VERSION ""

NS_ :

BS_:

BU_: FUSION ZONE_FR ZONE_DR DKC

BO_ 278 FD_VCU1: 32 FUSION
 SG_ CS_VCU1_CAN4 : 7|8@0+ (1,0) [0|255] "" ZONE_FR,ZONE_DR
 SG_ RC_VCU1_CAN4 : 11|4@0+ (1,0) [0|15] "" ZONE_FR,ZONE_DR
 SG_ Dr_SeatSta : 23|2@0+ (1,0) [0|2] "" ZONE_FR,ZONE_DR,DKC
 SG_ MSA_Crl_Sta : 21|3@0+ (1,0) [0|7] "" ZONE_FR,ZONE_DR
 SG_ CC_Crl_Sta : 18|3@0+ (1,0) [0|7] "" ZONE_FR,ZONE_DR
 SG_ ShiftGearPosn : 31|3@0+ (1,0) [0|7] "" ZONE_FR,ZONE_DR
 SG_ PwrSta : 28|3@0+ (1,0) [0|5] "" ZONE_FR,ZONE_DR,DKC
 SG_ ReBrakeLPReq : 25|1@0+ (1,0) [0|1] "" ZONE_FR,ZONE_DR
 SG_ DKCTimeSN : 39|32@0+ (1,0) [0|4.294967295E9] "" ZONE_FR,ZONE_DR,DKC
 SG_ TimeSNDKCFbk : 71|32@0+ (1,0) [0|4.294967295E9] "" ZONE_FR,ZONE_DR,DKC
 SG_ EquivAccPedalSWSta : 102|1@0+ (1,0) [0|1] "" ZONE_FR,ZONE_DR
 SG_ HornCtrl : 101|1@0+ (1,0) [0|1] "" ZONE_FR,ZONE_DR
 SG_ BCM_DoorLock_Sta : 100|1@0+ (1,0) [0|1] "" ZONE_FR,ZONE_DR,DKC
 SG_ DimmerEN : 99|1@0+ (1,0) [0|1] "" ZONE_FR,ZONE_DR
 SG_ RoomLampH : 98|1@0+ (1,0) [0|1] "" ZONE_FR,ZONE_DR
 SG_ RoomLampL : 97|1@0+ (1,0) [0|1] "" ZONE_FR,ZONE_DR
 SG_ TailgateRemote : 96|2@0+ (1,0) [0|3] "" ZONE_FR,ZONE_DR
 SG_ BCM_Buzzer_Req : 110|1@0+ (1,0) [0|1] "" ZONE_FR,ZONE_DR
 SG_ LockSetting : 109|1@0+ (1,0) [0|1] "" ZONE_FR,ZONE_DR
 SG_ Dimmer : 108|7@0+ (1,0) [0|100] "%" ZONE_FR,ZONE_DR
 SG_ L_APM_WdwEnable : 117|1@0+ (1,0) [0|1] "" ZONE_FR,ZONE_DR
 SG_ CrashDetd : 116|1@0+ (1,0) [0|1] "" ZONE_FR,ZONE_DR
 SG_ AntiTheftSeatFold : 115|1@0+ (1,0) [0|1] "" ZONE_FR,ZONE_DR
 SG_ AntitheftSta : 114|2@0+ (1,0) [0|3] "" ZONE_FR,ZONE_DR,DKC
 SG_ RTurnLP : 112|1@0+ (1,0) [0|1] "" ZONE_FR,ZONE_DR
 SG_ LTurnLP : 127|1@0+ (1,0) [0|1] "" ZONE_FR,ZONE_DR
 SG_ HazardSW : 126|1@0+ (1,0) [0|1] "" ZONE_FR,ZONE_DR
 SG_ Rr_FogLamp : 125|1@0+ (1,0) [0|1] "" ZONE_FR,ZONE_DR
 SG_ Fr_FogLamp : 124|1@0+ (1,0) [0|1] "" ZONE_FR,ZONE_DR
 SG_ RBSD : 123|1@0+ (1,0) [0|1] "" ZONE_FR,ZONE_DR
 SG_ LBSD : 122|1@0+ (1,0) [0|1] "" ZONE_FR,ZONE_DR
 SG_ BrakeLamp : 121|1@0+ (1,0) [0|1] "" ZONE_FR,ZONE_DR
 SG_ ReverseLamp : 120|1@0+ (1,0) [0|1] "" ZONE_FR,ZONE_DR
 SG_ RDRL : 135|1@0+ (1,0) [0|1] "" ZONE_FR,ZONE_DR
 SG_ LDRL : 134|1@0+ (1,0) [0|1] "" ZONE_FR,ZONE_DR
 SG_ PosLamp : 133|1@0+ (1,0) [0|1] "" ZONE_FR,ZONE_DR
 SG_ H_Beam : 132|1@0+ (1,0) [0|1] "" ZONE_FR,ZONE_DR
 SG_ L_Beam : 131|1@0+ (1,0) [0|1] "" ZONE_FR,ZONE_DR
 SG_ WasherCtrl : 130|2@0+ (1,0) [0|3] "" ZONE_FR,ZONE_DR
 SG_ WiperFixMode : 128|1@0+ (1,0) [0|1] "" ZONE_FR,ZONE_DR
 SG_ Rr_Wiper : 143|1@0+ (1,0) [0|1] "" ZONE_FR,ZONE_DR
 SG_ Fr_Wiper_L : 142|1@0+ (1,0) [0|1] "" ZONE_FR,ZONE_DR
 SG_ Fr_Wiper_H : 141|1@0+ (1,0) [0|1] "" ZONE_FR,ZONE_DR
 SG_ MirrorCtrl : 140|2@0+ (1,0) [0|3] "" ZONE_FR,ZONE_DR
 SG_ TailgateHDSW : 138|1@0+ (1,0) [0|1] "" ZONE_FR,ZONE_DR,DKC
 SG_ TrunkRel : 137|1@0+ (1,0) [0|1] "" ZONE_FR,ZONE_DR
 SG_ Rr_Defog : 136|1@0+ (1,0) [0|1] "" ZONE_FR,ZONE_DR
 SG_ MirrorDefog : 151|1@0+ (1,0) [0|1] "" ZONE_FR,ZONE_DR
 SG_ CTDUnlockSW : 150|1@0+ (1,0) [0|1] "" ZONE_FR,ZONE_DR
 SG_ CTDLockSW : 149|1@0+ (1,0) [0|1] "" ZONE_FR,ZONE_DR
 SG_ Rr_ChargingDoorCtrl : 148|2@0+ (1,0) [0|3] "" ZONE_FR,ZONE_DR
 SG_ Fr_ChargingDoorCtrl : 146|2@0+ (1,0) [0|3] "" ZONE_FR,ZONE_DR
 SG_ CTDCtrl : 144|2@0+ (1,0) [0|3] "" ZONE_FR,ZONE_DR
 SG_ Tailgate_SW : 158|1@0+ (1,0) [0|1] "" ZONE_FR,ZONE_DR,DKC
 SG_ HoodSW : 157|1@0+ (1,0) [0|1] "" ZONE_FR,ZONE_DR,DKC
 SG_ DoorLockIND : 156|1@0+ (1,0) [0|1] "" ZONE_FR,ZONE_DR
 SG_ AllDoorSW : 155|1@0+ (1,0) [0|1] "" ZONE_FR,ZONE_DR,DKC
 SG_ RRDoorSW : 154|1@0+ (1,0) [0|1] "" ZONE_FR,ZONE_DR,DKC
 SG_ RLDoorSW : 153|1@0+ (1,0) [0|1] "" ZONE_FR,ZONE_DR,DKC
 SG_ PsDoorSW : 152|1@0+ (1,0) [0|1] "" ZONE_FR,ZONE_DR,DKC
 SG_ DrDoorSW : 167|1@0+ (1,0) [0|1] "" ZONE_FR,ZONE_DR,DKC
 SG_ FD_TBOX_VehData_Sta : 166|4@0+ (1,0) [0|7] "" ZONE_FR,ZONE_DR
 SG_ FD_TBOX_VehData_Err : 162|4@0+ (1,0) [0|7] "" ZONE_FR,ZONE_DR
 SG_ FD_DKC_VehData_Sta : 174|4@0+ (1,0) [0|7] "" ZONE_FR,ZONE_DR,DKC
 SG_ FD_DKC_VehData_Err : 170|4@0+ (1,0) [0|7] "" ZONE_FR,ZONE_DR,DKC
 SG_ FD_TBOX_DTCData_Sta : 182|4@0+ (1,0) [0|7] "" ZONE_FR,ZONE_DR
 SG_ FD_TBOX_DTCData_Err : 178|4@0+ (1,0) [0|7] "" ZONE_FR,ZONE_DR
 SG_ AmbLightBreath3 : 190|1@0+ (1,0) [0|1] "" ZONE_FR,ZONE_DR
 SG_ AmbLightBreath2 : 189|1@0+ (1,0) [0|1] "" ZONE_FR,ZONE_DR
 SG_ LampPwr : 188|1@0+ (1,0) [0|1] "" ZONE_FR,ZONE_DR
 SG_ AmbLightBreath1 : 187|1@0+ (1,0) [0|1] "" ZONE_FR,ZONE_DR
 SG_ DKCAuthSta : 185|2@0+ (1,0) [0|3] "" ZONE_FR,ZONE_DR,DKC
 SG_ AmbLightColor3 : 197|6@0+ (1,0) [0|63] "" ZONE_FR,ZONE_DR
 SG_ AmbLightColor2 : 205|6@0+ (1,0) [0|63] "" ZONE_FR,ZONE_DR
 SG_ AmbLightColor1 : 213|6@0+ (1,0) [0|63] "" ZONE_FR,ZONE_DR
 SG_ AmbLightBrightness3 : 222|7@0+ (1,0) [0|127] "" ZONE_FR,ZONE_DR
 SG_ AmbLightBrightness2 : 230|7@0+ (1,0) [0|127] "" ZONE_FR,ZONE_DR
 SG_ AmbLightBrightness1 : 238|7@0+ (1,0) [0|127] "" ZONE_FR,ZONE_DR
 SG_ VehSpeed : 243|12@0+ (0.125,0) [0|255.875] "km/h" ZONE_FR,ZONE_DR,DKC
 SG_ HWResetSta : 207|2@0+ (1,0) [0|3] "" ZONE_FR,ZONE_DR
 SG_ CtrlFrPwrStbA1P : 215|1@0+ (1,0) [0|1] "" ZONE_FR
 SG_ CtrlFrIRC1 : 223|1@0+ (1,0) [0|1] "" ZONE_FR
 SG_ CtrlFrBMSCCUCIR : 239|1@0+ (1,0) [0|1] "" ZONE_FR
 SG_ CtrlFrEDUINVERTER : 231|1@0+ (1,0) [0|1] "" ZONE_FR
 SG_ CtrlDrPwrStbA2 : 214|1@0+ (1,0) [0|1] "" ZONE_DR

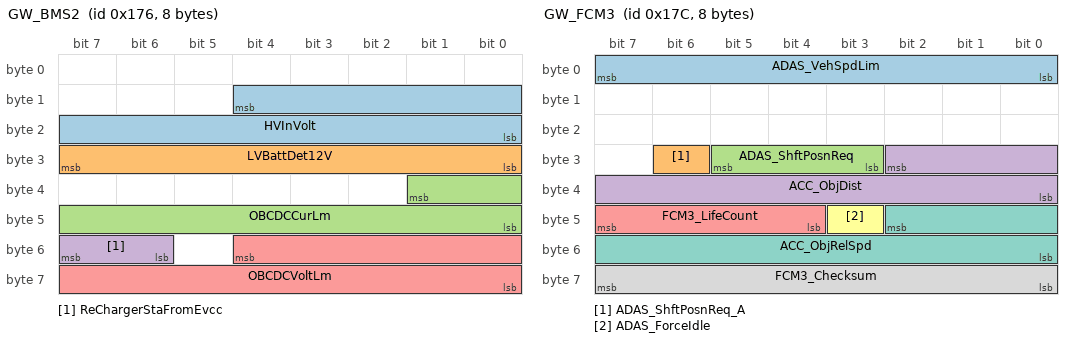
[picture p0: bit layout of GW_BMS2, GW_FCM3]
BO_ 374 GW_BMS2: 8 FUSION
 SG_ HVInVolt : 12|13@0+ (0.1,0) [0|819] "V" ZONE_DR
 SG_ LVBattDet12V : 31|8@0+ (0.1,0) [0|25.4] "V" ZONE_DR
 SG_ OBCDCCurLm : 33|10@0+ (0.1,-25.5) [-25.5|76.7] "A" ZONE_DR
 SG_ ReChargerStaFromEvcc : 55|2@0+ (1,0) [0|3] "" ZONE_DR
 SG_ OBCDCVoltLm : 52|13@0+ (0.1,0) [0|819] "V" ZONE_DR

BO_ 378 GW_BMS6: 12 FUSION
 SG_ BMSChckSum : 7|8@0+ (1,0) [0|255] "" Vector__XXX
 SG_ BMSRolCnct : 15|4@0+ (1,0) [0|15] "" Vector__XXX
 SG_ V2LSta : 25|2@0+ (1,0) [0|3] "" Vector__XXX
 SG_ HVBChrgErr : 39|8@0+ (1,0) [0|255] "" Vector__XXX
 SG_ DisChrgPlugErr : 47|2@0+ (1,0) [0|3] "" Vector__XXX
 SG_ ChrgInLockReq : 45|2@0+ (1,0) [0|2] "" ZONE_FR
 SG_ HVBCellUnbalanErr : 42|1@0+ (1,0) [0|1] "" Vector__XXX
 SG_ HVBCellUndrVoltErr : 41|1@0+ (1,0) [0|1] "" Vector__XXX
 SG_ HVBCellOvrVoltErr : 40|1@0+ (1,0) [0|1] "" Vector__XXX
 SG_ HVBCellUdrVoltWarn : 55|2@0+ (1,0) [0|2] "" Vector__XXX
 SG_ HVBCellOvrVoltWarn : 53|2@0+ (1,0) [0|2] "" Vector__XXX
 SG_ CellUnconsistErr : 50|1@0+ (1,0) [0|1] "" Vector__XXX
 SG_ SystemUncomErr : 49|1@0+ (1,0) [0|1] "" Vector__XXX
 SG_ IsoDetSta : 48|1@0+ (1,0) [0|1] "" Vector__XXX
 SG_ HVBPreheatPrecoolSta : 63|2@0+ (1,0) [0|2] "" Vector__XXX
 SG_ ExtChrgSta : 61|2@0+ (1,0) [0|3] "" Vector__XXX
 SG_ ChrgPlugSta : 59|2@0+ (1,0) [0|3] "" Vector__XXX
 SG_ HVBattReady4Pre : 57|2@0+ (1,0) [0|2] "" Vector__XXX
 SG_ HVILSta : 71|1@0+ (1,0) [0|1] "" Vector__XXX
 SG_ HVBTempDiffErr : 70|1@0+ (1,0) [0|1] "" Vector__XXX
 SG_ HVBPrechrgSta : 69|2@0+ (1,0) [0|3] "" Vector__XXX
 SG_ HVBContactorSta : 66|1@0+ (1,0) [0|1] "" Vector__XXX
 SG_ BMS_READY : 65|1@0+ (1,0) [0|1] "" Vector__XXX
 SG_ DCChrgSysShockErr : 64|1@0+ (1,0) [0|1] "" Vector__XXX
 SG_ HVBHVILErr : 79|1@0+ (1,0) [0|1] "" Vector__XXX
 SG_ HVBSOCJumpError : 78|1@0+ (1,0) [0|1] "" Vector__XXX
 SG_ HVBUndrSOCErr : 77|1@0+ (1,0) [0|1] "" Vector__XXX
 SG_ HVBOvrSOCErr : 76|1@0+ (1,0) [0|1] "" Vector__XXX
 SG_ HVBUndrTempErr : 75|1@0+ (1,0) [0|1] "" Vector__XXX
 SG_ HVBOvrTempErr : 74|1@0+ (1,0) [0|1] "" Vector__XXX
 SG_ HVBOvrDchrgCurErr : 73|1@0+ (1,0) [0|1] "" Vector__XXX
 SG_ HVBOvrChrgCurrErr : 72|1@0+ (1,0) [0|1] "" Vector__XXX
 SG_ HVBShrtDischrgCurrErr : 87|1@0+ (1,0) [0|1] "" Vector__XXX
 SG_ HVBShrtChrgCurrErr : 86|1@0+ (1,0) [0|1] "" Vector__XXX
 SG_ HVBUndrVoltErr : 85|1@0+ (1,0) [0|1] "" Vector__XXX
 SG_ HVBOvrVoltErr : 84|1@0+ (1,0) [0|1] "" Vector__XXX
 SG_ HVBUndrTempWarn : 83|2@0+ (1,0) [0|2] "" Vector__XXX
 SG_ HVBOvrTempWarn : 81|2@0+ (1,0) [0|2] "" Vector__XXX
 SG_ BMS_Warn_8 : 95|1@0+ (1,0) [0|1] "" Vector__XXX
 SG_ BMS_Warn_7 : 94|1@0+ (1,0) [0|1] "" Vector__XXX
 SG_ BMS_Warn_6 : 93|1@0+ (1,0) [0|1] "" Vector__XXX
 SG_ BMS_Warn_5 : 92|1@0+ (1,0) [0|1] "" Vector__XXX
 SG_ BMS_Warn_4 : 91|1@0+ (1,0) [0|1] "" Vector__XXX
 SG_ BMS_Warn_3 : 90|1@0+ (1,0) [0|1] "" Vector__XXX
 SG_ BMS_Warn_2 : 89|1@0+ (1,0) [0|1] "" Vector__XXX
 SG_ BMS_Warn_1 : 88|1@0+ (1,0) [0|1] "" Vector__XXX

BO_ 380 GW_FCM3: 8 FUSION
 SG_ ADAS_VehSpdLim : 7|8@0+ (1,0) [0|254] "" ZONE_DR
 SG_ ADAS_ShftPosnReq_A : 30|1@0+ (1,0) [0|1] "" Vector__XXX
 SG_ ADAS_ShftPosnReq : 29|3@0+ (1,0) [0|7] "" Vector__XXX
 SG_ ACC_ObjDist : 26|11@0+ (0.1,0) [0|204.6] "m" Vector__XXX
 SG_ FCM3_LifeCount : 47|4@0+ (1,0) [0|15] "" Vector__XXX
 SG_ ADAS_ForceIdle : 43|1@0+ (1,0) [0|1] "" Vector__XXX
 SG_ ACC_ObjRelSpd : 42|11@0+ (0.1,-100) [-100|104.6] "m/s" Vector__XXX
 SG_ FCM3_Checksum : 63|8@0+ (1,0) [0|255] "" Vector__XXX

BO_ 386 FD_THCM1: 20 FUSION
 SG_ CCU_HEATMaxLampSts : 7|1@0+ (1,0) [0|1] "" Vector__XXX
 SG_ CCU_ACLampSts : 6|1@0+ (1,0) [0|1] "" Vector__XXX
 SG_ CCU_Dispaly_Request : 5|1@0+ (1,0) [0|1] "" Vector__XXX
 SG_ CCU_EcoSts : 4|1@0+ (1,0) [0|1] "" Vector__XXX
 SG_ CCU_AutoMidLampSts : 3|1@0+ (1,0) [0|1] "" Vector__XXX
 SG_ CCU_AutoLampSts : 2|1@0+ (1,0) [0|1] "" Vector__XXX
 SG_ CCU_ACMaxLampSts : 1|1@0+ (1,0) [0|1] "" Vector__XXX
 SG_ Fr_Coolanttemp : 0|9@0+ (1,-40) [-40|214] "Deg^C" Vector__XXX
 SG_ CCU_RrOnOffLampSts : 23|1@0+ (1,0) [0|1] "" Vector__XXX
 SG_ sigWindDirZon1St : 22|3@0+ (1,0) [0|7] "" ZONE_DR
 SG_ CCU_FrtOnOffLampSts : 19|1@0+ (1,0) [0|1] "" Vector__XXX
 SG_ sigWindDirZon3St : 18|3@0+ (1,0) [0|7] "" Vector__XXX
 SG_ sigAirIntenZon1St : 31|4@0+ (1,0) [0|15] "" Vector__XXX
 SG_ sigAirIntenZon3St : 27|4@0+ (1,0) [0|15] "" Vector__XXX
 SG_ CCU_SyncLampSts : 39|1@0+ (1,0) [0|1] "" Vector__XXX
 SG_ sigDfrstSt : 38|1@0+ (1,0) [0|1] "" Vector__XXX
 SG_ sigSetTempZon3St : 37|6@0+ (0.5,17) [17|32] "Deg^C" Vector__XXX
 SG_ sigRecircSt : 47|1@0+ (1,0) [0|1] "" ZONE_DR
 SG_ sigHvacSt : 46|1@0+ (1,0) [0|1] "" Vector__XXX
 SG_ sigSetTempZon2St : 45|6@0+ (0.5,17) [17|32] "Deg^C" Vector__XXX
 SG_ HPThermalRecoveryReq : 55|2@0+ (1,0) [0|1] "" Vector__XXX
 SG_ sigSetTempZon1St : 53|6@0+ (0.5,17) [17|32] "Deg^C" Vector__XXX
 SG_ EDriveMode : 63|2@0+ (1,0) [0|2] "" Vector__XXX
 SG_ Fr_Coolantflow : 61|6@0+ (0.25,0) [0|15.75] "L/min" Vector__XXX
 SG_ sigClmtCmprPwrAct : 71|8@0+ (50,0) [0|12650] "W" Vector__XXX
 SG_ sigCbnPTCPwrAct : 79|8@0+ (50,0) [0|12650] "W" Vector__XXX
 SG_ sigCbnAirT : 87|8@0+ (0.5,-40) [-40|85] "Deg^C" Vector__XXX
 SG_ sigAmbAirT : 95|8@0+ (0.5,-40) [-40|85] "Deg^C" ZONE_FR
 SG_ sigCbnSolarRight : 103|8@0+ (5,0) [0|1265] "W" Vector__XXX
 SG_ FD_RecyAuto_Cmd : 111|3@0+ (1,0) [0|6] "" ZONE_DR
 SG_ BatteryMode : 118|3@0+ (1,0) [0|5] "" Vector__XXX
 SG_ CabinMode : 115|4@0+ (1,0) [0|9] "" ZONE_DR
 SG_ sigCbnSolarLeft : 127|8@0+ (5,0) [0|1265] "W" Vector__XXX
 SG_ sigClntTHvBattOut : 135|8@0+ (0.5,-40) [-40|85] "Deg^C" Vector__XXX
 SG_ FD_AGS_Cmd : 143|8@0+ (1,0) [0|255] "" ZONE_FR
 SG_ Rr_Coolantflow : 150|6@0+ (0.25,0) [0|15.75] "L/min" Vector__XXX
 SG_ Rr_Coolanttemp : 144|9@0+ (1,-40) [-40|214] "Deg^C" Vector__XXX

BO_ 390 FD_THCM2: 20 FUSION
 SG_ FD_Blower_Cmd : 7|8@0+ (0.8,0) [0|200] "%" ZONE_DR
 SG_ FD_SOV3_Cmd : 15|1@0+ (1,0) [0|1] "" ZONE_FR
 SG_ FD_SOV2_Cmd : 14|1@0+ (1,0) [0|1] "" ZONE_FR
 SG_ FD_SOV1_Cmd : 13|1@0+ (1,0) [0|1] "" ZONE_FR
 SG_ FD_SOTXV_Cmd : 12|1@0+ (1,0) [0|1] "" ZONE_FR
 SG_ ACSubMode : 11|3@0+ (1,0) [0|7] "" ZONE_FR,ZONE_DR
 SG_ FD_FWV_Cmd : 8|1@0+ (1,0) [0|1] "" ZONE_FR
 SG_ CCU_HiVoltageReq : 23|1@0+ (1,0) [0|1] "" Vector__XXX
 SG_ FD_Comp_Cmd : 22|15@0+ (0.5,0) [0|8300] "RPM" ZONE_FR
 SG_ CCU_CbnPreSts : 39|2@0+ (1,0) [0|3] "" Vector__XXX
 SG_ DeiceModReq : 37|2@0+ (1,0) [0|3] "" Vector__XXX
 SG_ CCU_CbnPreACWkSts : 35|2@0+ (1,0) [0|3] "" Vector__XXX
 SG_ FD_EXV1_Cmd : 33|10@0+ (1,0) [0|576] "step" ZONE_FR
 SG_ CCU_CbnPreEstimdTi : 55|6@0+ (1,0) [0|63] "" Vector__XXX
 SG_ FD_EXV2_Cmd : 49|10@0+ (1,0) [0|576] "step" ZONE_FR
 SG_ FD_TWV_Cmd : 71|8@0+ (0.392,0) [0|99.96] "%" ZONE_FR
 SG_ FD_FrRiAPTCHeatPwr_Cmd : 79|8@0+ (25,0) [0|6375] "W" ZONE_DR
 SG_ FD_FrLeAPTCHeatPwr_Cmd : 87|8@0+ (25,0) [0|6375] "W" ZONE_DR
 SG_ FD_RrAPTCHeatPwr_Cmd : 95|8@0+ (25,0) [0|6375] "W" ZONE_DR
 SG_ FD_FrWPTCHeatPwr_Cmd : 103|16@0+ (1,0) [0|65535] "W" ZONE_FR
 SG_ FD_EWP3_Cmd : 119|8@0+ (1,0) [0|255] "" ZONE_FR
 SG_ FD_EWP2_Cmd : 127|8@0+ (1,0) [0|255] "" ZONE_FR
 SG_ FD_EWP1_Cmd : 135|8@0+ (1,0) [0|255] "" ZONE_FR
 SG_ APTC_ActFrRiPwr : 143|8@0+ (25,0) [0|6375] "W" Vector__XXX
 SG_ BatLoopActWtFlw : 151|8@0+ (0.1,-5) [-5|20] "L/min" Vector__XXX
 SG_ CoolgFanActDuty : 159|8@0+ (0.5,0) [0|100] "%" ZONE_FR

BO_ 497 Zone_Dr_VCU: 20 ZONE_DR
 SG_ DrPMMSysErrLmp : 15|1@0+ (1,0) [0|1] "" FUSION
 SG_ DrPMMLVOutPErrLmp : 14|1@0+ (1,0) [0|1] "" FUSION
 SG_ DrPMMLimpHomeActReq : 13|1@0+ (1,0) [0|1] "" FUSION
 SG_ DrIVIFault : 11|2@0+ (1,0) [0|2] "" FUSION
 SG_ DrEOBDFault : 9|2@0+ (1,0) [0|2] "" FUSION
 SG_ DrInfoFault : 23|2@0+ (1,0) [0|2] "" FUSION
 SG_ DrPwrWindowECUFault : 21|2@0+ (1,0) [0|2] "" FUSION
 SG_ DrTHCMFault : 19|2@0+ (1,0) [0|2] "" FUSION
 SG_ DrColumnSWFault : 17|2@0+ (1,0) [0|2] "" FUSION
 SG_ DrAuBoxPwrN2Curr : 39|8@0+ (0.125,0) [0|31.875] "A" FUSION
 SG_ DrAuBoxPwrN1Curr : 47|8@0+ (0.125,0) [0|31.875] "A" FUSION
 SG_ DrPwrStdbyACurr : 55|8@0+ (0.125,0) [0|31.875] "A" FUSION
 SG_ DrPwrONA2Curr : 63|8@0+ (0.125,0) [0|31.875] "A" FUSION
 SG_ DrPwrONA1Curr : 71|8@0+ (0.125,0) [0|31.875] "A" FUSION
 SG_ DrCtrlBDVolt : 75|12@0+ (0.01,0) [0|36] "V" FUSION
 SG_ DrCtrlTemp : 95|16@0+ (0.01,-40) [-40|125] "Deg^C" FUSION
 SG_ DrPowerTemp1 : 111|16@0+ (0.01,-40) [-40|125] "Deg^C" FUSION
 SG_ DrPowerTemp2 : 127|16@0+ (0.01,-40) [-40|125] "Deg^C" FUSION
 SG_ DrPwrSta : 78|3@0+ (1,0) [0|5] "" FUSION
 SG_ DrPwrInformationSta : 79|1@0+ (1,0) [0|1] "" FUSION
 SG_ DrAPWStaErr : 7|1@0+ (1,0) [0|1] "" FUSION
 SG_ DrAPWLINErr : 6|1@0+ (1,0) [0|1] "" FUSION
 SG_ DrONA1ErrSta : 5|1@0+ (1,0) [0|1] "" FUSION
 SG_ DrStdAErrSta : 4|1@0+ (1,0) [0|1] "" FUSION
 SG_ DrPwrWinErrSta : 3|1@0+ (1,0) [0|1] "" FUSION
 SG_ DrInfoErrSta : 12|1@0+ (1,0) [0|1] "" FUSION
 SG_ ZoneDrMalfunLevel : 2|3@0+ (1,0) [0|5] "" FUSION
 SG_ ZDR_SYS_APMRetryCnt_Sta : 31|8@0+ (1,0) [0|255] "" FUSION
 SG_ ZDR_SYS_CSWRetryCnt_Sta : 143|8@0+ (1,0) [0|255] "" FUSION
 SG_ ZDR_SYS_BSWSleepReq_Sta : 150|1@0+ (1,0) [0|1] "" FUSION
 SG_ ZDR_VCU_HWReset_Sta : 148|5@0+ (1,0) [0|31] "" FUSION
 SG_ ZDR_VCU_PwrSupply_Sta : 149|1@0+ (1,0) [0|1] "" FUSION

BO_ 498 Zone_Fr_VCU: 24 ZONE_FR
 SG_ FrPwrStdbyA2PlusCurr : 7|8@0+ (0.125,0) [0|31.875] "A" FUSION
 SG_ FrBMS_CCU_CIRCurr : 15|8@0+ (0.125,0) [0|31.875] "A" FUSION
 SG_ FrEDU_INVERTERCurr : 23|8@0+ (0.125,0) [0|31.875] "A" FUSION
 SG_ FrPwrStdbyA1PlusFault : 31|3@0+ (1,0) [0|7] "" FUSION
 SG_ FrPwrStdbyA2PlusFault : 28|3@0+ (1,0) [0|7] "" FUSION
 SG_ FrPwrONA1Fault : 25|2@0+ (1,0) [0|2] "" FUSION
 SG_ FrBMS_CCU_CIRFault : 39|3@0+ (1,0) [0|7] "" FUSION
 SG_ FrEDU_INVERTERFault : 36|3@0+ (1,0) [0|7] "" FUSION
 SG_ FrPwrStdbyA1Fault : 33|2@0+ (1,0) [0|2] "" FUSION
 SG_ FrPMMSysErrLmp : 47|1@0+ (1,0) [0|1] "" FUSION
 SG_ FrPMMLVOutPErrLmp : 46|1@0+ (1,0) [0|1] "" FUSION
 SG_ FrPMMLimpHomeActReq : 45|1@0+ (1,0) [0|1] "" FUSION
 SG_ FrIRC_1Curr : 41|10@0+ (1,0) [0|1023] "mA" FUSION
 SG_ FrPwrStdbyA2Curr : 63|8@0+ (0.125,0) [0|31.875] "A" FUSION
 SG_ FrPwrONA3Curr : 71|8@0+ (0.125,0) [0|31.875] "A" FUSION
 SG_ FrPwrONA2Curr : 79|8@0+ (0.125,0) [0|31.875] "A" FUSION
 SG_ FrIRC_2Curr : 81|10@0+ (1,0) [0|1023] "mA" FUSION
 SG_ FrPwrStdbyA1PlusCurr : 103|8@0+ (0.125,0) [0|31.875] "A" FUSION
 SG_ FrCtrlBDVolt : 107|12@0+ (0.01,0) [0|36] "V" FUSION
 SG_ FrCtrlTemp : 127|16@0+ (0.01,-40) [-40|125] "Deg^C" FUSION
 SG_ FrPowerTemp2 : 143|16@0+ (0.01,-40) [-40|125] "Deg^C" FUSION
 SG_ FrPowerTemp1 : 159|16@0+ (0.01,-40) [-40|125] "Deg^C" FUSION
 SG_ ZFR_SYS_BMSCCURetryCnt_Sta : 175|8@0+ (1,0) [0|255] "" FUSION
 SG_ ZFR_SYS_MCURetryCnt_Sta : 183|8@0+ (1,0) [0|255] "" FUSION
 SG_ ZoneFrMalfunLevel : 44|3@0+ (1,0) [0|5] "" FUSION
 SG_ ZFR_SYS_BSWSleepReq_Sta : 87|1@0+ (1,0) [0|1] "" FUSION
 SG_ FrStdA1PCErr : 86|1@0+ (1,0) [0|1] "" FUSION
 SG_ FrStdA2PCErr : 85|1@0+ (1,0) [0|1] "" FUSION
 SG_ FrStdA2PErr : 84|1@0+ (1,0) [0|1] "" FUSION
 SG_ FrBMSCCUCErr : 83|1@0+ (1,0) [0|1] "" FUSION
 SG_ FrEDUErr : 82|1@0+ (1,0) [0|1] "" FUSION
 SG_ FrPwrSta : 110|3@0+ (1,0) [0|5] "" FUSION
 SG_ ZFR_VCU_HWReset_Sta : 188|5@0+ (1,0) [0|31] "" FUSION
 SG_ ZFR_VCU_PwrSupply_Sta : 111|1@0+ (1,0) [0|1] "" FUSION

BO_ 547 GW_ZoneDR6: 24 ZONE_DR
 SG_ FrntPTCSts : 7|1@0+ (1,0) [0|1] "" FUSION
 SG_ FrntPTCFltSt : 6|2@0+ (1,0) [0|3] "" FUSION
 SG_ FrntPTCLVUnderUFlt : 4|1@0+ (1,0) [0|1] "" FUSION
 SG_ FrntPTCLVOverUFlt : 3|1@0+ (1,0) [0|1] "" FUSION
 SG_ FrntPTCHVUnderUFlt : 2|1@0+ (1,0) [0|1] "" FUSION
 SG_ FrntPTCHVOverUFlt : 1|1@0+ (1,0) [0|1] "" FUSION
 SG_ FrntPTCLeOverAFlt : 0|1@0+ (1,0) [0|1] "" FUSION
 SG_ FrntPTCRiOverAFlt : 15|1@0+ (1,0) [0|1] "" FUSION
 SG_ FrntPTCLeCoreTSnsrFlt : 14|1@0+ (1,0) [0|1] "" FUSION
 SG_ FrntPTCRiCoreTSnsrFlt : 13|1@0+ (1,0) [0|1] "" FUSION
 SG_ FrntPTCLeCoreOverTFlt : 12|1@0+ (1,0) [0|1] "" FUSION
 SG_ FrntPTCRiCoreOverTFlt : 11|1@0+ (1,0) [0|1] "" FUSION
 SG_ FrntPTCLeIGBTShoCircFlt : 10|1@0+ (1,0) [0|1] "" FUSION
 SG_ FrntPTCRiIGBTShoCircFlt : 9|1@0+ (1,0) [0|1] "" FUSION
 SG_ FrntPTCLeOpentCircFlt : 8|1@0+ (1,0) [0|1] "" FUSION
 SG_ FrntPTCRiOpentCircFlt : 23|1@0+ (1,0) [0|1] "" FUSION
 SG_ FrntPTCPCBTSnsrFlt : 22|1@0+ (1,0) [0|1] "" FUSION
 SG_ FrntPTCPCBOverTFlt : 21|1@0+ (1,0) [0|1] "" FUSION
 SG_ FrntPTCComFlt : 20|1@0+ (1,0) [0|1] "" FUSION
 SG_ FrntPTCLeIGBTTSnsrFlt : 19|1@0+ (1,0) [0|1] "" FUSION
 SG_ FrntPTCRiIGBTTSnsrFlt : 18|1@0+ (1,0) [0|1] "" FUSION
 SG_ FrntPTCLeIGBTOverTFlt : 17|1@0+ (1,0) [0|1] "" FUSION
 SG_ FrntPTCRiIGBTOverTFlt : 16|1@0+ (1,0) [0|1] "" FUSION
 SG_ FrntPTCSWVers : 31|8@0+ (1,0) [0|255] "" FUSION
 SG_ FrntPTCHWVers : 39|8@0+ (1,0) [0|255] "" FUSION
 SG_ FrntPTCSupplierCod : 47|4@0+ (1,0) [0|15] "" FUSION
 SG_ FrntPTCRearLeOverAFlt : 43|1@0+ (1,0) [0|1] "" FUSION
 SG_ FrntPTCRearLeOpentCircFlt : 42|1@0+ (1,0) [0|1] "" FUSION
 SG_ FrntPTCRearRiCoreOverTFlt : 41|1@0+ (1,0) [0|1] "" FUSION
 SG_ FrntPTCRearLeCoreOverTFlt : 40|1@0+ (1,0) [0|1] "" FUSION
 SG_ FrntPTCRearRiCoreTSnsrFlt : 55|1@0+ (1,0) [0|1] "" FUSION
 SG_ FrntPTCRearLeCoreTSnsrFlt : 54|1@0+ (1,0) [0|1] "" FUSION
 SG_ FrntPTCRearRiOverAFlt : 53|1@0+ (1,0) [0|1] "" FUSION
 SG_ FrntPTCRearRiOpentCircFlt : 52|1@0+ (1,0) [0|1] "" FUSION
 SG_ FrntPTCRearRiIGBTShoCFlt : 51|1@0+ (1,0) [0|1] "" FUSION
 SG_ FrntPTCRearLeIGBTShoCFlt : 50|1@0+ (1,0) [0|1] "" FUSION
 SG_ FrntPTCRearLeBusLineC : 63|8@0+ (0.1,0) [0|25.5] "A" FUSION
 SG_ FrntPTCLeCoreT : 71|8@0+ (1,-40) [-40|215] "Deg^C" FUSION
 SG_ FrntPTCRiCoreT : 79|8@0+ (1,-40) [-40|215] "Deg^C" FUSION
 SG_ FrntPTCLeActHeatPwr : 87|8@0+ (25,0) [0|6375] "W" FUSION
 SG_ FrntPTCRiActHeatPwr : 95|8@0+ (25,0) [0|6375] "W" FUSION
 SG_ FrntPTCLeIGBTT : 103|8@0+ (1,-40) [-40|215] "Deg^C" FUSION
 SG_ FrntPTCRiIGBTT : 111|8@0+ (1,-40) [-40|215] "Deg^C" FUSION
 SG_ FrntPTCPCBT : 119|8@0+ (1,-40) [-40|215] "Deg^C" FUSION
 SG_ FrntPTCRearRiBusLineC : 127|8@0+ (0.1,0) [0|25.5] "A" FUSION
 SG_ FrntPTCRearLeActHeatPwr : 135|8@0+ (25,0) [0|6375] "W" FUSION
 SG_ FrntPTCRearLeCoreT : 143|8@0+ (1,-40) [-40|215] "Deg^C" FUSION
 SG_ FrntPTCRearRiActHeatPwr : 151|8@0+ (25,0) [0|6375] "W" FUSION
 SG_ FrntPTCRearRiCoreT : 159|8@0+ (1,-40) [-40|215] "Deg^C" FUSION
 SG_ FrntPTCLeBusLineC : 167|8@0+ (0.1,0) [0|25.5] "A" FUSION
 SG_ FrntPTCRiBusLineC : 175|8@0+ (0.1,0) [0|25.5] "A" FUSION
 SG_ FrntPTCBusLineHiV : 177|10@0+ (1,0) [0|1023] "V" FUSION

BO_ 549 Zone_Dr_THCM: 16 ZONE_DR
 SG_ T_Foot_R : 15|8@0+ (0.5,-40) [-40|85] "Deg^C" FUSION
 SG_ T_Foot_Rr : 23|8@0+ (0.5,-40) [-40|85] "Deg^C" FUSION
 SG_ T_Face_Rr : 31|8@0+ (0.5,-40) [-40|85] "Deg^C" FUSION
 SG_ T_Foot_L : 39|8@0+ (0.5,-40) [-40|85] "Deg^C" FUSION
 SG_ T_Face_R : 47|8@0+ (0.5,-40) [-40|85] "Deg^C" FUSION
 SG_ T_Face_L : 55|8@0+ (0.5,-40) [-40|85] "Deg^C" FUSION
 SG_ Tevap : 63|8@0+ (0.5,-40) [-40|85] "Deg^C" FUSION
 SG_ Blower_FB : 67|4@0+ (12.5,0) [0|100] "%" FUSION
 SG_ Tincar : 79|8@0+ (0.5,-40) [-40|85] "Deg^C" FUSION
 SG_ SolarR : 87|8@0+ (5,0) [0|1265] "W" FUSION
 SG_ SolarL : 95|8@0+ (5,0) [0|1265] "W" FUSION
 SG_ APTC_Err : 111|2@0+ (1,0) [0|2] "" FUSION
 SG_ Blower_Err : 109|2@0+ (1,0) [0|2] "" FUSION
 SG_ T_Foot_Rr_Err : 107|2@0+ (1,0) [0|2] "" FUSION
 SG_ T_Face_Rr_Err : 105|2@0+ (1,0) [0|2] "" FUSION
 SG_ T_Foot_R_Err : 119|2@0+ (1,0) [0|2] "" FUSION
 SG_ T_Face_R_Err : 117|2@0+ (1,0) [0|2] "" FUSION
 SG_ T_Foot_L_Err : 115|2@0+ (1,0) [0|2] "" FUSION
 SG_ T_Face_L_Err : 113|2@0+ (1,0) [0|2] "" FUSION
 SG_ Tincar_Err : 127|2@0+ (1,0) [0|2] "" FUSION
 SG_ Tevap_Err : 125|2@0+ (1,0) [0|2] "" FUSION
 SG_ SolarR_Err : 123|2@0+ (1,0) [0|2] "" FUSION
 SG_ SolarL_Err : 121|2@0+ (1,0) [0|2] "" FUSION
 SG_ ZDR_THCM_IntakeFail_Sta : 7|2@0+ (1,0) [0|2] "" FUSION
 SG_ ZDR_THCM_ModeFail_Sta : 5|2@0+ (1,0) [0|2] "" FUSION
 SG_ ZDR_THCM_LINACT1_Sta : 3|2@0+ (1,0) [0|2] "" FUSION
 SG_ ZDR_THCM_LINACT2_Sta : 1|2@0+ (1,0) [0|2] "" FUSION
 SG_ ZDR_THCM_LINACT3_Sta : 71|2@0+ (1,0) [0|2] "" FUSION
 SG_ ZDR_THCM_LINACT4_Sta : 69|2@0+ (1,0) [0|2] "" FUSION
 SG_ ZDR_THCM_LINACT5_Sta : 103|2@0+ (1,0) [0|2] "" FUSION

BO_ 550 GW_ZoneDR1: 16 ZONE_DR
 SG_ RLS_LIN_Resp_Err : 7|1@0+ (1,0) [0|1] "" FUSION
 SG_ RLS_LightSnrErr : 6|1@0+ (1,0) [0|1] "" FUSION
 SG_ RLS_RainSnrErr : 5|1@0+ (1,0) [0|1] "" FUSION
 SG_ WiperZeroPosSW : 4|1@0+ (1,0) [0|1] "" FUSION
 SG_ AutoLightSW : 3|1@0+ (1,0) [0|1] "" FUSION
 SG_ CSW_resp_error : 2|1@0+ (1,0) [0|1] "" FUSION
 SG_ WiperSWPos : 15|8@0+ (1,0) [0|255] "" FUSION
 SG_ RLS_Lamp_Sta : 23|1@0+ (1,0) [0|1] "" FUSION
 SG_ RLS_RainSnrWiperCmd : 22|3@0+ (1,0) [0|7] "" FUSION
 SG_ CSW_FWipSw_Sta : 18|3@0+ (1,0) [0|7] "" FUSION
 SG_ HornSW : 30|1@0+ (1,0) [0|1] "" FUSION
 SG_ CSW_TurnSw_Sta : 29|2@0+ (1,0) [0|3] "" FUSION
 SG_ CSW_RWasSW_Sta : 27|2@0+ (1,0) [0|3] "" FUSION
 SG_ CSW_FWasSw_Sta : 25|2@0+ (1,0) [0|3] "" FUSION
 SG_ RRTurnLampC : 39|8@0+ (10,0) [0|2550] "mA" FUSION
 SG_ RLTurnLampC : 47|8@0+ (10,0) [0|2550] "mA" FUSION
 SG_ RLS_Exist : 55|1@0+ (1,0) [0|1] "" FUSION
 SG_ CSW_PassSW_Sta : 54|1@0+ (1,0) [0|1] "" FUSION
 SG_ BrakeLampFail : 53|1@0+ (1,0) [0|1] "" FUSION
 SG_ CSW_DimSw : 52|1@0+ (1,0) [0|1] "" FUSION
 SG_ CSW_RWipIntSw_Sta : 51|2@0+ (1,0) [0|3] "" FUSION
 SG_ Wip_Speed : 49|2@0+ (1,0) [0|3] "" FUSION
 SG_ RWiperProtection : 63|1@0+ (1,0) [0|1] "" FUSION
 SG_ RWiperAS : 62|1@0+ (1,0) [0|1] "" FUSION
 SG_ MIRROR_FOLD_SW : 61|1@0+ (1,0) [0|1] "" FUSION
 SG_ AllLockSta : 60|1@0+ (1,0) [0|1] "" FUSION
 SG_ RRLockSta : 59|1@0+ (1,0) [0|1] "" FUSION
 SG_ RLLockSta : 58|1@0+ (1,0) [0|1] "" FUSION
 SG_ PsLockSta : 57|1@0+ (1,0) [0|1] "" FUSION
 SG_ DrLockSta : 56|1@0+ (1,0) [0|1] "" FUSION
 SG_ CSW_HW_version : 71|16@0+ (0.01,0) [0|99.99] "" FUSION
 SG_ CSW_SW_version : 87|16@0+ (0.01,0) [0|99.99] "" FUSION

BO_ 552 GW_ZoneFR1: 20 ZONE_FR
 SG_ AGS_Actual_Position : 7|8@0+ (1,0) [0|240] "" FUSION
 SG_ AGS_Low_Voltage_Error : 15|1@0+ (1,0) [0|1] "" FUSION
 SG_ AGS_Temperature_Error : 14|1@0+ (1,0) [0|1] "" FUSION
 SG_ AGS_Sensor_Error : 13|1@0+ (1,0) [0|1] "" FUSION
 SG_ AGS_Electrical_Error : 12|1@0+ (1,0) [0|1] "" FUSION
 SG_ AGS_Calibration_Indicated : 11|1@0+ (1,0) [0|1] "" FUSION
 SG_ AGS_Calibration_Active : 10|1@0+ (1,0) [0|1] "" FUSION
 SG_ AGS_Actuator_Fault : 9|1@0+ (1,0) [0|1] "" FUSION
 SG_ AGS_Actuator_Blocked : 8|1@0+ (1,0) [0|1] "" FUSION
 SG_ AGS_LINResponse_Error : 23|1@0+ (1,0) [0|1] "" FUSION
 SG_ AGS_Calibration_Enabled : 22|1@0+ (1,0) [0|1] "" FUSION
 SG_ AGS_Position_Request : 31|8@0+ (1,0) [0|255] "" FUSION
 SG_ FRTurnLampC : 47|8@0+ (10,0) [0|2550] "mA" FUSION
 SG_ FLTurnLampC : 55|8@0+ (10,0) [0|2550] "mA" FUSION
 SG_ ChargeInletLockSta : 58|1@0+ (1,0) [0|1] "" FUSION
 SG_ FWiperProtection : 57|1@0+ (1,0) [0|1] "" FUSION
 SG_ FWiperAS : 56|1@0+ (1,0) [0|1] "" FUSION
 SG_ EXV2_Cmd_Set_Rq : 87|16@0+ (1,0) [0|576] "" FUSION
 SG_ EXV_Cmd_Set_Rq : 103|16@0+ (1,0) [0|576] "" FUSION
 SG_ EWP2_RPM_Target_EWP_Rq : 119|8@0+ (1,0) [0|254] "" FUSION
 SG_ BDC_1_ReqMovePos : 127|8@0+ (0.392,0) [0|99.96] "" FUSION
 SG_ EWP3_RPM_Target_EWP_Rq : 135|8@0+ (1,0) [0|254] "" FUSION
 SG_ EWP1_RPM_Target_EWP_Rq : 143|8@0+ (1,0) [0|254] "" FUSION
 SG_ EXV_Cmd_Init_Rq : 149|3@0+ (1,0) [0|1] "" FUSION
 SG_ EXV2_Cmd_Init_Rq : 146|3@0+ (1,0) [0|1] "" FUSION
 SG_ EXV2_Cmd_Move_Enbl : 159|1@0+ (1,0) [0|1] "" FUSION
 SG_ EXV_Cmd_Move_Enbl : 158|1@0+ (1,0) [0|1] "" FUSION
 SG_ EWP2_Default_Operation_EWP_Rq : 157|1@0+ (1,0) [0|1] "" FUSION
 SG_ BDC_1_MoveEnable : 156|1@0+ (1,0) [0|1] "" FUSION
 SG_ EWP3_Default_Operation_EWP_Rq : 155|1@0+ (1,0) [0|1] "" FUSION
 SG_ EWP1_Default_Operation_EWP_Rq : 154|1@0+ (1,0) [0|1] "" FUSION
 SG_ CCV4_ReqMovePos : 153|1@0+ (1,0) [0|1] "" FUSION
 SG_ CCV4_MoveEnable : 152|1@0+ (1,0) [0|1] "" FUSION

BO_ 554 Zone_Fr_THCM: 24 ZONE_FR
 SG_ PT_High_Tact : 7|8@0+ (1,-40) [-40|140] "Deg^C" FUSION
 SG_ EACProtectEnable : 15|2@0+ (1,0) [0|2] "" FUSION
 SG_ PT_High_P : 19|12@0+ (1,0) [0|4000] "KPa" FUSION
 SG_ PT_High_T : 39|8@0+ (0.5,-40) [-40|85] "Deg^C" FUSION
 SG_ PT_Low_P2 : 43|12@0+ (1,0) [0|4000] "KPa" FUSION
 SG_ PT_Low_T2 : 63|8@0+ (0.5,-40) [-40|85] "Deg^C" FUSION
 SG_ PT_Low_P1 : 67|12@0+ (1,0) [0|4000] "KPa" FUSION
 SG_ PT_Low_T1 : 87|8@0+ (0.5,-40) [-40|85] "Deg^C" FUSION
 SG_ Tamb : 95|8@0+ (0.5,-40) [-40|85] "Deg^C" FUSION
 SG_ Bat_Out_Temp : 103|8@0+ (0.5,-40) [-40|85] "Deg^C" FUSION
 SG_ Bat_In_Temp : 111|8@0+ (0.5,-40) [-40|85] "Deg^C" FUSION
 SG_ Motor_Out_Temp : 119|8@0+ (0.5,-40) [-40|85] "Deg^C" FUSION
 SG_ Motor_In_Temp : 127|8@0+ (0.5,-40) [-40|85] "Deg^C" FUSION
 SG_ FWV_Err : 139|2@0+ (1,0) [0|2] "" FUSION
 SG_ TWV_Err : 137|2@0+ (1,0) [0|2] "" FUSION
 SG_ EWP3_Err : 151|2@0+ (1,0) [0|2] "" FUSION
 SG_ EWP2_Err : 149|2@0+ (1,0) [0|2] "" FUSION
 SG_ EWP1_Err : 147|2@0+ (1,0) [0|2] "" FUSION
 SG_ WPTC_Err : 145|2@0+ (1,0) [0|2] "" FUSION
 SG_ AGS_Err : 159|2@0+ (1,0) [0|2] "" FUSION
 SG_ Fan_Err : 157|2@0+ (1,0) [0|2] "" FUSION
 SG_ EXV2_Err : 155|2@0+ (1,0) [0|2] "" FUSION
 SG_ EXV1_Err : 153|2@0+ (1,0) [0|2] "" FUSION
 SG_ SOTXV_Err : 167|2@0+ (1,0) [0|2] "" FUSION
 SG_ COMP_Err : 165|2@0+ (1,0) [0|2] "" FUSION
 SG_ SOV3_Err : 163|2@0+ (1,0) [0|2] "" FUSION
 SG_ SOV2_Err : 161|2@0+ (1,0) [0|2] "" FUSION
 SG_ SOV1_Err : 175|2@0+ (1,0) [0|2] "" FUSION
 SG_ PT_High_Tact_Err : 173|2@0+ (1,0) [0|2] "" FUSION
 SG_ PT_High_P_Err : 171|2@0+ (1,0) [0|2] "" FUSION
 SG_ PT_Low_T2_Err : 169|2@0+ (1,0) [0|2] "" FUSION
 SG_ PT_Low_P2_Err : 183|2@0+ (1,0) [0|2] "" FUSION
 SG_ PT_Low_T1_Err : 181|2@0+ (1,0) [0|2] "" FUSION
 SG_ PT_Low_P1_Err : 179|2@0+ (1,0) [0|2] "" FUSION
 SG_ Motor_Out_Temp_Err : 177|2@0+ (1,0) [0|2] "" FUSION
 SG_ Bat_Out_Temp_Err : 191|2@0+ (1,0) [0|2] "" FUSION
 SG_ Motor_In_Temp_Err : 189|2@0+ (1,0) [0|2] "" FUSION
 SG_ Bat_In_Temp_Err : 187|2@0+ (1,0) [0|2] "" FUSION
 SG_ Tamb_Err : 185|2@0+ (1,0) [0|2] "" FUSION

BO_ 570 GW_FCM4: 8 FUSION
 SG_ HazardWarningReq : 7|1@0+ (1,0) [0|1] "" Vector__XXX
 SG_ ADAS_AEB_Sta : 6|3@0+ (1,0) [0|7] "" Vector__XXX
 SG_ RightTurnLightReq : 3|1@0+ (1,0) [0|1] "" Vector__XXX
 SG_ ADAS_FCW_Sta : 2|3@0+ (1,0) [0|7] "" Vector__XXX
 SG_ LeftTurnLightReq : 15|1@0+ (1,0) [0|1] "" Vector__XXX
 SG_ ADAS_LDW_Sta : 14|3@0+ (1,0) [0|7] "" Vector__XXX
 SG_ ADAS_FltWrnReq : 11|1@0+ (1,0) [0|1] "" Vector__XXX
 SG_ ADAS_ACC_Sta : 10|3@0+ (1,0) [0|7] "" ZONE_DR
 SG_ ACC_ObjDstLvl : 23|3@0+ (1,0) [0|7] "" Vector__XXX
 SG_ ForceLowBeam : 20|2@0+ (1,0) [0|1] "" Vector__XXX
 SG_ TimeGapLevel : 18|3@0+ (1,0) [0|7] "" Vector__XXX
 SG_ ACCSetSpeed : 31|8@0+ (1,0) [0|254] "" Vector__XXX
 SG_ ACCSetSpeed_Disp : 39|3@0+ (1,0) [0|7] "" Vector__XXX
 SG_ ACC_TakeoverReq : 36|1@0+ (1,0) [0|1] "" Vector__XXX
 SG_ ADAS_WarningMsg : 35|4@0+ (1,0) [0|15] "" Vector__XXX
 SG_ ADAS_CAM_SpdLim : 47|5@0+ (1,0) [0|31] "" Vector__XXX
 SG_ Target_Type : 40|4@0+ (1,0) [0|15] "" Vector__XXX
 SG_ ADAS_SLIF_SpdLim : 52|5@0+ (1,0) [0|31] "" Vector__XXX
 SG_ FCM4_Checksum : 63|8@0+ (1,0) [0|255] "" Vector__XXX

BO_ 572 GW_FCM5: 8 FUSION
 SG_ LKA_HOD_Display_Warning : 7|1@0+ (1,0) [0|1] "" Vector__XXX
 SG_ ADAS_LKA_Sta : 6|3@0+ (1,0) [0|7] "" Vector__XXX
 SG_ LKA_HOD_Sound_Warning : 3|1@0+ (1,0) [0|1] "" Vector__XXX
 SG_ ADAS_LFC_Sta : 2|3@0+ (1,0) [0|7] "" Vector__XXX
 SG_ ADAS_LaneModeL : 10|3@0+ (1,0) [0|7] "" Vector__XXX
 SG_ ADAS_LaneModeR : 22|3@0+ (1,0) [0|7] "" Vector__XXX
 SG_ ADAS_SLIF_Sta : 30|3@0+ (1,0) [0|5] "" Vector__XXX
 SG_ ADAS_ISA_Sta : 36|2@0+ (1,0) [0|3] "" ZONE_DR
 SG_ ADAS_LDW_Mute : 34|1@0+ (1,0) [0|1] "" Vector__XXX
 SG_ ADAS_FCW_Mute : 32|1@0+ (1,0) [0|1] "" Vector__XXX
 SG_ ADAS_LFC_Hands_Off_Warning : 47|2@0+ (1,0) [0|3] "" Vector__XXX
 SG_ LVDA_Disabled : 45|1@0+ (1,0) [0|1] "" Vector__XXX
 SG_ LVDA_Mute_Sta : 44|2@0+ (1,0) [0|3] "" Vector__XXX
 SG_ LVDA_Failinfo : 42|1@0+ (1,0) [0|1] "" Vector__XXX
 SG_ LVDA_Warning : 41|1@0+ (1,0) [0|1] "" Vector__XXX
 SG_ LVDA_ACCStatusInformation : 40|1@0+ (1,0) [0|1] "" Vector__XXX
 SG_ ADAS_LFC_Warn_Sound : 55|8@0+ (1,0) [0|255] "" Vector__XXX
 SG_ FCM5_Checksum : 63|8@0+ (1,0) [0|255] "" Vector__XXX

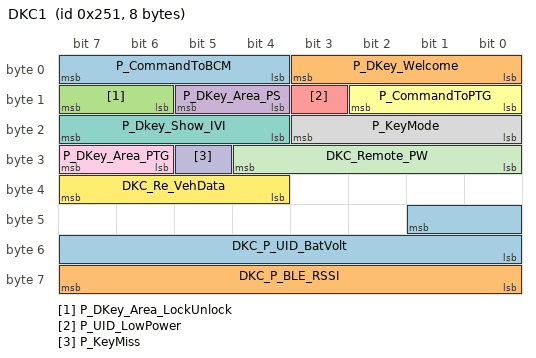
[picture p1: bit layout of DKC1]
BO_ 593 DKC1: 8 DKC
 SG_ P_CommandToBCM : 7|4@0+ (1,0) [0|15] "" FUSION
 SG_ P_DKey_Welcome : 3|4@0+ (1,0) [0|15] "" FUSION
 SG_ P_DKey_Area_LockUnlock : 15|2@0+ (1,0) [0|3] "" FUSION
 SG_ P_DKey_Area_PS : 13|2@0+ (1,0) [0|3] "" FUSION
 SG_ P_UID_LowPower : 11|1@0+ (1,0) [0|1] "" FUSION
 SG_ P_CommandToPTG : 10|3@0+ (1,0) [0|5] "" FUSION
 SG_ P_Dkey_Show_IVI : 23|4@0+ (1,0) [0|15] "" FUSION
 SG_ P_KeyMode : 19|4@0+ (1,0) [0|15] "" FUSION
 SG_ P_DKey_Area_PTG : 31|2@0+ (1,0) [0|3] "" FUSION
 SG_ P_KeyMiss : 29|1@0+ (1,0) [0|1] "" FUSION
 SG_ DKC_Remote_PW : 28|5@0+ (1,0) [0|16] "" FUSION
 SG_ DKC_Re_VehData : 39|4@0+ (1,0) [0|15] "" FUSION
 SG_ DKC_P_UID_BatVolt : 41|10@0+ (10,0) [0|3500] "mV" FUSION
 SG_ DKC_P_BLE_RSSI : 63|8@0+ (1,0) [0|255] "" FUSION

BO_ 594 DKC2: 24 DKC
 SG_ EncryptionDATA_64_127 : 71|64@0+ (1,0) [0|1.8446744073709551E19] "" FUSION
 SG_ EncryptionDATA_0_63 : 135|64@0+ (1,0) [0|1.8446744073709551E19] "" FUSION
 SG_ Random_Number_X : 7|64@0+ (1,0) [0|1.8446744073709551E19] "" FUSION

BO_ 595 FD_DKC1: 32 FUSION
 SG_ IVI_Located_STA : 7|2@0+ (1,0) [0|3] "" ZONE_FR,ZONE_DR
 SG_ IVI_PTG_USSta_SW : 3|1@0+ (1,0) [0|1] "" ZONE_DR
 SG_ IVI_PTG_Open_Height : 2|3@0+ (1,0) [0|7] "" ZONE_DR
 SG_ Approach_Unlock_SW : 15|1@0+ (1,0) [0|1] "" DKC
 SG_ Walkaway_Lock_SW : 23|1@0+ (1,0) [0|1] "" DKC
 SG_ BrkSw_Sta : 31|1@0+ (1,0) [0|1] "" ZONE_DR,DKC
 SG_ DSEAT_anti_set : 39|1@0+ (1,0) [0|1] "" ZONE_DR
 SG_ DSEAT_entryfun_set : 47|1@0+ (1,0) [0|1] "" ZONE_DR
 SG_ IVI_PTG_Mode_SW : 46|2@0+ (1,0) [0|3] "" ZONE_DR
 SG_ PSEAT_vent_req : 44|3@0+ (1,0) [0|7] "" ZONE_DR
 SG_ IVI_PTG_Sta_SW : 41|2@0+ (1,0) [0|3] "" ZONE_DR
 SG_ IVI_ISA_OffsetSpd : 55|4@0+ (1,0) [0|14] "" ZONE_DR
 SG_ SenstivityPosition : 51|4@0+ (1,0) [0|15] "" ZONE_DR
 SG_ IVI_Time_Check : 63|8@0+ (1,0) [0|255] "" ZONE_FR,ZONE_DR,DKC
 SG_ IVI_Time_Year : 70|7@0+ (1,2000) [2000|2127] "YEAR" ZONE_FR,ZONE_DR
 SG_ Hood_Latch_SW : 79|2@0+ (1,0) [0|3] "" ZONE_DR
 SG_ IVI_Time_Minute : 77|6@0+ (1,0) [0|63] "MINUTE" ZONE_FR,ZONE_DR,DKC
 SG_ TurnSwTimeSet : 87|2@0+ (1,0) [0|3] "" ZONE_DR
 SG_ IVI_Time_Second : 85|6@0+ (1,0) [0|63] "SECOND" ZONE_FR,ZONE_DR,DKC
 SG_ DSEAT_vent_req : 95|3@0+ (1,0) [0|7] "" ZONE_DR
 SG_ IVI_Time_Day : 92|5@0+ (1,0) [0|31] "DAY" ZONE_FR,ZONE_DR,DKC
 SG_ HeadLampSW : 102|2@0+ (1,0) [0|3] "" ZONE_FR,ZONE_DR
 SG_ IVI_Time_Hour : 100|5@0+ (1,0) [0|31] "HOUR" ZONE_FR,ZONE_DR,DKC
 SG_ IVI_Time_Month : 107|4@0+ (1,0) [0|12] "MONTH" ZONE_FR,ZONE_DR,DKC
 SG_ PTG_Inner_SW2 : 5|2@0+ (1,0) [0|3] "" DKC
 SG_ L_Drv_CtrlCmd : 38|7@0+ (1,0) [0|127] "%" ZONE_FR,ZONE_DR
 SG_ L_Pas_CtrlCmd : 30|7@0+ (1,0) [0|127] "%" ZONE_FR,ZONE_DR
 SG_ L_RLD_CtrlCmd : 22|7@0+ (1,0) [0|127] "%" ZONE_FR,ZONE_DR
 SG_ L_RRD_CtrlCmd : 14|7@0+ (1,0) [0|127] "%" ZONE_FR,ZONE_DR
 SG_ OFF_AC_MODE : 111|3@0+ (1,0) [0|7] "" ZONE_FR
 SG_ BrkSw_V : 71|1@0+ (1,0) [0|1] "" ZONE_DR
 SG_ MCPressure : 115|12@0+ (0.1,-9.7) [-9.7|195] "bar" ZONE_DR
 SG_ MCPressure_V : 103|1@0+ (1,0) [0|1] "" ZONE_DR
 SG_ BrkPedalPos : 135|8@0+ (0.4,0) [0|100] "%" ZONE_DR
 SG_ BrkPedalPos_Sta : 108|1@0+ (1,0) [0|1] "" ZONE_DR
 SG_ FDC_BCM_LockAlarm_Cmd : 119|2@0+ (1,0) [0|2] "" ZONE_DR
 SG_ FDC_THCM_ACTInitial_Cmd : 117|1@0+ (1,0) [0|1] "" ZONE_DR
 SG_ FDC_BCM_ATCtrl_Cmd : 143|2@0+ (1,0) [0|2] "" ZONE_DR
 SG_ FDC_BCM_OutMode_Cmd : 139|4@0+ (1,0) [0|15] "" Vector__XXX

CM_ SG_ 278 CS_VCU1_CAN4 "VCU1 frame checksum 
x^8+x^4+x^3+x^2+1 
It shall use 0xFF as the start value and XOR value.";
CM_ SG_ 278 RC_VCU1_CAN4 "VCU1 4-bit rolling counter";
CM_ SG_ 278 Dr_SeatSta "Driver seat switch state";
CM_ SG_ 278 MSA_Crl_Sta "MSA Status";
CM_ SG_ 278 CC_Crl_Sta "Cruise Control Status";
CM_ SG_ 278 ShiftGearPosn "EV Selector Position Status/ Selector Position Status Signal Failure";
CM_ SG_ 278 PwrSta "Vehicle Power Status";
CM_ SG_ 278 ReBrakeLPReq "Regen brake lamp request";
CM_ SG_ 278 DKCTimeSN "DKC time serial number";
CM_ SG_ 278 TimeSNDKCFbk "Time serial number DKC feedback";
CM_ SG_ 278 EquivAccPedalSWSta "ADAS equivalent acceleration pedal switch status";
CM_ SG_ 278 HornCtrl "Horn Control";
CM_ SG_ 278 BCM_DoorLock_Sta "BCM Unlock Single Door Setting";
CM_ SG_ 278 DimmerEN "Dimmer Enable";
CM_ SG_ 278 RoomLampH "Room Lamp High";
CM_ SG_ 278 RoomLampL "Room Lamp Low";
CM_ SG_ 278 TailgateRemote "Remote Control PTG";
CM_ SG_ 278 BCM_Buzzer_Req "BCM Buzzer Request";
CM_ SG_ 278 LockSetting "BCM Unlock Single Door Setting";
CM_ SG_ 278 Dimmer "Dimmer";
CM_ SG_ 278 L_APM_WdwEnable "Enable windows movement";
CM_ SG_ 278 CrashDetd "Crash Detected";
CM_ SG_ 278 AntiTheftSeatFold "Anti-theft Seat Fold";
CM_ SG_ 278 AntitheftSta "Anti-theft Status";
CM_ SG_ 278 RTurnLP "Right Turn Lamp";
CM_ SG_ 278 LTurnLP "Left Turn Lamp";
CM_ SG_ 278 HazardSW "Hazard SW";
CM_ SG_ 278 Rr_FogLamp "Rear Fog Lamp";
CM_ SG_ 278 Fr_FogLamp "Front Fog Lamp";
CM_ SG_ 278 RBSD "Right BSD";
CM_ SG_ 278 LBSD "Left BSD";
CM_ SG_ 278 BrakeLamp "BrakeLamp";
CM_ SG_ 278 ReverseLamp "ReverseLamp";
CM_ SG_ 278 RDRL "Right DRL";
CM_ SG_ 278 LDRL "Left DRL";
CM_ SG_ 278 PosLamp "PositionLamp";
CM_ SG_ 278 H_Beam "High Beam";
CM_ SG_ 278 L_Beam "Low Beam";
CM_ SG_ 278 WasherCtrl "WasherControl";
CM_ SG_ 278 WiperFixMode "Wiper Fix Mode";
CM_ SG_ 278 Rr_Wiper "Rear Wiper";
CM_ SG_ 278 Fr_Wiper_L "Front Wiper LOW";
CM_ SG_ 278 Fr_Wiper_H "Front Wiper High";
CM_ SG_ 278 MirrorCtrl "Mirror Control";
CM_ SG_ 278 TailgateHDSW "Tailgate Handle SW";
CM_ SG_ 278 TrunkRel "Trunk Release";
CM_ SG_ 278 Rr_Defog "Rear Defog";
CM_ SG_ 278 MirrorDefog "Mirror Defog";
CM_ SG_ 278 CTDUnlockSW "Central Door Unlock SW";
CM_ SG_ 278 CTDLockSW "Central Door Lock SW";
CM_ SG_ 278 Rr_ChargingDoorCtrl "Rear Charging Door Control";
CM_ SG_ 278 Fr_ChargingDoorCtrl "Front Charging Door Control";
CM_ SG_ 278 CTDCtrl "Door Lock Control";
CM_ SG_ 278 Tailgate_SW "Tailgate Switch";
CM_ SG_ 278 HoodSW "Hood Switch";
CM_ SG_ 278 DoorLockIND "Door Lock Indicator";
CM_ SG_ 278 AllDoorSW "All Door Switch";
CM_ SG_ 278 RRDoorSW "Rear Right Door Switch";
CM_ SG_ 278 RLDoorSW "Rear Left Door Switch";
CM_ SG_ 278 PsDoorSW "Passenger Side Door Switch";
CM_ SG_ 278 DrDoorSW "Driver Side Door Switch";
CM_ SG_ 278 FD_TBOX_VehData_Sta "Response the Status of  VehData to TBOX";
CM_ SG_ 278 FD_TBOX_VehData_Err "Response the Error of  VehData to TBOX";
CM_ SG_ 278 FD_DKC_VehData_Sta "Response the Status of  VehData to DKC";
CM_ SG_ 278 FD_DKC_VehData_Err "Response the Error of  VehData to DKC";
CM_ SG_ 278 FD_TBOX_DTCData_Sta "Response the Status of  DTCData to TBOX";
CM_ SG_ 278 FD_TBOX_DTCData_Err "Response the Error of  DTCData to TBOX";
CM_ SG_ 278 AmbLightBreath3 "Atmosphere Lamp 3 Breathing Mode";
CM_ SG_ 278 AmbLightBreath2 "Atmosphere Lamp 2 Breathing Mode";
CM_ SG_ 278 LampPwr "Lamp Power";
CM_ SG_ 278 AmbLightBreath1 "Atmosphere Lamp 1 Breathing Mode";
CM_ SG_ 278 DKCAuthSta "DKC authentication status";
CM_ SG_ 278 AmbLightColor3 "RGB 64 Color";
CM_ SG_ 278 AmbLightColor2 "RGB 64 Color";
CM_ SG_ 278 AmbLightColor1 "RGB 64 Color";
CM_ SG_ 278 AmbLightBrightness3 "Atmosphere Lamp 3 Bright adjustment";
CM_ SG_ 278 AmbLightBrightness2 "Atmosphere Lamp 2 Bright adjustment";
CM_ SG_ 278 AmbLightBrightness1 "Atmosphere Lamp 1 Bright adjustment";
CM_ SG_ 278 VehSpeed "Vehicle Speed";
CM_ SG_ 278 HWResetSta "Hardware reset state";
CM_ SG_ 278 CtrlFrPwrStbA1P "Control zone Fr power standby A1 plus pin signal";
CM_ SG_ 278 CtrlFrIRC1 "Control zone Fr IRC1 plus pin signal";
CM_ SG_ 278 CtrlFrBMSCCUCIR "Control zone Fr BMSCCUCIR  pin signal";
CM_ SG_ 278 CtrlFrEDUINVERTER "Control zone Fr EDUINVERTER  pin signal";
CM_ SG_ 278 CtrlDrPwrStbA2 "Control zone Dr power standby A2  pin signal";
CM_ SG_ 374 HVInVolt "HV Input voltage";
CM_ SG_ 374 LVBattDet12V "12V Battery Detect";
CM_ SG_ 374 OBCDCCurLm "OBC DC Current Limit";
CM_ SG_ 374 ReChargerStaFromEvcc "ResarvationChargerStatusFromEVCC";
CM_ SG_ 374 OBCDCVoltLm "OBC DC Voltage Limit";
CM_ SG_ 378 BMSChckSum "BMS CheckSum";
CM_ SG_ 378 BMSRolCnct "BMS RollingCount";
CM_ SG_ 378 V2LSta "V2L Adapter Status";
CM_ SG_ 378 HVBChrgErr "HVB Charge Error";
CM_ SG_ 378 DisChrgPlugErr "(Dis)Charger plug Error
0x0 : Normal
0x1 : plug-in incomplete
0x2 : (un)lock request invalid";
CM_ SG_ 378 ChrgInLockReq "ChargeInlet Lock Request";
CM_ SG_ 378 HVBCellUnbalanErr "Cell unbalance";
CM_ SG_ 378 HVBCellUndrVoltErr "Cell under Volt";
CM_ SG_ 378 HVBCellOvrVoltErr "Cell over Volt";
CM_ SG_ 378 HVBCellUdrVoltWarn "Cell under Volt warn";
CM_ SG_ 378 HVBCellOvrVoltWarn "Cell over Volt warn";
CM_ SG_ 378 CellUnconsistErr "Cell Unconsistency Error";
CM_ SG_ 378 SystemUncomErr "System Uncompitable Error";
CM_ SG_ 378 IsoDetSta "Isolation Detection status. Send every 100ms and event trigger, especially power down";
CM_ SG_ 378 HVBPreheatPrecoolSta "BMS informs VCU HV battery is over heat or cold";
CM_ SG_ 378 ExtChrgSta "External charging status";
CM_ SG_ 378 ChrgPlugSta "Charger plug status";
CM_ SG_ 378 HVBattReady4Pre "BMS informs VCU HV battery is ready to be Precharged";
CM_ SG_ 378 HVILSta "HVIL status";
CM_ SG_ 378 HVBTempDiffErr "Temperature Different Error";
CM_ SG_ 378 HVBPrechrgSta "BMS informs VCU HV battery precharge status";
CM_ SG_ 378 HVBContactorSta "HV battery contactor closed status";
CM_ SG_ 378 BMS_READY "BMS ready";
CM_ SG_ 378 DCChrgSysShockErr "DC Charge System Shock Error";
CM_ SG_ 378 HVBHVILErr "HVIL hardware failed";
CM_ SG_ 378 HVBSOCJumpError "SOC Jump Error";
CM_ SG_ 378 HVBUndrSOCErr "Under SOC";
CM_ SG_ 378 HVBOvrSOCErr "Over SOC";
CM_ SG_ 378 HVBUndrTempErr "Under temperature";
CM_ SG_ 378 HVBOvrTempErr "Over temperature";
CM_ SG_ 378 HVBOvrDchrgCurErr "Over discharge current";
CM_ SG_ 378 HVBOvrChrgCurrErr "Over charge current";
CM_ SG_ 378 HVBShrtDischrgCurrErr "Short discharge current";
CM_ SG_ 378 HVBShrtChrgCurrErr "Short charge current";
CM_ SG_ 378 HVBUndrVoltErr "Pack under Volt";
CM_ SG_ 378 HVBOvrVoltErr "Pack over Volt";
CM_ SG_ 378 HVBUndrTempWarn "Under temperature warn";
CM_ SG_ 378 HVBOvrTempWarn "Over temperature warn";
CM_ SG_ 378 BMS_Warn_8 "BMS Warning8";
CM_ SG_ 378 BMS_Warn_7 "BMS Warning7";
CM_ SG_ 378 BMS_Warn_6 "BMS Warning6";
CM_ SG_ 378 BMS_Warn_5 "BMS Warning5";
CM_ SG_ 378 BMS_Warn_4 "BMS Warning4";
CM_ SG_ 378 BMS_Warn_3 "BMS Warning3";
CM_ SG_ 378 BMS_Warn_2 "BMS Warning2";
CM_ SG_ 378 BMS_Warn_1 "BMS Warning1";
CM_ SG_ 380 ADAS_VehSpdLim "Vehicle Speed Limit(if Distance_unit = 0x0, then UNIT = km/h, else  UNIT = mph)";
CM_ SG_ 380 ADAS_ShftPosnReq_A "Shifter Position Request Applicable";
CM_ SG_ 380 ADAS_ShftPosnReq "Shifter Position Request";
CM_ SG_ 380 ACC_ObjDist "Object distance";
CM_ SG_ 380 FCM3_LifeCount "Rolling Counter of FCM3";
CM_ SG_ 380 ADAS_ForceIdle "Forced Idle";
CM_ SG_ 380 ACC_ObjRelSpd "Object relative speed";
CM_ SG_ 380 FCM3_Checksum "The [CAN CheckSum] shall be calculated as a CRC8 with the following polynomial: x^8+x^4+x^3+x^2+1 (=0x1D), according with SAE-J1850-CRC8 Start value 0xFF";
CM_ SG_ 386 CCU_HEATMaxLampSts "Climate HEATING Max lamp state";
CM_ SG_ 386 CCU_ACLampSts "Climate AC lamp state";
CM_ SG_ 386 CCU_Dispaly_Request "Air Conditioner display reuqest trigger";
CM_ SG_ 386 CCU_EcoSts "Economic mode status";
CM_ SG_ 386 CCU_AutoMidLampSts "Climate air conditionning middle left automatic mode lamp state";
CM_ SG_ 386 CCU_AutoLampSts "Climate air conditionning Front  automatic mode lamp state";
CM_ SG_ 386 CCU_ACMaxLampSts "Climate AC Max lamp state";
CM_ SG_ 386 Fr_Coolanttemp "LLC coolant temp";
CM_ SG_ 386 CCU_RrOnOffLampSts "Rear Climate On Off lamp state";
CM_ SG_ 386 sigWindDirZon1St "Feedback: WInd DirectionZone 1. 
Feed, Body, WIndscreen and/or Auto";
CM_ SG_ 386 CCU_FrtOnOffLampSts "Front Climate On Off lamp state";
CM_ SG_ 386 sigWindDirZon3St "Feedback: WInd DirectionZone 3. 
Feed, Body and/or Auto";
CM_ SG_ 386 sigAirIntenZon1St "Feedback FAN Level/Air Intensirty : 0-Max or Auto for zone 1";
CM_ SG_ 386 sigAirIntenZon3St "Feedback FAN Level/Air Intensirty : 0-Max or Auto for zone 3";
CM_ SG_ 386 CCU_SyncLampSts "Climate SYNC lamp state";
CM_ SG_ 386 sigDfrstSt "Defrost Status in the HVAC (ON / AUTO)";
CM_ SG_ 386 sigSetTempZon3St "Feedback: Temperature set in the HVAC for Zone 3";
CM_ SG_ 386 sigRecircSt "Recirculation Status in the HVAC (Fre/Rec/Auto)";
CM_ SG_ 386 sigHvacSt "Status of the HVAC (ON / OFF)";
CM_ SG_ 386 sigSetTempZon2St "Feedback: Temperature set in the HVAC for Zone 2";
CM_ SG_ 386 HPThermalRecoveryReq "Heat Pump thermal reuse request";
CM_ SG_ 386 sigSetTempZon1St "Feedback: Temperature set in the HVAC for Zone 1";
CM_ SG_ 386 EDriveMode "E-Drive Mode";
CM_ SG_ 386 Fr_Coolantflow "LLC coolant flow rate";
CM_ SG_ 386 sigClmtCmprPwrAct "Current power consumption AC compressor";
CM_ SG_ 386 sigCbnPTCPwrAct "Current power consumption FRONT AirPTC";
CM_ SG_ 386 sigCbnAirT "Cabin air temperature";
CM_ SG_ 386 sigAmbAirT "Environment temperature (outside ambient vehicle temperature)";
CM_ SG_ 386 sigCbnSolarRight "Measured cabin sun exposure";
CM_ SG_ 386 FD_RecyAuto_Cmd "Auto recycle command";
CM_ SG_ 386 BatteryMode "Battery Mode";
CM_ SG_ 386 CabinMode "Cabin Mode";
CM_ SG_ 386 sigCbnSolarLeft "Measured cabin sun exposure";
CM_ SG_ 386 sigClntTHvBattOut "battery coolant outlet temperature";
CM_ SG_ 386 FD_AGS_Cmd "Fusion Domain AGS Position Request";
CM_ SG_ 386 Rr_Coolantflow "LLC coolant flow rate";
CM_ SG_ 386 Rr_Coolanttemp "LLC coolant temp";
CM_ SG_ 390 FD_Blower_Cmd "Fusion Domain Blower Command";
CM_ SG_ 390 FD_SOV3_Cmd "Fusion Domain SOV3 Command";
CM_ SG_ 390 FD_SOV2_Cmd "Fusion Domain SOV2 Command";
CM_ SG_ 390 FD_SOV1_Cmd "Fusion Domain SOV1 Command";
CM_ SG_ 390 FD_SOTXV_Cmd "Fusion Domain SOTXV Command";
CM_ SG_ 390 ACSubMode "AC system sub mode";
CM_ SG_ 390 FD_FWV_Cmd "Fusion Domain Four Way Valve Position Request";
CM_ SG_ 390 CCU_HiVoltageReq "High voltage request";
CM_ SG_ 390 FD_Comp_Cmd "Fusion Domain Compressor Request";
CM_ SG_ 390 CCU_CbnPreSts "Cabin Preconditioning Status
It shall stay as Off if A/C is turned on not by preconditioning request";
CM_ SG_ 390 DeiceModReq "Deice mode request";
CM_ SG_ 390 CCU_CbnPreACWkSts "Cabin Preconditioning A/C work status";
CM_ SG_ 390 FD_EXV1_Cmd "Fusion Domain Chiller EXV Command";
CM_ SG_ 390 CCU_CbnPreEstimdTi "Maximum Estimated Time to achieve the target temperature in minutes(Value 61,62 for reserved, value 63 for Invalid)
0x3d~0x3E:Reserved";
CM_ SG_ 390 FD_EXV2_Cmd "Fusion Domain HPChiller EXV Command";
CM_ SG_ 390 FD_TWV_Cmd "Fusion Domain Three Way Valve Position Request";
CM_ SG_ 390 FD_FrRiAPTCHeatPwr_Cmd "Fusion Domain Front Right Air PTC Heat Power Request";
CM_ SG_ 390 FD_FrLeAPTCHeatPwr_Cmd "Fusion Domain Front Left Air PTC Heat Power Request";
CM_ SG_ 390 FD_RrAPTCHeatPwr_Cmd "Fusion Domain Rear Air PTC Heat Power Request";
CM_ SG_ 390 FD_FrWPTCHeatPwr_Cmd "Fusion Domain Front Water PTC Heat Power Request";
CM_ SG_ 390 FD_EWP3_Cmd "Fusion Domain Battery Water Pump Command";
CM_ SG_ 390 FD_EWP2_Cmd "Fusion Domain FrTM Water Pump Command";
CM_ SG_ 390 FD_EWP1_Cmd "Fusion Domain RrTM Water Pump Command";
CM_ SG_ 390 APTC_ActFrRiPwr "Air PTC actual power front right";
CM_ SG_ 390 BatLoopActWtFlw "Battery loop actual water flow";
CM_ SG_ 390 CoolgFanActDuty "Cooling fan actual duty cycle (PWM)";
CM_ SG_ 497 DrPMMSysErrLmp "PMM system error lamp request";
CM_ SG_ 497 DrPMMLVOutPErrLmp "PMM LV output error lamp request";
CM_ SG_ 497 DrPMMLimpHomeActReq "PMM Limp Home act request";
CM_ SG_ 497 DrIVIFault "Zone Dr 'IVI' pin fault state";
CM_ SG_ 497 DrEOBDFault "Zone Dr 'EOBD' pin fault state";
CM_ SG_ 497 DrInfoFault "Zone Dr 'Information' pin pin fault state";
CM_ SG_ 497 DrPwrWindowECUFault "Zone Dr 'Power_Window_ECU' pin fault state";
CM_ SG_ 497 DrTHCMFault "Zone Dr 'THCM' pin fault state";
CM_ SG_ 497 DrColumnSWFault "Zone Dr 'ColumnSW' pin fault state";
CM_ SG_ 497 DrAuBoxPwrN2Curr "Zone Dr 'AUDIO BOX POWER NODE2' pin electric current";
CM_ SG_ 497 DrAuBoxPwrN1Curr "Zone Dr 'AUDIO BOX POWER NODE1' pin electric current";
CM_ SG_ 497 DrPwrStdbyACurr "Zone Dr 'Power_Standby_A' pin electric current";
CM_ SG_ 497 DrPwrONA2Curr "Zone Dr 'Power_ON_A2' pin electric current";
CM_ SG_ 497 DrPwrONA1Curr "Zone Dr 'Power_ON_A1' pin electric current";
CM_ SG_ 497 DrCtrlBDVolt "Detect voltage on ZONE Ctrl board";
CM_ SG_ 497 DrCtrlTemp "Detect temperature on ZONE Ctrl board";
CM_ SG_ 497 DrPowerTemp1 "Detect temperature on ZONE power board";
CM_ SG_ 497 DrPowerTemp2 "Detect temperature on ZONE power board";
CM_ SG_ 497 DrPwrSta "DR PwrSta transmit";
CM_ SG_ 497 DrPwrInformationSta "Information pin B+ power request status";
CM_ SG_ 497 DrAPWStaErr "APW relay error state";
CM_ SG_ 497 DrAPWLINErr "APW LIN lost communication";
CM_ SG_ 497 DrONA1ErrSta "Zone Dr power ON A1 power pin error state";
CM_ SG_ 497 DrStdAErrSta "Zone Dr power standby A power pin error  state";
CM_ SG_ 497 DrPwrWinErrSta "Zone Dr power window power pin error  state";
CM_ SG_ 497 DrInfoErrSta "Zone Dr information power pin error  state";
CM_ SG_ 497 ZoneDrMalfunLevel "Zone Dr VCU error level";
CM_ SG_ 497 ZDR_SYS_APMRetryCnt_Sta "Zone DR APM power output pin retry count";
CM_ SG_ 497 ZDR_SYS_CSWRetryCnt_Sta "Zone DR ColumnSW power output pin retry count";
CM_ SG_ 497 ZDR_SYS_BSWSleepReq_Sta "Zone DR sleep request from BSW";
CM_ SG_ 497 ZDR_VCU_HWReset_Sta "Zone Dr VCU hardware reset state";
CM_ SG_ 497 ZDR_VCU_PwrSupply_Sta "Zone Dr VCU power supply state";
CM_ SG_ 498 FrPwrStdbyA2PlusCurr "Zone Fr 'Power_Standby_A2+' pin electric current";
CM_ SG_ 498 FrBMS_CCU_CIRCurr "Zone Fr 'BMS_CCU_CIR' pin electric current";
CM_ SG_ 498 FrEDU_INVERTERCurr "Zone Fr 'INVERTER' pin electric current";
CM_ SG_ 498 FrPwrStdbyA1PlusFault "Zone Fr 'Power_Standby_A1+' pin fault state";
CM_ SG_ 498 FrPwrStdbyA2PlusFault "Zone Fr 'Power_Standby_A2+' pin fault state";
CM_ SG_ 498 FrPwrONA1Fault "Zone Fr 'Power_ON_A1' pin fault state";
CM_ SG_ 498 FrBMS_CCU_CIRFault "Zone Fr 'BMS_CCU_CIR' pin fault state";
CM_ SG_ 498 FrEDU_INVERTERFault "Zone Fr 'INVERTER' pin fault state";
CM_ SG_ 498 FrPwrStdbyA1Fault "Zone Fr 'Power_Standby_A1' pin fault state";
CM_ SG_ 498 FrPMMSysErrLmp "PMM system error lamp request";
CM_ SG_ 498 FrPMMLVOutPErrLmp "PMM LV output error lamp request";
CM_ SG_ 498 FrPMMLimpHomeActReq "PMM Limp Home act request";
CM_ SG_ 498 FrIRC_1Curr "Zone Fr 'IRC_1' pin electric current";
CM_ SG_ 498 FrPwrStdbyA2Curr "Zone Fr 'Power_Standby_A2' pin electric current";
CM_ SG_ 498 FrPwrONA3Curr "Zone Fr 'Power_ON_A3' pin electric current";
CM_ SG_ 498 FrPwrONA2Curr "Zone Fr 'Power_ON_A2' pin electric current";
CM_ SG_ 498 FrIRC_2Curr "Zone Fr 'IRC_2' pin electric current";
CM_ SG_ 498 FrPwrStdbyA1PlusCurr "Zone Fr 'Power_Standby_A1+' pin electric current";
CM_ SG_ 498 FrCtrlBDVolt "Detect voltage on ZONE Ctrl board";
CM_ SG_ 498 FrCtrlTemp "Detect temperature on ZONE Ctrl board";
CM_ SG_ 498 FrPowerTemp2 "Detect temperature on ZONE power board";
CM_ SG_ 498 FrPowerTemp1 "Detect temperature on ZONE power board";
CM_ SG_ 498 ZFR_SYS_BMSCCURetryCnt_Sta "Zone FR BMS_CCU power output pin retry count";
CM_ SG_ 498 ZFR_SYS_MCURetryCnt_Sta "Zone FR MCU power output pin retry count";
CM_ SG_ 498 ZoneFrMalfunLevel "Zone Fr VCU error level";
CM_ SG_ 498 ZFR_SYS_BSWSleepReq_Sta "Zone FR sleep request from BSW";
CM_ SG_ 498 FrStdA1PCErr "Zone Fr power standby A1 plus power pin current error state";
CM_ SG_ 498 FrStdA2PCErr "Zone Fr power standby A2 plus power pin current error state";
CM_ SG_ 498 FrStdA2PErr "Zone Fr power standby A2 plus power pin error state";
CM_ SG_ 498 FrBMSCCUCErr "Zone Fr BMS CCU power pin current error state";
CM_ SG_ 498 FrEDUErr "Zone Fr EDU power pin current error state";
CM_ SG_ 498 FrPwrSta "FR PwrSta transmit";
CM_ SG_ 498 ZFR_VCU_HWReset_Sta "Zone Fr VCU hardware reset state";
CM_ SG_ 498 ZFR_VCU_PwrSupply_Sta "Zone Fr VCU power supply state";
CM_ SG_ 547 FrntPTCSts "Front PTC Status signals";
CM_ SG_ 547 FrntPTCFltSt "Front PTC Fault Status";
CM_ SG_ 547 FrntPTCLVUnderUFlt "Front PTC Low Voltage Under Voltage Fault";
CM_ SG_ 547 FrntPTCLVOverUFlt "Front PTC Low Voltage Over Voltage Fault";
CM_ SG_ 547 FrntPTCHVUnderUFlt "Front PTC High Voltage Under Voltage Fault";
CM_ SG_ 547 FrntPTCHVOverUFlt "Frot PTC High Voltage Over Voltage Fault";
CM_ SG_ 547 FrntPTCLeOverAFlt "Front PTC Left Over Current Fault";
CM_ SG_ 547 FrntPTCRiOverAFlt "Front PTC Right Over Current Fault";
CM_ SG_ 547 FrntPTCLeCoreTSnsrFlt "Front PTC Left Core Temperature Sensor Fault";
CM_ SG_ 547 FrntPTCRiCoreTSnsrFlt "Frotn PTC Right Core Temperature Sensor Fault";
CM_ SG_ 547 FrntPTCLeCoreOverTFlt "Front PTC Left Core Over Remperature Fault";
CM_ SG_ 547 FrntPTCRiCoreOverTFlt "Front PTC Right Core Over Remperature Fault";
CM_ SG_ 547 FrntPTCLeIGBTShoCircFlt "Front PTC Left IGBT Short Circuit Fault";
CM_ SG_ 547 FrntPTCRiIGBTShoCircFlt "Front PTC Right IGBT Short Circuit Fault";
CM_ SG_ 547 FrntPTCLeOpentCircFlt "Front PTC Left Opent Circuit Fault";
CM_ SG_ 547 FrntPTCRiOpentCircFlt "Front PTC Right Opent Circuit Fault";
CM_ SG_ 547 FrntPTCPCBTSnsrFlt "Front PTC PCB Temperature Sensor Fault";
CM_ SG_ 547 FrntPTCPCBOverTFlt "Front PTC PCB Over Temperature Fault";
CM_ SG_ 547 FrntPTCComFlt "Front PTC Communication Fault";
CM_ SG_ 547 FrntPTCLeIGBTTSnsrFlt "Front PTC Left IGBT Temperature Sensor Fault";
CM_ SG_ 547 FrntPTCRiIGBTTSnsrFlt "Front PTC Right IGBT Temperature Sensor Fault";
CM_ SG_ 547 FrntPTCLeIGBTOverTFlt "Front PTC Left IGBT Over Temperature Fault";
CM_ SG_ 547 FrntPTCRiIGBTOverTFlt "Front PTC Right IGBT Over Temperature Fault";
CM_ SG_ 547 FrntPTCSWVers "Front PTC Software Version";
CM_ SG_ 547 FrntPTCHWVers "Front PTC Hardware Version";
CM_ SG_ 547 FrntPTCSupplierCod "Front PTC Supplier Code";
CM_ SG_ 547 FrntPTCRearLeOverAFlt "Frnt PTC Rear Left Over Current Fault";
CM_ SG_ 547 FrntPTCRearLeOpentCircFlt "Frnt PTC Rear Left Opent Circuit Fault";
CM_ SG_ 547 FrntPTCRearRiCoreOverTFlt "Frnt PTC Rear Right Core Over Remperature Fault";
CM_ SG_ 547 FrntPTCRearLeCoreOverTFlt "Frnt PTC Rear Left Core Over Remperature Fault";
CM_ SG_ 547 FrntPTCRearRiCoreTSnsrFlt "Frotn PTC Rear Right Core Temperature Sensor Fault";
CM_ SG_ 547 FrntPTCRearLeCoreTSnsrFlt "Frnt PTC Rear Left Core Temperature Sensor Fault";
CM_ SG_ 547 FrntPTCRearRiOverAFlt "Frnt PTC Rear Right Over Current Fault";
CM_ SG_ 547 FrntPTCRearRiOpentCircFlt "Frnt PTC Rear Right Opent Circuit Fault";
CM_ SG_ 547 FrntPTCRearRiIGBTShoCFlt "Frnt PTC Rear Right IGBT Short Circuit Fault";
CM_ SG_ 547 FrntPTCRearLeIGBTShoCFlt "Frnt PTC Rear Left IGBT Short Circuit Fault";
CM_ SG_ 547 FrntPTCRearLeBusLineC "Frnt PTC Rear Left  current
0xFF:Invalid";
CM_ SG_ 547 FrntPTCLeCoreT "Front PTC Left Core Temperature";
CM_ SG_ 547 FrntPTCRiCoreT "Front PTC Right Core Temperature";
CM_ SG_ 547 FrntPTCLeActHeatPwr "Front PTC Left Actual Heat Power";
CM_ SG_ 547 FrntPTCRiActHeatPwr "Front PTC Right Actual Heat Power";
CM_ SG_ 547 FrntPTCLeIGBTT "Front PTC Left IGBT Temperature";
CM_ SG_ 547 FrntPTCRiIGBTT "Front PTC Right IGBT Temperature";
CM_ SG_ 547 FrntPTCPCBT "Front PTC PCB Temperature";
CM_ SG_ 547 FrntPTCRearRiBusLineC "Frnt PTC Rear Right  current
0xFF:Invalid";
CM_ SG_ 547 FrntPTCRearLeActHeatPwr "Frnt PTC Rear Left Actual Heat Power
0x00-0xC8:actual value;
0xC9-0xFE:Reserved
0xFF:Invalid";
CM_ SG_ 547 FrntPTCRearLeCoreT "0x00~0xFE:Value
0xFF:Invalid";
CM_ SG_ 547 FrntPTCRearRiCoreT "Frnt PTC Rear Right Core Temperature
0x00~0xFE:Value
0xFF:Invalid";
CM_ SG_ 549 T_Foot_R "Right Foot Temperature";
CM_ SG_ 549 T_Foot_Rr "Rear Foot Temperature";
CM_ SG_ 549 T_Face_Rr "Rear Face Temperature";
CM_ SG_ 549 T_Foot_L "Left Foot Temperature";
CM_ SG_ 549 T_Face_R "Right Face Temperature";
CM_ SG_ 549 T_Face_L "Left Face Temperature";
CM_ SG_ 549 Tevap "Evaporator Temperature";
CM_ SG_ 549 Blower_FB "Blower Feedback";
CM_ SG_ 549 Tincar "Incar Temperature";
CM_ SG_ 549 SolarR "cabin sun exposure Right";
CM_ SG_ 549 SolarL "cabin sun exposure Left";
CM_ SG_ 549 APTC_Err "Air PTC error";
CM_ SG_ 549 Blower_Err "Blower error";
CM_ SG_ 549 T_Foot_Rr_Err "Foot wind direction rear duct temperature sensor error";
CM_ SG_ 549 T_Face_Rr_Err "Face wind direction rear duct temperature sensor error";
CM_ SG_ 549 T_Foot_R_Err "Foot wind direction in right side duct temperature sensor error";
CM_ SG_ 549 T_Face_R_Err "Face wind direction in right side duct temperature sensor error";
CM_ SG_ 549 T_Foot_L_Err "Foot wind direction in left side duct temperature sensor error";
CM_ SG_ 549 T_Face_L_Err "Face wind direction in left side duct temperature sensor error";
CM_ SG_ 549 Tincar_Err "In-cabin temperature sensor error";
CM_ SG_ 549 Tevap_Err "Evaporator temperature sensor error";
CM_ SG_ 549 SolarR_Err "Solar sensor right error";
CM_ SG_ 549 SolarL_Err "Solar sensor left error";
CM_ SG_ 549 ZDR_THCM_IntakeFail_Sta "Intake Motor Fail Signal";
CM_ SG_ 549 ZDR_THCM_ModeFail_Sta "Mode Motor Fail Signal";
CM_ SG_ 549 ZDR_THCM_LINACT1_Sta "LIN ACT1 Fail Signal";
CM_ SG_ 549 ZDR_THCM_LINACT2_Sta "LIN ACT2 Fail Signal";
CM_ SG_ 549 ZDR_THCM_LINACT3_Sta "LIN ACT3 Fail Signal";
CM_ SG_ 549 ZDR_THCM_LINACT4_Sta "LIN ACT4 Fail Signal";
CM_ SG_ 549 ZDR_THCM_LINACT5_Sta "LIN ACT5 Fail Signal";
CM_ SG_ 550 RLS_LightSnrErr "LightSensorError";
CM_ SG_ 550 RLS_RainSnrErr "RainSensorError";
CM_ SG_ 550 WiperZeroPosSW "WiperZeroPositionSwitch";
CM_ SG_ 550 AutoLightSW "LightActivation";
CM_ SG_ 550 WiperSWPos "WiperSwitchPosition";
CM_ SG_ 550 RLS_Lamp_Sta "Lampstatus";
CM_ SG_ 550 RLS_RainSnrWiperCmd "RainSensorWiperCommand";
CM_ SG_ 550 HornSW "Horn Switch status";
CM_ SG_ 550 CSW_TurnSw_Sta "CSW_TurnSw_Sta_CANbus";
CM_ SG_ 550 CSW_RWasSW_Sta "CSW_RWasherSW_Sta";
CM_ SG_ 550 CSW_FWasSw_Sta "CSW_FWasherSW_Sta";
CM_ SG_ 550 RRTurnLampC "Rear Right TurnLamp Current";
CM_ SG_ 550 RLTurnLampC "Rear Left TurnLamp Current";
CM_ SG_ 550 RLS_Exist "RLS_Exist";
CM_ SG_ 550 CSW_PassSW_Sta "CSW_PassSW_Sta";
CM_ SG_ 550 BrakeLampFail "BrakeLamp Failed";
CM_ SG_ 550 CSW_DimSw "CSW_DimSw";
CM_ SG_ 550 CSW_RWipIntSw_Sta "CSW_RWipSW_Sta";
CM_ SG_ 550 Wip_Speed "Wip_Speed";
CM_ SG_ 550 RWiperProtection "Rear Wiper Protection";
CM_ SG_ 550 RWiperAS "Rear Wiper AS";
CM_ SG_ 550 MIRROR_FOLD_SW "MIRROR_FOLD_SW";
CM_ SG_ 550 AllLockSta "All Door Lock";
CM_ SG_ 550 RRLockSta "Rear Right Door Lock Status";
CM_ SG_ 550 RLLockSta "Rear Left Door Lock Status";
CM_ SG_ 550 PsLockSta "Passenger Side Door Lock Status";
CM_ SG_ 550 DrLockSta "Driver Side Door Lock Staus";
CM_ SG_ 552 AGS_Actual_Position "Position feedback from the actuator";
CM_ SG_ 552 AGS_Low_Voltage_Error "Feedback for over/under voltage error";
CM_ SG_ 552 AGS_Temperature_Error "Feedback for overtemprature error";
CM_ SG_ 552 AGS_Sensor_Error "Feedback of Shutter position sensor fault";
CM_ SG_ 552 AGS_Electrical_Error "Feedback of electrical error";
CM_ SG_ 552 AGS_Calibration_Indicated "Feedback of Shutter calibration indicated";
CM_ SG_ 552 AGS_Calibration_Active "Feedback of  Shutter calibration active";
CM_ SG_ 552 AGS_Actuator_Fault "Feedback of Shutter actuator fault";
CM_ SG_ 552 AGS_Actuator_Blocked "Feedback of Shutter blocked";
CM_ SG_ 552 AGS_LINResponse_Error "Feedback of Response error bit";
CM_ SG_ 552 AGS_Calibration_Enabled "Command for start calibration sequence (rising edge)";
CM_ SG_ 552 AGS_Position_Request "AGS Position Request from Zone FR to AGS";
CM_ SG_ 552 FRTurnLampC "Front Right TurnLamp Current";
CM_ SG_ 552 FLTurnLampC "Front Left TurnLamp Current";
CM_ SG_ 552 ChargeInletLockSta "Charge Inlet lock signal status";
CM_ SG_ 552 FWiperProtection "Front Wiper Protection";
CM_ SG_ 552 FWiperAS "Front Wiper Auto Stop";
CM_ SG_ 554 PT_High_Tact "actual temperature of PT SENSOR_HIGH";
CM_ SG_ 554 EACProtectEnable "E-compressor protect enable";
CM_ SG_ 554 PT_High_P "Comp dis Pressure";
CM_ SG_ 554 PT_High_T "Comp dis Temperature";
CM_ SG_ 554 PT_Low_P2 "Heating Mode Pressure";
CM_ SG_ 554 PT_Low_T2 "Heating Mode Temperature";
CM_ SG_ 554 PT_Low_P1 "Cooling Mode Pressure";
CM_ SG_ 554 PT_Low_T1 "Cooling Mode Temperature";
CM_ SG_ 554 Tamb "AMB Temperature";
CM_ SG_ 554 Bat_Out_Temp "Battery Out Water Temperature";
CM_ SG_ 554 Bat_In_Temp "Battery In Water Temperature";
CM_ SG_ 554 Motor_Out_Temp "Motor Out Water Temperature";
CM_ SG_ 554 Motor_In_Temp "Motor In Water Temperature";
CM_ SG_ 554 FWV_Err "Four way valve error";
CM_ SG_ 554 TWV_Err "Three way valve error";
CM_ SG_ 554 EWP3_Err "NO3 electrical water pump error";
CM_ SG_ 554 EWP2_Err "NO2 electrical water pump error";
CM_ SG_ 554 EWP1_Err "NO1 electrical water pump error";
CM_ SG_ 554 WPTC_Err "Water PTC error";
CM_ SG_ 554 AGS_Err "Active grill shutter error";
CM_ SG_ 554 Fan_Err "Cooling fan error";
CM_ SG_ 554 EXV2_Err "NO2 electronic expansion valve error";
CM_ SG_ 554 EXV1_Err "NO1 electronic expansion valve error";
CM_ SG_ 554 SOTXV_Err "Thermal expansion valve with solenoid valve function is error";
CM_ SG_ 554 COMP_Err "Compressor error";
CM_ SG_ 554 SOV3_Err "NO3 solenoid valve error";
CM_ SG_ 554 SOV2_Err "NO2 solenoid valve error";
CM_ SG_ 554 SOV1_Err "NO1 solenoid valve error";
CM_ SG_ 554 PT_High_Tact_Err "The temperature of temperature and high pressure sensor is error";
CM_ SG_ 554 PT_High_P_Err "The pressure of temperature and high pressure sensor is error";
CM_ SG_ 554 PT_Low_T2_Err "The temperature of NO2 temperature and low pressure sensor is error";
CM_ SG_ 554 PT_Low_P2_Err "The pressure of NO2 temperature and low pressure sensor is error";
CM_ SG_ 554 PT_Low_T1_Err "The temperature of NO1 temperature and low pressure sensor is error";
CM_ SG_ 554 PT_Low_P1_Err "The pressure of NO1 temperature and low pressure sensor is error";
CM_ SG_ 554 Motor_Out_Temp_Err "Driver motor outlet water temperature sensor error";
CM_ SG_ 554 Bat_Out_Temp_Err "High voltage battery outlet water temperature sensor error";
CM_ SG_ 554 Motor_In_Temp_Err "Driver motor inlet water temperature sensor error";
CM_ SG_ 554 Bat_In_Temp_Err "High voltage battery inlet water temperature sensor error";
CM_ SG_ 554 Tamb_Err "Ambient temperature sensor error";
CM_ SG_ 570 HazardWarningReq "Hazard Warning Request";
CM_ SG_ 570 ADAS_AEB_Sta "AEB Status";
CM_ SG_ 570 RightTurnLightReq "Right Turning Light Request";
CM_ SG_ 570 ADAS_FCW_Sta "FCW Status";
CM_ SG_ 570 LeftTurnLightReq "Left Turning Light Request";
CM_ SG_ 570 ADAS_LDW_Sta "LDW Status";
CM_ SG_ 570 ADAS_FltWrnReq "ADAS Fault Warning Request";
CM_ SG_ 570 ADAS_ACC_Sta "ACC Status";
CM_ SG_ 570 ACC_ObjDstLvl "Object distance level (lvl.1 ~ lvl.4)";
CM_ SG_ 570 ForceLowBeam "Force Low Beam";
CM_ SG_ 570 TimeGapLevel "Time Gap Level";
CM_ SG_ 570 ACCSetSpeed "ACC Set Speed(if Distance_unit = 0x0, then UNIT = km/h, else  UNIT = mph)";
CM_ SG_ 570 ACCSetSpeed_Disp "ACC Set Speed Display";
CM_ SG_ 570 ACC_TakeoverReq "ACC takeover request";
CM_ SG_ 570 ADAS_WarningMsg "ADAS Warning Message";
CM_ SG_ 570 ADAS_CAM_SpdLim "ADAS Camera Speed Limitation";
CM_ SG_ 570 Target_Type "Target Type";
CM_ SG_ 570 ADAS_SLIF_SpdLim "ADAS SLIF Speed Limitation";
CM_ SG_ 570 FCM4_Checksum "The [CAN CheckSum] shall be calculated as a CRC8 with the following polynomial: x^8+x^4+x^3+x^2+1 (=0x1D), according with SAE-J1850-CRC8 Start value 0xFF";
CM_ SG_ 572 LKA_HOD_Display_Warning "LKA hands-off detection display warning signal";
CM_ SG_ 572 ADAS_LKA_Sta "LKA Status";
CM_ SG_ 572 LKA_HOD_Sound_Warning "LKA hands-off detection sound warning signal";
CM_ SG_ 572 ADAS_LFC_Sta "LFC Status";
CM_ SG_ 572 ADAS_LaneModeL "Left Lane Mode";
CM_ SG_ 572 ADAS_LaneModeR "Right Lane Mode";
CM_ SG_ 572 ADAS_SLIF_Sta "SLIF Status";
CM_ SG_ 572 ADAS_ISA_Sta "ISA Status";
CM_ SG_ 572 ADAS_LDW_Mute "LDW Mute Status";
CM_ SG_ 572 ADAS_FCW_Mute "FCW Mute Status";
CM_ SG_ 572 ADAS_LFC_Hands_Off_Warning "LFC Hands-Off Warning";
CM_ SG_ 572 LVDA_Disabled "LVDA_Disabled";
CM_ SG_ 572 LVDA_Mute_Sta "LVDA USM Setting";
CM_ SG_ 572 LVDA_Failinfo "LVDA Failinfo";
CM_ SG_ 572 LVDA_Warning "LVDA Warning";
CM_ SG_ 572 LVDA_ACCStatusInformation "ACC status information for LVDA";
CM_ SG_ 572 ADAS_LFC_Warn_Sound "LFC Warning Sound";
CM_ SG_ 572 FCM5_Checksum "The [CAN CheckSum] shall be calculated as a CRC8 with the following polynomial: x^8+x^4+x^3+x^2+1 (=0x1D), according with SAE-J1850-CRC8 Start value 0xFF";
CM_ SG_ 593 P_CommandToBCM "DKC command to BCM";
CM_ SG_ 593 P_DKey_Welcome "Digital key Welcome Area";
CM_ SG_ 593 P_DKey_Area_LockUnlock "Digital key  Lock and Unlock Area";
CM_ SG_ 593 P_DKey_Area_PS "Digital key PS Area";
CM_ SG_ 593 P_UID_LowPower "DKC UID low battery display";
CM_ SG_ 593 P_CommandToPTG "DKC command to PTG";
CM_ SG_ 593 P_Dkey_Show_IVI "Digital key IVI Show";
CM_ SG_ 593 P_KeyMode "DKC Key control Mode";
CM_ SG_ 593 P_DKey_Area_PTG "Digital key PTG Area";
CM_ SG_ 593 P_KeyMiss "DKC Key Miss";
CM_ SG_ 593 DKC_Remote_PW "DKC_Remote_PW";
CM_ SG_ 593 DKC_Re_VehData "Request for Remote VehData by DKC";
CM_ SG_ 593 DKC_P_UID_BatVolt "DKC UID battery voltage";
CM_ SG_ 593 DKC_P_BLE_RSSI "DKC BLE RSSI value";
CM_ SG_ 594 EncryptionDATA_64_127 "DKC Encryption DATA 64_127";
CM_ SG_ 594 EncryptionDATA_0_63 "DKC Encryption DATA 0-63";
CM_ SG_ 594 Random_Number_X "DKC Random Number X";
CM_ SG_ 595 IVI_Located_STA "IVI_GPS Satellite Located status";
CM_ SG_ 595 IVI_PTG_USSta_SW "Power Tail Gate Ultrasonic On/Off Switch";
CM_ SG_ 595 IVI_PTG_Open_Height "IVI 'PTG Open Height' Menu Status";
CM_ SG_ 595 Approach_Unlock_SW "Unlock when approaching Switch";
CM_ SG_ 595 Walkaway_Lock_SW "Lock when walking away";
CM_ SG_ 595 BrkSw_Sta "Brake switch signal status";
CM_ SG_ 595 DSEAT_anti_set "Driver Seat Antitheft on/off request";
CM_ SG_ 595 DSEAT_entryfun_set "Driver Seat Entry on/off request";
CM_ SG_ 595 IVI_PTG_Mode_SW "Power Tail Gate Manual and Automatic mode Switch";
CM_ SG_ 595 PSEAT_vent_req "Passenger Seat Ventilate request
0= No Request,
1= Vent1,
2= Vent2,
3= Vent3,
4= Off";
CM_ SG_ 595 IVI_PTG_Sta_SW "Power Tail Gate Open and Close Switch";
CM_ SG_ 595 IVI_ISA_OffsetSpd "IVI ISA Offset speed";
CM_ SG_ 595 SenstivityPosition "wiper Senstivity Position";
CM_ SG_ 595 IVI_Time_Check "IVI_GPS Satellite Time_Check Sum";
CM_ SG_ 595 IVI_Time_Year "IVI_GPS Satellite Time_Year";
CM_ SG_ 595 Hood_Latch_SW "Hood Latch Switch";
CM_ SG_ 595 IVI_Time_Minute "IVI_GPS Satellite Time_Minute";
CM_ SG_ 595 TurnSwTimeSet "turning switch flash time set";
CM_ SG_ 595 IVI_Time_Second "IVI_GPS Satellite Time_Second";
CM_ SG_ 595 DSEAT_vent_req "Driver Seat ventilate request";
CM_ SG_ 595 IVI_Time_Day "IVI_GPS Satellite Time_Day";
CM_ SG_ 595 HeadLampSW "Head Lamp Switch";
CM_ SG_ 595 IVI_Time_Hour "IVI_GPS Satellite Time_Hour";
CM_ SG_ 595 IVI_Time_Month "IVI_GPS Satellite Time_Month";
CM_ SG_ 595 PTG_Inner_SW2 "FUSION Power Tail Gate Inner SW#2 State";
CM_ SG_ 595 L_Drv_CtrlCmd "Driver Window Control  Command
FDC BCM Tx";
CM_ SG_ 595 L_Pas_CtrlCmd "Passenger Window Control  Command
FDC BCM Tx";
CM_ SG_ 595 L_RLD_CtrlCmd "Rear Left Window Control  Command
FDC BCM Tx";
CM_ SG_ 595 L_RRD_CtrlCmd "Rear Right Window Control  Command
FDC BCM Tx";
CM_ SG_ 595 OFF_AC_MODE "OFF AC MODE";
CM_ SG_ 595 BrkSw_V "Brake switch signal Vaild";
CM_ SG_ 595 MCPressure "Master Cylinder Pressure";
CM_ SG_ 595 MCPressure_V "Master Cylinder Pressure Validity";
CM_ SG_ 595 BrkPedalPos "Brake Pedal Position";
CM_ SG_ 595 BrkPedalPos_Sta "Brake Pedal Position Status";
CM_ SG_ 595 FDC_BCM_LockAlarm_Cmd "Lock alarm command";
CM_ SG_ 595 FDC_THCM_ACTInitial_Cmd "Actuator Initial Command";
CM_ SG_ 595 FDC_BCM_ATCtrl_Cmd "Antitheft Lamp Control";
CM_ SG_ 595 FDC_BCM_OutMode_Cmd "Output mode for turn lamps";

BA_DEF_ "NmType" STRING ;
BA_DEF_ "VersionYear" INT 2010 2999;
BA_DEF_ "ProtocolType" STRING ;
BA_DEF_ "NmMessageCount" INT 0 255;
BA_DEF_ "NmBaseAddress" HEX 1280 1407;
BA_DEF_ "DBName" STRING ;
BA_DEF_ "BusType" STRING ;
BA_DEF_ "Baudrate" INT 0 1000000;
BA_DEF_ "Datarate" INT 0 2000000;
BA_DEF_ BU_ "NodeLayerModules" STRING ;
BA_DEF_ BU_ "NmCAN" INT 1 2;
BA_DEF_ BU_ "ILUsed" ENUM "No","Yes";
BA_DEF_ BU_ "CANFD_CANFD_Gateway" ENUM "Yes","No";
BA_DEF_ BU_ "CAN_CANFD_Gateway" ENUM "Yes","No";
BA_DEF_ BU_ "CANFD_LIN_Gateway" ENUM "Yes","No";
BA_DEF_ BO_ "GenMsgSendType" ENUM "Cycle","NoMsgSendType","IfActive","Event","CA","CE";
BA_DEF_ BO_ "GenMsgNrOfRepetition" INT 0 0;
BA_DEF_ BO_ "GenMsgILSupport" ENUM "No","Yes";
BA_DEF_ BO_ "GenMsgDelayTime" INT 0 0;
BA_DEF_ BO_ "GenMsgCycleTimeFast" INT 0 0;
BA_DEF_ BO_ "GenMsgCycleTime" INT 0 0;
BA_DEF_ BO_ "DiagResponse" ENUM "No","Yes";
BA_DEF_ BO_ "DiagRequest" ENUM "No","Yes";
BA_DEF_ BO_ "NmMessage" ENUM "No","Yes";
BA_DEF_ BO_ "VFrameFormat" ENUM "StandardCAN","ExtendedCAN","reserved","reserved","reserved","reserved","reserved","reserved","reserved","reserved","reserved","reserved","reserved","reserved","StandardCAN_FD","ExtendedCAN_FD";
BA_DEF_ BO_ "GenMsgRequestable" INT 0 1;
BA_DEF_ BO_ "DataID_Hex" HEX 0 65535;
BA_DEF_ BO_ "DoIPLogicalAddress" STRING ;
BA_DEF_ BO_ "DataID" STRING ;
BA_DEF_ BO_ "CANFD_BRS" ENUM "0","1";
BA_DEF_ SG_ "GenSigInvalidValue" HEX 0 0;
BA_DEF_ SG_ "GenSigStartValue" HEX 0 0;
BA_DEF_ SG_ "GenSigInactiveValue" HEX 0 0;
BA_DEF_ SG_ "GenSigRoutingTimeoutValue" HEX 0 0;
BA_DEF_ SG_ "GenSigSendType" ENUM "Cycle","OnWrite","OnWriteWithRepetition","OnChange","OnChangeWithRepetition","IfActive","IfActiveWithRepetition","NoSigSendType","vector_leerstring";
BA_DEF_ SG_ "SigType" ENUM "Default","Range","RangeSigned","ASCII","Discrete","Control","ReferencePGN","DTC","StringDelimiter","StringLength","StringLengthControl","MessageCounter","MessageChecksum";
BA_DEF_ SG_ "GenSigILSupport" ENUM "No","Yes";
BA_DEF_DEF_ "NmType" "AUTOSAR";
BA_DEF_DEF_ "VersionYear" 2023;
BA_DEF_DEF_ "ProtocolType" "CAN";
BA_DEF_DEF_ "NmMessageCount" 128;
BA_DEF_DEF_ "NmBaseAddress" 1280;
BA_DEF_DEF_ "DBName" "";
BA_DEF_DEF_ "BusType" "";
BA_DEF_DEF_ "Baudrate" 500000;
BA_DEF_DEF_ "Datarate" 2000000;
BA_DEF_DEF_ "NodeLayerModules" "CANoeILNLVector.dll";
BA_DEF_DEF_ "NmCAN" 2;
BA_DEF_DEF_ "ILUsed" "Yes";
BA_DEF_DEF_ "CANFD_CANFD_Gateway" "No";
BA_DEF_DEF_ "CAN_CANFD_Gateway" "No";
BA_DEF_DEF_ "CANFD_LIN_Gateway" "No";
BA_DEF_DEF_ "GenMsgSendType" "Cycle";
BA_DEF_DEF_ "GenMsgNrOfRepetition" 0;
BA_DEF_DEF_ "GenMsgILSupport" "Yes";
BA_DEF_DEF_ "GenMsgDelayTime" 0;
BA_DEF_DEF_ "GenMsgCycleTimeFast" 0;
BA_DEF_DEF_ "GenMsgCycleTime" 100;
BA_DEF_DEF_ "DiagResponse" "No";
BA_DEF_DEF_ "DiagRequest" "No";
BA_DEF_DEF_ "NmMessage" "No";
BA_DEF_DEF_ "VFrameFormat" "StandardCAN";
BA_DEF_DEF_ "GenMsgRequestable" 1;
BA_DEF_DEF_ "DataID_Hex" 0;
BA_DEF_DEF_ "DoIPLogicalAddress" "";
BA_DEF_DEF_ "DataID" "";
BA_DEF_DEF_ "CANFD_BRS" "1";
BA_DEF_DEF_ "GenSigInvalidValue" 0;
BA_DEF_DEF_ "GenSigStartValue" 0;
BA_DEF_DEF_ "GenSigInactiveValue" 0;
BA_DEF_DEF_ "GenSigRoutingTimeoutValue" 0;
BA_DEF_DEF_ "GenSigSendType" "Cycle";
BA_DEF_DEF_ "SigType" "Default";
BA_DEF_DEF_ "GenSigILSupport" "Yes";
BA_ "BusType" "CAN FD";
BA_ "ProtocolType" "CAN FD";
BA_ "DBName" "CAN4";
BA_ "CANFD_CANFD_Gateway" BU_ FUSION 0;
BA_ "CAN_CANFD_Gateway" BU_ ZONE_FR 0;
BA_ "CANFD_LIN_Gateway" BU_ ZONE_FR 0;
BA_ "CAN_CANFD_Gateway" BU_ ZONE_DR 0;
BA_ "CANFD_LIN_Gateway" BU_ ZONE_DR 0;
BA_ "GenMsgNrOfRepetition" BO_ 278 1;
BA_ "DataID_Hex" BO_ 278 19720;
BA_ "DataID" BO_ 278 "0x4D08";
BA_ "GenMsgCycleTimeFast" BO_ 278 10;
BA_ "GenMsgSendType" BO_ 278 3;
BA_ "VFrameFormat" BO_ 278 14;
BA_ "GenMsgNrOfRepetition" BO_ 374 1;
BA_ "GenMsgCycleTimeFast" BO_ 374 10;
BA_ "GenMsgSendType" BO_ 374 5;
BA_ "VFrameFormat" BO_ 374 14;
BA_ "GenMsgNrOfRepetition" BO_ 378 1;
BA_ "GenMsgCycleTimeFast" BO_ 378 10;
BA_ "GenMsgSendType" BO_ 378 5;
BA_ "VFrameFormat" BO_ 378 14;
BA_ "GenMsgCycleTime" BO_ 380 10;
BA_ "VFrameFormat" BO_ 380 14;
BA_ "VFrameFormat" BO_ 386 14;
BA_ "GenMsgNrOfRepetition" BO_ 390 1;
BA_ "GenMsgCycleTimeFast" BO_ 390 10;
BA_ "GenMsgSendType" BO_ 390 5;
BA_ "VFrameFormat" BO_ 390 14;
BA_ "GenMsgNrOfRepetition" BO_ 497 1;
BA_ "GenMsgCycleTime" BO_ 497 20;
BA_ "GenMsgCycleTimeFast" BO_ 497 5;
BA_ "GenMsgSendType" BO_ 497 5;
BA_ "VFrameFormat" BO_ 497 14;
BA_ "GenMsgNrOfRepetition" BO_ 498 1;
BA_ "GenMsgCycleTime" BO_ 498 20;
BA_ "GenMsgCycleTimeFast" BO_ 498 5;
BA_ "GenMsgSendType" BO_ 498 5;
BA_ "VFrameFormat" BO_ 498 14;
BA_ "GenMsgNrOfRepetition" BO_ 547 1;
BA_ "GenMsgCycleTimeFast" BO_ 547 50;
BA_ "VFrameFormat" BO_ 547 14;
BA_ "GenMsgNrOfRepetition" BO_ 549 1;
BA_ "GenMsgCycleTimeFast" BO_ 549 10;
BA_ "GenMsgSendType" BO_ 549 5;
BA_ "VFrameFormat" BO_ 549 14;
BA_ "GenMsgNrOfRepetition" BO_ 550 1;
BA_ "GenMsgCycleTime" BO_ 550 200;
BA_ "GenMsgCycleTimeFast" BO_ 550 50;
BA_ "GenMsgSendType" BO_ 550 5;
BA_ "VFrameFormat" BO_ 550 14;
BA_ "GenMsgNrOfRepetition" BO_ 552 1;
BA_ "GenMsgCycleTime" BO_ 552 200;
BA_ "GenMsgCycleTimeFast" BO_ 552 50;
BA_ "GenMsgSendType" BO_ 552 5;
BA_ "VFrameFormat" BO_ 552 14;
BA_ "GenMsgNrOfRepetition" BO_ 554 1;
BA_ "GenMsgCycleTimeFast" BO_ 554 10;
BA_ "GenMsgSendType" BO_ 554 5;
BA_ "VFrameFormat" BO_ 554 14;
BA_ "GenMsgNrOfRepetition" BO_ 570 1;
BA_ "GenMsgCycleTimeFast" BO_ 570 10;
BA_ "VFrameFormat" BO_ 570 14;
BA_ "GenMsgNrOfRepetition" BO_ 572 1;
BA_ "GenMsgCycleTimeFast" BO_ 572 10;
BA_ "VFrameFormat" BO_ 572 14;
BA_ "GenMsgNrOfRepetition" BO_ 593 1;
BA_ "GenMsgCycleTimeFast" BO_ 593 10;
BA_ "GenMsgSendType" BO_ 593 5;
BA_ "VFrameFormat" BO_ 593 14;
BA_ "GenMsgNrOfRepetition" BO_ 594 1;
BA_ "GenMsgCycleTimeFast" BO_ 594 10;
BA_ "GenMsgSendType" BO_ 594 5;
BA_ "VFrameFormat" BO_ 594 14;
BA_ "GenMsgNrOfRepetition" BO_ 595 1;
BA_ "GenMsgCycleTimeFast" BO_ 595 10;
BA_ "GenMsgSendType" BO_ 595 5;
BA_ "VFrameFormat" BO_ 595 14;
BA_ "GenSigInvalidValue" SG_ 278 MSA_Crl_Sta 6;
BA_ "GenSigSendType" SG_ 278 MSA_Crl_Sta 1;
BA_ "GenSigSendType" SG_ 278 VehSpeed 1;
BA_ "GenSigSendType" SG_ 278 DKCAuthSta 1;
BA_ "GenSigSendType" SG_ 278 EquivAccPedalSWSta 1;
BA_ "GenSigSendType" SG_ 278 TimeSNDKCFbk 1;
BA_ "GenSigSendType" SG_ 278 DKCTimeSN 1;
BA_ "GenSigSendType" SG_ 278 Dr_SeatSta 1;
BA_ "GenSigSendType" SG_ 278 RC_VCU1_CAN4 1;
BA_ "GenSigSendType" SG_ 278 CS_VCU1_CAN4 1;
BA_ "GenSigInvalidValue" SG_ 278 CC_Crl_Sta 6;
BA_ "GenSigSendType" SG_ 278 CC_Crl_Sta 1;
BA_ "GenSigSendType" SG_ 278 ShiftGearPosn 1;
BA_ "GenSigSendType" SG_ 278 PwrSta 1;
BA_ "GenSigSendType" SG_ 278 ReBrakeLPReq 1;
BA_ "GenSigSendType" SG_ 278 HornCtrl 1;
BA_ "GenSigSendType" SG_ 278 BCM_DoorLock_Sta 1;
BA_ "GenSigSendType" SG_ 278 DimmerEN 1;
BA_ "GenSigSendType" SG_ 278 RoomLampH 1;
BA_ "GenSigSendType" SG_ 278 RoomLampL 1;
BA_ "GenSigSendType" SG_ 278 TailgateRemote 1;
BA_ "GenSigSendType" SG_ 278 BCM_Buzzer_Req 1;
BA_ "GenSigSendType" SG_ 278 LockSetting 1;
BA_ "GenSigInvalidValue" SG_ 278 Dimmer 127;
BA_ "GenSigSendType" SG_ 278 Dimmer 1;
BA_ "GenSigSendType" SG_ 278 L_APM_WdwEnable 1;
BA_ "GenSigSendType" SG_ 278 CrashDetd 1;
BA_ "GenSigSendType" SG_ 278 AntiTheftSeatFold 1;
BA_ "GenSigSendType" SG_ 278 AntitheftSta 1;
BA_ "GenSigSendType" SG_ 278 RTurnLP 1;
BA_ "GenSigSendType" SG_ 278 LTurnLP 1;
BA_ "GenSigSendType" SG_ 278 HazardSW 1;
BA_ "GenSigSendType" SG_ 278 Rr_FogLamp 1;
BA_ "GenSigSendType" SG_ 278 Fr_FogLamp 1;
BA_ "GenSigSendType" SG_ 278 RBSD 1;
BA_ "GenSigSendType" SG_ 278 LBSD 1;
BA_ "GenSigSendType" SG_ 278 BrakeLamp 1;
BA_ "GenSigSendType" SG_ 278 ReverseLamp 1;
BA_ "GenSigSendType" SG_ 278 RDRL 1;
BA_ "GenSigSendType" SG_ 278 LDRL 1;
BA_ "GenSigSendType" SG_ 278 PosLamp 1;
BA_ "GenSigSendType" SG_ 278 H_Beam 1;
BA_ "GenSigSendType" SG_ 278 L_Beam 1;
BA_ "GenSigSendType" SG_ 278 WasherCtrl 1;
BA_ "GenSigSendType" SG_ 278 WiperFixMode 1;
BA_ "GenSigSendType" SG_ 278 Rr_Wiper 1;
BA_ "GenSigSendType" SG_ 278 Fr_Wiper_L 1;
BA_ "GenSigSendType" SG_ 278 Fr_Wiper_H 1;
BA_ "GenSigSendType" SG_ 278 MirrorCtrl 1;
BA_ "GenSigSendType" SG_ 278 TailgateHDSW 1;
BA_ "GenSigSendType" SG_ 278 TrunkRel 1;
BA_ "GenSigSendType" SG_ 278 Rr_Defog 1;
BA_ "GenSigSendType" SG_ 278 MirrorDefog 1;
BA_ "GenSigSendType" SG_ 278 CTDUnlockSW 1;
BA_ "GenSigSendType" SG_ 278 CTDLockSW 1;
BA_ "GenSigSendType" SG_ 278 Rr_ChargingDoorCtrl 1;
BA_ "GenSigSendType" SG_ 278 Fr_ChargingDoorCtrl 1;
BA_ "GenSigSendType" SG_ 278 CTDCtrl 1;
BA_ "GenSigSendType" SG_ 278 Tailgate_SW 1;
BA_ "GenSigSendType" SG_ 278 HoodSW 1;
BA_ "GenSigSendType" SG_ 278 DoorLockIND 1;
BA_ "GenSigSendType" SG_ 278 AllDoorSW 1;
BA_ "GenSigSendType" SG_ 278 RRDoorSW 1;
BA_ "GenSigSendType" SG_ 278 RLDoorSW 1;
BA_ "GenSigSendType" SG_ 278 PsDoorSW 1;
BA_ "GenSigSendType" SG_ 278 DrDoorSW 1;
BA_ "GenSigSendType" SG_ 278 FD_TBOX_VehData_Sta 1;
BA_ "GenSigSendType" SG_ 278 FD_TBOX_VehData_Err 1;
BA_ "GenSigSendType" SG_ 278 FD_DKC_VehData_Sta 1;
BA_ "GenSigSendType" SG_ 278 FD_DKC_VehData_Err 1;
BA_ "GenSigSendType" SG_ 278 FD_TBOX_DTCData_Sta 1;
BA_ "GenSigSendType" SG_ 278 FD_TBOX_DTCData_Err 1;
BA_ "GenSigSendType" SG_ 278 AmbLightBreath3 1;
BA_ "GenSigSendType" SG_ 278 AmbLightBreath2 1;
BA_ "GenSigSendType" SG_ 278 LampPwr 1;
BA_ "GenSigSendType" SG_ 278 AmbLightBreath1 1;
BA_ "GenSigSendType" SG_ 278 AmbLightColor3 1;
BA_ "GenSigSendType" SG_ 278 AmbLightColor2 1;
BA_ "GenSigSendType" SG_ 278 AmbLightColor1 1;
BA_ "GenSigSendType" SG_ 278 AmbLightBrightness3 1;
BA_ "GenSigSendType" SG_ 278 AmbLightBrightness2 1;
BA_ "GenSigSendType" SG_ 278 AmbLightBrightness1 1;
BA_ "GenSigInvalidValue" SG_ 278 VehSpeed 4095;
BA_ "GenSigRoutingTimeoutValue" SG_ 278 VehSpeed 4095;
BA_ "GenSigSendType" SG_ 278 HWResetSta 1;
BA_ "GenSigSendType" SG_ 278 CtrlFrPwrStbA1P 1;
BA_ "GenSigSendType" SG_ 278 CtrlFrIRC1 1;
BA_ "GenSigSendType" SG_ 278 CtrlFrBMSCCUCIR 1;
BA_ "GenSigSendType" SG_ 278 CtrlFrEDUINVERTER 1;
BA_ "GenSigSendType" SG_ 278 CtrlDrPwrStbA2 1;
BA_ "GenSigStartValue" SG_ 374 OBCDCCurLm 255;
BA_ "GenSigSendType" SG_ 374 ReChargerStaFromEvcc 3;
BA_ "GenSigSendType" SG_ 378 V2LSta 3;
BA_ "GenSigSendType" SG_ 378 HVBChrgErr 3;
BA_ "GenSigSendType" SG_ 378 DisChrgPlugErr 3;
BA_ "GenSigSendType" SG_ 378 ChrgInLockReq 3;
BA_ "GenSigSendType" SG_ 378 HVBCellUnbalanErr 3;
BA_ "GenSigSendType" SG_ 378 HVBCellUndrVoltErr 3;
BA_ "GenSigSendType" SG_ 378 HVBCellOvrVoltErr 3;
BA_ "GenSigSendType" SG_ 378 HVBCellUdrVoltWarn 3;
BA_ "GenSigSendType" SG_ 378 HVBCellOvrVoltWarn 3;
BA_ "GenSigSendType" SG_ 378 CellUnconsistErr 3;
BA_ "GenSigSendType" SG_ 378 SystemUncomErr 3;
BA_ "GenSigSendType" SG_ 378 IsoDetSta 3;
BA_ "GenSigSendType" SG_ 378 HVBPreheatPrecoolSta 3;
BA_ "GenSigSendType" SG_ 378 ExtChrgSta 3;
BA_ "GenSigSendType" SG_ 378 ChrgPlugSta 3;
BA_ "GenSigSendType" SG_ 378 HVBattReady4Pre 3;
BA_ "GenSigSendType" SG_ 378 HVILSta 3;
BA_ "GenSigSendType" SG_ 378 HVBTempDiffErr 3;
BA_ "GenSigSendType" SG_ 378 HVBPrechrgSta 3;
BA_ "GenSigSendType" SG_ 378 HVBContactorSta 3;
BA_ "GenSigSendType" SG_ 378 BMS_READY 3;
BA_ "GenSigSendType" SG_ 378 DCChrgSysShockErr 3;
BA_ "GenSigSendType" SG_ 378 HVBHVILErr 3;
BA_ "GenSigSendType" SG_ 378 HVBSOCJumpError 3;
BA_ "GenSigSendType" SG_ 378 HVBUndrSOCErr 3;
BA_ "GenSigSendType" SG_ 378 HVBOvrSOCErr 3;
BA_ "GenSigSendType" SG_ 378 HVBUndrTempErr 3;
BA_ "GenSigSendType" SG_ 378 HVBOvrTempErr 3;
BA_ "GenSigSendType" SG_ 378 HVBOvrDchrgCurErr 3;
BA_ "GenSigSendType" SG_ 378 HVBOvrChrgCurrErr 3;
BA_ "GenSigSendType" SG_ 378 HVBShrtDischrgCurrErr 3;
BA_ "GenSigSendType" SG_ 378 HVBShrtChrgCurrErr 3;
BA_ "GenSigSendType" SG_ 378 HVBUndrVoltErr 3;
BA_ "GenSigSendType" SG_ 378 HVBOvrVoltErr 3;
BA_ "GenSigSendType" SG_ 378 HVBUndrTempWarn 3;
BA_ "GenSigSendType" SG_ 378 HVBOvrTempWarn 3;
BA_ "GenSigSendType" SG_ 378 BMS_Warn_8 3;
BA_ "GenSigSendType" SG_ 378 BMS_Warn_7 3;
BA_ "GenSigSendType" SG_ 378 BMS_Warn_6 3;
BA_ "GenSigSendType" SG_ 378 BMS_Warn_5 3;
BA_ "GenSigSendType" SG_ 378 BMS_Warn_4 3;
BA_ "GenSigSendType" SG_ 378 BMS_Warn_3 3;
BA_ "GenSigSendType" SG_ 378 BMS_Warn_2 3;
BA_ "GenSigSendType" SG_ 378 BMS_Warn_1 3;
BA_ "GenSigInvalidValue" SG_ 380 ACC_ObjDist 2047;
BA_ "GenSigStartValue" SG_ 380 ACC_ObjDist 2046;
BA_ "GenSigInvalidValue" SG_ 380 ACC_ObjRelSpd 2047;
BA_ "GenSigStartValue" SG_ 386 Fr_Coolanttemp 40;
BA_ "GenSigInvalidValue" SG_ 386 sigAirIntenZon1St 15;
BA_ "GenSigInvalidValue" SG_ 386 sigAmbAirT 255;
BA_ "GenSigStartValue" SG_ 386 sigCbnSolarRight 253;
BA_ "GenSigStartValue" SG_ 386 sigCbnSolarLeft 253;
BA_ "GenSigStartValue" SG_ 386 sigClntTHvBattOut 120;
BA_ "GenSigStartValue" SG_ 386 Rr_Coolanttemp 40;
BA_ "GenSigSendType" SG_ 390 FD_Blower_Cmd 3;
BA_ "GenSigSendType" SG_ 390 FD_Comp_Cmd 3;
BA_ "GenSigInvalidValue" SG_ 390 FD_FrRiAPTCHeatPwr_Cmd 255;
BA_ "GenSigSendType" SG_ 390 FD_FrRiAPTCHeatPwr_Cmd 3;
BA_ "GenSigInvalidValue" SG_ 390 FD_FrLeAPTCHeatPwr_Cmd 255;
BA_ "GenSigSendType" SG_ 390 FD_FrLeAPTCHeatPwr_Cmd 3;
BA_ "GenSigSendType" SG_ 390 FD_RrAPTCHeatPwr_Cmd 3;
BA_ "GenSigInvalidValue" SG_ 390 FD_FrWPTCHeatPwr_Cmd 255;
BA_ "GenSigSendType" SG_ 390 FD_FrWPTCHeatPwr_Cmd 3;
BA_ "GenSigInvalidValue" SG_ 390 FD_EWP3_Cmd 255;
BA_ "GenSigInvalidValue" SG_ 390 FD_EWP2_Cmd 255;
BA_ "GenSigInvalidValue" SG_ 390 FD_EWP1_Cmd 255;
BA_ "GenSigSendType" SG_ 390 APTC_ActFrRiPwr 3;
BA_ "GenSigSendType" SG_ 390 CoolgFanActDuty 3;
BA_ "GenSigSendType" SG_ 497 DrPMMSysErrLmp 3;
BA_ "GenSigSendType" SG_ 497 DrPMMLVOutPErrLmp 3;
BA_ "GenSigSendType" SG_ 497 DrPMMLimpHomeActReq 3;
BA_ "GenSigSendType" SG_ 497 DrAPWStaErr 3;
BA_ "GenSigSendType" SG_ 497 DrAPWLINErr 3;
BA_ "GenSigSendType" SG_ 497 DrONA1ErrSta 3;
BA_ "GenSigSendType" SG_ 497 DrStdAErrSta 3;
BA_ "GenSigSendType" SG_ 497 DrPwrWinErrSta 3;
BA_ "GenSigSendType" SG_ 497 DrInfoErrSta 3;
BA_ "GenSigSendType" SG_ 497 ZoneDrMalfunLevel 3;
BA_ "GenSigSendType" SG_ 497 ZDR_SYS_APMRetryCnt_Sta 3;
BA_ "GenSigSendType" SG_ 497 ZDR_SYS_CSWRetryCnt_Sta 3;
BA_ "GenSigSendType" SG_ 497 ZDR_SYS_BSWSleepReq_Sta 3;
BA_ "GenSigSendType" SG_ 497 ZDR_VCU_HWReset_Sta 3;
BA_ "GenSigSendType" SG_ 497 ZDR_VCU_PwrSupply_Sta 3;
BA_ "GenSigSendType" SG_ 498 FrPMMSysErrLmp 3;
BA_ "GenSigSendType" SG_ 498 FrPMMLVOutPErrLmp 3;
BA_ "GenSigSendType" SG_ 498 FrPMMLimpHomeActReq 3;
BA_ "GenSigSendType" SG_ 498 ZFR_SYS_BMSCCURetryCnt_Sta 3;
BA_ "GenSigSendType" SG_ 498 ZFR_SYS_MCURetryCnt_Sta 3;
BA_ "GenSigSendType" SG_ 498 ZoneFrMalfunLevel 3;
BA_ "GenSigSendType" SG_ 498 ZFR_SYS_BSWSleepReq_Sta 3;
BA_ "GenSigSendType" SG_ 498 FrStdA1PCErr 3;
BA_ "GenSigSendType" SG_ 498 FrStdA2PCErr 3;
BA_ "GenSigSendType" SG_ 498 FrStdA2PErr 3;
BA_ "GenSigSendType" SG_ 498 FrBMSCCUCErr 3;
BA_ "GenSigSendType" SG_ 498 FrEDUErr 3;
BA_ "GenSigSendType" SG_ 498 FrPwrSta 3;
BA_ "GenSigSendType" SG_ 498 ZFR_VCU_HWReset_Sta 3;
BA_ "GenSigSendType" SG_ 498 ZFR_VCU_PwrSupply_Sta 3;
BA_ "GenSigStartValue" SG_ 547 FrntPTCLeCoreT 255;
BA_ "GenSigStartValue" SG_ 547 FrntPTCRiCoreT 255;
BA_ "GenSigStartValue" SG_ 547 FrntPTCLeActHeatPwr 255;
BA_ "GenSigStartValue" SG_ 547 FrntPTCRiActHeatPwr 255;
BA_ "GenSigStartValue" SG_ 547 FrntPTCLeIGBTT 255;
BA_ "GenSigStartValue" SG_ 547 FrntPTCRiIGBTT 255;
BA_ "GenSigStartValue" SG_ 547 FrntPTCPCBT 255;
BA_ "GenSigStartValue" SG_ 549 SolarR 253;
BA_ "GenSigStartValue" SG_ 549 SolarL 253;
BA_ "GenSigSendType" SG_ 549 APTC_Err 3;
BA_ "GenSigSendType" SG_ 549 Blower_Err 3;
BA_ "GenSigSendType" SG_ 549 T_Foot_Rr_Err 3;
BA_ "GenSigSendType" SG_ 549 T_Face_Rr_Err 3;
BA_ "GenSigSendType" SG_ 549 T_Foot_R_Err 3;
BA_ "GenSigSendType" SG_ 549 T_Face_R_Err 3;
BA_ "GenSigSendType" SG_ 549 T_Foot_L_Err 3;
BA_ "GenSigSendType" SG_ 549 T_Face_L_Err 3;
BA_ "GenSigSendType" SG_ 549 Tincar_Err 3;
BA_ "GenSigSendType" SG_ 549 Tevap_Err 3;
BA_ "GenSigSendType" SG_ 549 SolarR_Err 3;
BA_ "GenSigSendType" SG_ 549 SolarL_Err 3;
BA_ "GenSigSendType" SG_ 549 ZDR_THCM_IntakeFail_Sta 3;
BA_ "GenSigSendType" SG_ 549 ZDR_THCM_ModeFail_Sta 3;
BA_ "GenSigSendType" SG_ 549 ZDR_THCM_LINACT1_Sta 3;
BA_ "GenSigSendType" SG_ 549 ZDR_THCM_LINACT2_Sta 3;
BA_ "GenSigSendType" SG_ 549 ZDR_THCM_LINACT3_Sta 3;
BA_ "GenSigSendType" SG_ 549 ZDR_THCM_LINACT4_Sta 3;
BA_ "GenSigSendType" SG_ 549 ZDR_THCM_LINACT5_Sta 3;
BA_ "GenSigSendType" SG_ 550 RLS_LIN_Resp_Err 3;
BA_ "GenSigSendType" SG_ 550 RLS_LightSnrErr 3;
BA_ "GenSigSendType" SG_ 550 RLS_RainSnrErr 3;
BA_ "GenSigSendType" SG_ 550 WiperZeroPosSW 3;
BA_ "GenSigSendType" SG_ 550 AutoLightSW 3;
BA_ "GenSigSendType" SG_ 550 CSW_resp_error 3;
BA_ "GenSigSendType" SG_ 550 WiperSWPos 3;
BA_ "GenSigSendType" SG_ 550 RLS_Lamp_Sta 3;
BA_ "GenSigSendType" SG_ 550 RLS_RainSnrWiperCmd 3;
BA_ "GenSigRoutingTimeoutValue" SG_ 550 CSW_FWipSw_Sta 7;
BA_ "GenSigSendType" SG_ 550 CSW_FWipSw_Sta 3;
BA_ "GenSigSendType" SG_ 550 HornSW 3;
BA_ "GenSigRoutingTimeoutValue" SG_ 550 CSW_TurnSw_Sta 3;
BA_ "GenSigSendType" SG_ 550 CSW_TurnSw_Sta 3;
BA_ "GenSigRoutingTimeoutValue" SG_ 550 CSW_RWasSW_Sta 3;
BA_ "GenSigSendType" SG_ 550 CSW_RWasSW_Sta 3;
BA_ "GenSigRoutingTimeoutValue" SG_ 550 CSW_FWasSw_Sta 3;
BA_ "GenSigSendType" SG_ 550 CSW_FWasSw_Sta 3;
BA_ "GenSigSendType" SG_ 550 RRTurnLampC 3;
BA_ "GenSigSendType" SG_ 550 RLTurnLampC 3;
BA_ "GenSigSendType" SG_ 550 RLS_Exist 3;
BA_ "GenSigSendType" SG_ 550 CSW_PassSW_Sta 3;
BA_ "GenSigSendType" SG_ 550 BrakeLampFail 3;
BA_ "GenSigSendType" SG_ 550 CSW_DimSw 3;
BA_ "GenSigRoutingTimeoutValue" SG_ 550 CSW_RWipIntSw_Sta 3;
BA_ "GenSigSendType" SG_ 550 CSW_RWipIntSw_Sta 3;
BA_ "GenSigSendType" SG_ 550 Wip_Speed 3;
BA_ "GenSigSendType" SG_ 550 RWiperProtection 3;
BA_ "GenSigSendType" SG_ 550 RWiperAS 3;
BA_ "GenSigSendType" SG_ 550 MIRROR_FOLD_SW 3;
BA_ "GenSigSendType" SG_ 550 AllLockSta 3;
BA_ "GenSigSendType" SG_ 550 RRLockSta 3;
BA_ "GenSigSendType" SG_ 550 RLLockSta 3;
BA_ "GenSigSendType" SG_ 550 PsLockSta 3;
BA_ "GenSigSendType" SG_ 550 DrLockSta 3;
BA_ "GenSigStartValue" SG_ 552 AGS_Actual_Position 127;
BA_ "GenSigSendType" SG_ 552 FRTurnLampC 3;
BA_ "GenSigSendType" SG_ 552 FLTurnLampC 3;
BA_ "GenSigSendType" SG_ 552 FWiperProtection 3;
BA_ "GenSigSendType" SG_ 552 FWiperAS 3;
BA_ "GenSigInvalidValue" SG_ 552 EWP2_RPM_Target_EWP_Rq 255;
BA_ "GenSigInvalidValue" SG_ 552 EWP3_RPM_Target_EWP_Rq 255;
BA_ "GenSigInvalidValue" SG_ 552 EWP1_RPM_Target_EWP_Rq 255;
BA_ "GenSigSendType" SG_ 554 EACProtectEnable 3;
BA_ "GenSigStartValue" SG_ 554 PT_High_P 2700;
BA_ "GenSigSendType" SG_ 554 FWV_Err 3;
BA_ "GenSigSendType" SG_ 554 TWV_Err 3;
BA_ "GenSigSendType" SG_ 554 EWP3_Err 3;
BA_ "GenSigSendType" SG_ 554 EWP2_Err 3;
BA_ "GenSigSendType" SG_ 554 EWP1_Err 3;
BA_ "GenSigSendType" SG_ 554 WPTC_Err 3;
BA_ "GenSigSendType" SG_ 554 AGS_Err 3;
BA_ "GenSigSendType" SG_ 554 Fan_Err 3;
BA_ "GenSigSendType" SG_ 554 EXV2_Err 3;
BA_ "GenSigSendType" SG_ 554 EXV1_Err 3;
BA_ "GenSigSendType" SG_ 554 SOTXV_Err 3;
BA_ "GenSigSendType" SG_ 554 COMP_Err 3;
BA_ "GenSigSendType" SG_ 554 SOV3_Err 3;
BA_ "GenSigSendType" SG_ 554 SOV2_Err 3;
BA_ "GenSigSendType" SG_ 554 SOV1_Err 3;
BA_ "GenSigSendType" SG_ 554 PT_High_Tact_Err 3;
BA_ "GenSigSendType" SG_ 554 PT_High_P_Err 3;
BA_ "GenSigSendType" SG_ 554 PT_Low_T2_Err 3;
BA_ "GenSigSendType" SG_ 554 PT_Low_P2_Err 3;
BA_ "GenSigSendType" SG_ 554 PT_Low_T1_Err 3;
BA_ "GenSigSendType" SG_ 554 PT_Low_P1_Err 3;
BA_ "GenSigSendType" SG_ 554 Motor_Out_Temp_Err 3;
BA_ "GenSigSendType" SG_ 554 Bat_Out_Temp_Err 3;
BA_ "GenSigSendType" SG_ 554 Motor_In_Temp_Err 3;
BA_ "GenSigSendType" SG_ 554 Bat_In_Temp_Err 3;
BA_ "GenSigSendType" SG_ 554 Tamb_Err 3;
BA_ "GenSigSendType" SG_ 593 P_UID_LowPower 3;
BA_ "GenSigInvalidValue" SG_ 593 P_CommandToPTG 5;
BA_ "GenSigSendType" SG_ 593 P_KeyMode 3;
BA_ "GenSigSendType" SG_ 593 DKC_Re_VehData 3;
BA_ "GenSigSendType" SG_ 594 EncryptionDATA_64_127 3;
BA_ "GenSigSendType" SG_ 594 EncryptionDATA_0_63 3;
BA_ "GenSigSendType" SG_ 594 Random_Number_X 3;
BA_ "GenSigSendType" SG_ 595 IVI_PTG_Open_Height 3;
BA_ "GenSigStartValue" SG_ 595 Approach_Unlock_SW 1;
BA_ "GenSigSendType" SG_ 595 Approach_Unlock_SW 3;
BA_ "GenSigStartValue" SG_ 595 Walkaway_Lock_SW 1;
BA_ "GenSigSendType" SG_ 595 Walkaway_Lock_SW 3;
BA_ "GenSigSendType" SG_ 595 BrkSw_Sta 3;
BA_ "GenSigSendType" SG_ 595 IVI_PTG_Mode_SW 3;
BA_ "GenSigSendType" SG_ 595 IVI_PTG_Sta_SW 3;
BA_ "GenSigInvalidValue" SG_ 595 IVI_ISA_OffsetSpd 15;
BA_ "GenSigSendType" SG_ 595 TurnSwTimeSet 3;
BA_ "GenSigSendType" SG_ 595 HeadLampSW 3;
BA_ "GenSigInvalidValue" SG_ 595 L_Drv_CtrlCmd 127;
BA_ "GenSigStartValue" SG_ 595 L_Drv_CtrlCmd 127;
BA_ "GenSigInactiveValue" SG_ 595 L_Drv_CtrlCmd 127;
BA_ "GenSigSendType" SG_ 595 L_Drv_CtrlCmd 3;
BA_ "GenSigInvalidValue" SG_ 595 L_Pas_CtrlCmd 127;
BA_ "GenSigStartValue" SG_ 595 L_Pas_CtrlCmd 127;
BA_ "GenSigInactiveValue" SG_ 595 L_Pas_CtrlCmd 127;
BA_ "GenSigSendType" SG_ 595 L_Pas_CtrlCmd 3;
BA_ "GenSigInvalidValue" SG_ 595 L_RLD_CtrlCmd 127;
BA_ "GenSigStartValue" SG_ 595 L_RLD_CtrlCmd 127;
BA_ "GenSigInactiveValue" SG_ 595 L_RLD_CtrlCmd 127;
BA_ "GenSigSendType" SG_ 595 L_RLD_CtrlCmd 3;
BA_ "GenSigInvalidValue" SG_ 595 L_RRD_CtrlCmd 127;
BA_ "GenSigStartValue" SG_ 595 L_RRD_CtrlCmd 127;
BA_ "GenSigInactiveValue" SG_ 595 L_RRD_CtrlCmd 127;
BA_ "GenSigSendType" SG_ 595 L_RRD_CtrlCmd 3;
BA_ "GenSigInvalidValue" SG_ 595 OFF_AC_MODE 7;
BA_ "GenSigRoutingTimeoutValue" SG_ 595 OFF_AC_MODE 7;
BA_ "GenSigSendType" SG_ 595 OFF_AC_MODE 3;
BA_ "GenSigInvalidValue" SG_ 595 BrkSw_V 1;
BA_ "GenSigRoutingTimeoutValue" SG_ 595 BrkSw_V 1;
BA_ "GenSigSendType" SG_ 595 BrkSw_V 3;
BA_ "GenSigInvalidValue" SG_ 595 MCPressure 4095;
BA_ "GenSigStartValue" SG_ 595 MCPressure 97;
BA_ "GenSigRoutingTimeoutValue" SG_ 595 MCPressure 4095;
BA_ "GenSigInvalidValue" SG_ 595 MCPressure_V 1;
BA_ "GenSigRoutingTimeoutValue" SG_ 595 MCPressure_V 1;
BA_ "GenSigSendType" SG_ 595 MCPressure_V 3;
BA_ "GenSigInvalidValue" SG_ 595 BrkPedalPos 255;
BA_ "GenSigRoutingTimeoutValue" SG_ 595 BrkPedalPos 255;
BA_ "GenSigSendType" SG_ 595 BrkPedalPos_Sta 3;
BA_ "GenSigSendType" SG_ 595 FDC_BCM_LockAlarm_Cmd 3;
BA_ "GenSigSendType" SG_ 595 FDC_THCM_ACTInitial_Cmd 3;
BA_ "GenSigSendType" SG_ 595 FDC_BCM_ATCtrl_Cmd 3;
BA_ "GenSigSendType" SG_ 595 FDC_BCM_OutMode_Cmd 3;
VAL_ 278 Dr_SeatSta 2 "Invalid" 1 "Seat occupied" 0 "Seat empty";
VAL_ 278 MSA_Crl_Sta 7 "Pedal Override" 6 "Invalid" 5 "Error" 4 "Over Speed" 3 "Under Speed" 2 "Active" 1 "Standby" 0 "Off";
VAL_ 278 CC_Crl_Sta 7 "Pedal Override" 6 "Invalid" 5 "Error" 4 "Over Speed" 3 "Under Speed" 2 "Active" 1 "Standby" 0 "Off";
VAL_ 278 ShiftGearPosn 7 "Reverse" 6 "Failure" 5 "Drive" 4 "Neutral" 3 "Not used" 2 "Not used" 1 "Not used" 0 "Park";
VAL_ 278 PwrSta 5 "READY" 4 "ON" 3 "STANDBY" 2 "OFF-After-Run" 1 "OFF-Charging" 0 "OFF";
VAL_ 278 ReBrakeLPReq 1 "On" 0 "Off";
VAL_ 278 EquivAccPedalSWSta 1 "On" 0 "Off";
VAL_ 278 HornCtrl 1 "ON" 0 "OFF";
VAL_ 278 BCM_DoorLock_Sta 1 "Lock" 0 "Unlock";
VAL_ 278 DimmerEN 1 "Enable" 0 "Disable";
VAL_ 278 RoomLampH 1 "ON" 0 "OFF";
VAL_ 278 RoomLampL 1 "ON" 0 "OFF";
VAL_ 278 TailgateRemote 3 "Invalid" 2 "Handle Request" 1 "Remote Request" 0 "No Request";
VAL_ 278 BCM_Buzzer_Req 1 "Request" 0 "No Request";
VAL_ 278 LockSetting 1 "Unlock Single Door" 0 "Unlock All Door";
VAL_ 278 L_APM_WdwEnable 1 "Normal" 0 "Inhibit";
VAL_ 278 CrashDetd 1 "Crash detected" 0 "Crash not detected";
VAL_ 278 AntiTheftSeatFold 1 "Fold" 0 "No Request";
VAL_ 278 AntitheftSta 3 "Alarm Status" 2 "Wait for Rearm Status" 1 "Arm Status" 0 "Disarm Status";
VAL_ 278 RTurnLP 1 "On" 0 "Off";
VAL_ 278 LTurnLP 1 "On" 0 "Off";
VAL_ 278 HazardSW 1 "On" 0 "Off";
VAL_ 278 Rr_FogLamp 1 "On" 0 "Off";
VAL_ 278 Fr_FogLamp 1 "On" 0 "Off";
VAL_ 278 RBSD 1 "On" 0 "Off";
VAL_ 278 LBSD 1 "On" 0 "Off";
VAL_ 278 BrakeLamp 1 "On" 0 "Off";
VAL_ 278 ReverseLamp 1 "On" 0 "Off";
VAL_ 278 RDRL 1 "On" 0 "Off";
VAL_ 278 LDRL 1 "On" 0 "Off";
VAL_ 278 PosLamp 1 "On" 0 "Off";
VAL_ 278 H_Beam 1 "On" 0 "Off";
VAL_ 278 L_Beam 1 "On" 0 "Off";
VAL_ 278 WasherCtrl 3 "Undefined" 2 "Rear Washer" 1 "Front Washer" 0 "No Command";
VAL_ 278 WiperFixMode 1 "On" 0 "Off";
VAL_ 278 Rr_Wiper 1 "On" 0 "Off";
VAL_ 278 Fr_Wiper_L 1 "On" 0 "Off";
VAL_ 278 Fr_Wiper_H 1 "On" 0 "Off";
VAL_ 278 MirrorCtrl 3 "Undefined" 2 "Unfold" 1 "Fold" 0 "No Command";
VAL_ 278 TailgateHDSW 1 "Press" 0 "Release";
VAL_ 278 TrunkRel 1 "Release" 0 "Off";
VAL_ 278 Rr_Defog 1 "On" 0 "Off";
VAL_ 278 MirrorDefog 1 "On" 0 "Off";
VAL_ 278 CTDUnlockSW 1 "Press" 0 "Release";
VAL_ 278 CTDLockSW 1 "Press" 0 "Release";
VAL_ 278 Rr_ChargingDoorCtrl 3 "Undefined" 2 "Lock" 1 "Unlock" 0 "No Command";
VAL_ 278 Fr_ChargingDoorCtrl 3 "Undefined" 2 "Lock" 1 "Unlock" 0 "No Command";
VAL_ 278 CTDCtrl 3 "Lock All Door" 2 "Unlock All Door" 1 "Unlock Driver Door" 0 "No Command";
VAL_ 278 Tailgate_SW 1 "Open" 0 "Close";
VAL_ 278 HoodSW 1 "Open" 0 "Close";
VAL_ 278 DoorLockIND 1 "On" 0 "Off";
VAL_ 278 AllDoorSW 1 "Any Door Open" 0 "Close";
VAL_ 278 RRDoorSW 1 "Open" 0 "Close";
VAL_ 278 RLDoorSW 1 "Open" 0 "Close";
VAL_ 278 PsDoorSW 1 "Open" 0 "Close";
VAL_ 278 DrDoorSW 1 "Open" 0 "Close";
VAL_ 278 FD_TBOX_VehData_Sta 2 "Upload" 1 "Pack" 0 "Idle";
VAL_ 278 FD_TBOX_VehData_Err 2 "Upload error" 1 "Pack error" 0 "No error";
VAL_ 278 FD_DKC_VehData_Sta 2 "Upload" 1 "Pack" 0 "Idle";
VAL_ 278 FD_DKC_VehData_Err 2 "Upload error" 1 "Pack error" 0 "No error";
VAL_ 278 FD_TBOX_DTCData_Sta 2 "Upload" 1 "Pack" 0 "Idle";
VAL_ 278 FD_TBOX_DTCData_Err 2 "Upload error" 1 "Pack error" 0 "No error";
VAL_ 278 AmbLightBreath3 1 "ON" 0 "OFF";
VAL_ 278 AmbLightBreath2 1 "ON" 0 "OFF";
VAL_ 278 LampPwr 1 "ON" 0 "OFF";
VAL_ 278 AmbLightBreath1 1 "ON" 0 "OFF";
VAL_ 278 DKCAuthSta 3 "invalid" 2 "Time S/N compare error" 1 "Decryption fail" 0 "Normal";
VAL_ 278 AmbLightColor3 63 "Red(255,0,0)" 62 "IndianRed(205,92,92)" 61 "LightCoral(240,128,128)" 60 "Tomato(255,99,71)" 59 "OrangeRed(255,69,0)" 58 "Coral(255,127,80)" 57 "LightSalmon(255,160,122)" 56 "DarkOrange(255,140,0)" 55 "Bisque(255,228,196)" 54 "NavajoWhite(255,222,173)" 53 "BlanchedAlmond(255,235,205)" 52 "Gold(255,215,0)" 51 "LemonChiffon(255,250,205)" 50 "Yellow(255,255,0)" 49 "LightYellow(255,255,224)" 48 "Ivory(255,255,240)" 47 "LightGoldenrodYellow(250,250,210)" 46 "Beige(245,245,220)" 45 "GreenYellow(173,255,47)" 44 "Chartreuse(127,255,0)" 43 "Lime(0,255,0)" 42 "LimeGreen(50,205,50)" 41 "PaleGreen(152,251,152)" 40 "LightGreen(144,238,144)" 39 "SeaGreen(46,139,87)" 38 "SpringGreen(60,179,113)" 37 "MediumSpringGreen(0,255,127)" 36 "MediumAquamarine(0,250,154)" 35 "Auqamarin(127,255,170)" 34 "MediumTurquoise(72,209,204)" 33 "DarkCyan(0,139,139)" 32 "DarkTurquoise(0,206,209)" 31 "Cyan(0,255,255)" 30 "PaleTurquoise(175,238,238)" 29 "DeepSkyBlue(0,191,255)" 28 "SkyBlue(135,206,235)" 27 "LightSkyBlue(135,206,250)" 26 "DoderBlue(30,144,255)" 25 "CornflowerBlue(100,149,237)" 24 "RoyalBlue(65,105,225)" 23 "Navy(0,0,128)" 22 "DarkBlue(0,0,139)" 21 "MidnightBlue(25,25,112)" 20 "MediumBlue(0,0,205)" 19 "Blue(0,0,255)" 18 "DarkSlateBlue(72,61,139)" 17 "SlateBlue(106,90,205)" 16 "MediumSlateBlue(123,104,238)" 15 "MediumPurple(147,112,219)" 14 "BlueViolet(138,43,226)" 13 "Indigo(75,0,130)" 12 "DarkOrchid(153,50,204)" 11 "DarkVoilet(148,0,211)" 10 "MediumOrchid(186,85,211)" 9 "DarkMagenta(139,0,139)" 8 "Magenta(255,0,255)" 7 "Violet(238,130,238)" 6 "Orchid(218,112,214)" 5 "MediumVioletRed(199,21,133)" 4 "DeepPink(255,20,147)" 3 "HotPink(255,105,180)" 2 "PaleVioletRed(219,112,147)" 1 "Crimson(220,20,60)" 0 "LightPink(255,182,193)";
VAL_ 278 AmbLightColor2 63 "Red(255,0,0)" 62 "IndianRed(205,92,92)" 61 "LightCoral(240,128,128)" 60 "Tomato(255,99,71)" 59 "OrangeRed(255,69,0)" 58 "Coral(255,127,80)" 57 "LightSalmon(255,160,122)" 56 "DarkOrange(255,140,0)" 55 "Bisque(255,228,196)" 54 "NavajoWhite(255,222,173)" 53 "BlanchedAlmond(255,235,205)" 52 "Gold(255,215,0)" 51 "LemonChiffon(255,250,205)" 50 "Yellow(255,255,0)" 49 "LightYellow(255,255,224)" 48 "Ivory(255,255,240)" 47 "LightGoldenrodYellow(250,250,210)" 46 "Beige(245,245,220)" 45 "GreenYellow(173,255,47)" 44 "Chartreuse(127,255,0)" 43 "Lime(0,255,0)" 42 "LimeGreen(50,205,50)" 41 "PaleGreen(152,251,152)" 40 "LightGreen(144,238,144)" 39 "SeaGreen(46,139,87)" 38 "SpringGreen(60,179,113)" 37 "MediumSpringGreen(0,255,127)" 36 "MediumAquamarine(0,250,154)" 35 "Auqamarin(127,255,170)" 34 "MediumTurquoise(72,209,204)" 33 "DarkCyan(0,139,139)" 32 "DarkTurquoise(0,206,209)" 31 "Cyan(0,255,255)" 30 "PaleTurquoise(175,238,238)" 29 "DeepSkyBlue(0,191,255)" 28 "SkyBlue(135,206,235)" 27 "LightSkyBlue(135,206,250)" 26 "DoderBlue(30,144,255)" 25 "CornflowerBlue(100,149,237)" 24 "RoyalBlue(65,105,225)" 23 "Navy(0,0,128)" 22 "DarkBlue(0,0,139)" 21 "MidnightBlue(25,25,112)" 20 "MediumBlue(0,0,205)" 19 "Blue(0,0,255)" 18 "DarkSlateBlue(72,61,139)" 17 "SlateBlue(106,90,205)" 16 "MediumSlateBlue(123,104,238)" 15 "MediumPurple(147,112,219)" 14 "BlueViolet(138,43,226)" 13 "Indigo(75,0,130)" 12 "DarkOrchid(153,50,204)" 11 "DarkVoilet(148,0,211)" 10 "MediumOrchid(186,85,211)" 9 "DarkMagenta(139,0,139)" 8 "Magenta(255,0,255)" 7 "Violet(238,130,238)" 6 "Orchid(218,112,214)" 5 "MediumVioletRed(199,21,133)" 4 "DeepPink(255,20,147)" 3 "HotPink(255,105,180)" 2 "PaleVioletRed(219,112,147)" 1 "Crimson(220,20,60)" 0 "LightPink(255,182,193)";
VAL_ 278 AmbLightColor1 63 "Red(255,0,0)" 62 "IndianRed(205,92,92)" 61 "LightCoral(240,128,128)" 60 "Tomato(255,99,71)" 59 "OrangeRed(255,69,0)" 58 "Coral(255,127,80)" 57 "LightSalmon(255,160,122)" 56 "DarkOrange(255,140,0)" 55 "Bisque(255,228,196)" 54 "NavajoWhite(255,222,173)" 53 "BlanchedAlmond(255,235,205)" 52 "Gold(255,215,0)" 51 "LemonChiffon(255,250,205)" 50 "Yellow(255,255,0)" 49 "LightYellow(255,255,224)" 48 "Ivory(255,255,240)" 47 "LightGoldenrodYellow(250,250,210)" 46 "Beige(245,245,220)" 45 "GreenYellow(173,255,47)" 44 "Chartreuse(127,255,0)" 43 "Lime(0,255,0)" 42 "LimeGreen(50,205,50)" 41 "PaleGreen(152,251,152)" 40 "LightGreen(144,238,144)" 39 "SeaGreen(46,139,87)" 38 "SpringGreen(60,179,113)" 37 "MediumSpringGreen(0,255,127)" 36 "MediumAquamarine(0,250,154)" 35 "Auqamarin(127,255,170)" 34 "MediumTurquoise(72,209,204)" 33 "DarkCyan(0,139,139)" 32 "DarkTurquoise(0,206,209)" 31 "Cyan(0,255,255)" 30 "PaleTurquoise(175,238,238)" 29 "DeepSkyBlue(0,191,255)" 28 "SkyBlue(135,206,235)" 27 "LightSkyBlue(135,206,250)" 26 "DoderBlue(30,144,255)" 25 "CornflowerBlue(100,149,237)" 24 "RoyalBlue(65,105,225)" 23 "Navy(0,0,128)" 22 "DarkBlue(0,0,139)" 21 "MidnightBlue(25,25,112)" 20 "MediumBlue(0,0,205)" 19 "Blue(0,0,255)" 18 "DarkSlateBlue(72,61,139)" 17 "SlateBlue(106,90,205)" 16 "MediumSlateBlue(123,104,238)" 15 "MediumPurple(147,112,219)" 14 "BlueViolet(138,43,226)" 13 "Indigo(75,0,130)" 12 "DarkOrchid(153,50,204)" 11 "DarkVoilet(148,0,211)" 10 "MediumOrchid(186,85,211)" 9 "DarkMagenta(139,0,139)" 8 "Magenta(255,0,255)" 7 "Violet(238,130,238)" 6 "Orchid(218,112,214)" 5 "MediumVioletRed(199,21,133)" 4 "DeepPink(255,20,147)" 3 "HotPink(255,105,180)" 2 "PaleVioletRed(219,112,147)" 1 "Crimson(220,20,60)" 0 "LightPink(255,182,193)";
VAL_ 278 AmbLightBrightness3 101 "~0x7F Valid" 100 "100%" 99 "99%" 98 "98%" 97 "97%" 96 "96%" 95 "95%" 94 "94%" 93 "93%" 92 "92%" 91 "91%" 90 "90%" 89 "89%" 88 "88%" 87 "87%" 86 "86%" 85 "85%" 84 "84%" 83 "83%" 82 "82%" 81 "81%" 80 "80%" 79 "79%" 78 "78%" 77 "77%" 76 "76%" 75 "75%" 74 "74%" 73 "73%" 72 "72%" 71 "71%" 70 "70%" 69 "69%" 68 "68%" 67 "67%" 66 "66%" 65 "65%" 64 "64%" 63 "63%" 62 "62%" 61 "61%" 60 "60%" 59 "59%" 58 "58%" 57 "57%" 56 "56%" 55 "55%" 54 "54%" 53 "53%" 52 "52%" 51 "51%" 50 "50%" 49 "49%" 48 "48%" 47 "47%" 46 "46%" 45 "45%" 44 "44%" 43 "43%" 42 "42%" 41 "41%" 40 "40%" 39 "39%" 38 "38%" 37 "37%" 36 "36%" 35 "35%" 34 "34%" 33 "33%" 32 "32%" 31 "31%" 30 "30%" 29 "29%" 28 "28%" 27 "27%" 26 "26%" 25 "25%" 24 "24%" 23 "23%" 22 "22%" 21 "21%" 20 "20%" 19 "19%" 18 "18%" 17 "17%" 16 "16%" 15 "15%" 14 "14%" 13 "13%" 12 "12%" 11 "11%" 10 "10%" 9 "9%" 8 "8%" 7 "7%" 6 "6%" 5 "5%" 4 "4%" 3 "3%" 2 "2%" 1 "1%" 0 "0%";
VAL_ 278 AmbLightBrightness2 101 "~0x7F Valid" 100 "100%" 99 "99%" 98 "98%" 97 "97%" 96 "96%" 95 "95%" 94 "94%" 93 "93%" 92 "92%" 91 "91%" 90 "90%" 89 "89%" 88 "88%" 87 "87%" 86 "86%" 85 "85%" 84 "84%" 83 "83%" 82 "82%" 81 "81%" 80 "80%" 79 "79%" 78 "78%" 77 "77%" 76 "76%" 75 "75%" 74 "74%" 73 "73%" 72 "72%" 71 "71%" 70 "70%" 69 "69%" 68 "68%" 67 "67%" 66 "66%" 65 "65%" 64 "64%" 63 "63%" 62 "62%" 61 "61%" 60 "60%" 59 "59%" 58 "58%" 57 "57%" 56 "56%" 55 "55%" 54 "54%" 53 "53%" 52 "52%" 51 "51%" 50 "50%" 49 "49%" 48 "48%" 47 "47%" 46 "46%" 45 "45%" 44 "44%" 43 "43%" 42 "42%" 41 "41%" 40 "40%" 39 "39%" 38 "38%" 37 "37%" 36 "36%" 35 "35%" 34 "34%" 33 "33%" 32 "32%" 31 "31%" 30 "30%" 29 "29%" 28 "28%" 27 "27%" 26 "26%" 25 "25%" 24 "24%" 23 "23%" 22 "22%" 21 "21%" 20 "20%" 19 "19%" 18 "18%" 17 "17%" 16 "16%" 15 "15%" 14 "14%" 13 "13%" 12 "12%" 11 "11%" 10 "10%" 9 "9%" 8 "8%" 7 "7%" 6 "6%" 5 "5%" 4 "4%" 3 "3%" 2 "2%" 1 "1%" 0 "0%";
VAL_ 278 AmbLightBrightness1 101 "~0x7F Invalid" 100 "100%" 99 "99%" 98 "98%" 97 "97%" 96 "96%" 95 "95%" 94 "94%" 93 "93%" 92 "92%" 91 "91%" 90 "90%" 89 "89%" 88 "88%" 87 "87%" 86 "86%" 85 "85%" 84 "84%" 83 "83%" 82 "82%" 81 "81%" 80 "80%" 79 "79%" 78 "78%" 77 "77%" 76 "76%" 75 "75%" 74 "74%" 73 "73%" 72 "72%" 71 "71%" 70 "70%" 69 "69%" 68 "68%" 67 "67%" 66 "66%" 65 "65%" 64 "64%" 63 "63%" 62 "62%" 61 "61%" 60 "60%" 59 "59%" 58 "58%" 57 "57%" 56 "56%" 55 "55%" 54 "54%" 53 "53%" 52 "52%" 51 "51%" 50 "50%" 49 "49%" 48 "48%" 47 "47%" 46 "46%" 45 "45%" 44 "44%" 43 "43%" 42 "42%" 41 "41%" 40 "40%" 39 "39%" 38 "38%" 37 "37%" 36 "36%" 35 "35%" 34 "34%" 33 "33%" 32 "32%" 31 "31%" 30 "30%" 29 "29%" 28 "28%" 27 "27%" 26 "26%" 25 "25%" 24 "24%" 23 "23%" 22 "22%" 21 "21%" 20 "20%" 19 "19%" 18 "18%" 17 "17%" 16 "16%" 15 "15%" 14 "14%" 13 "13%" 12 "12%" 11 "11%" 10 "10%" 9 "9%" 8 "8%" 7 "7%" 6 "6%" 5 "5%" 4 "4%" 3 "3%" 2 "2%" 1 "1%" 0 "0%";
VAL_ 278 HWResetSta 3 "Reserved" 2 "Hardware reset finish" 1 "Hardware resetting" 0 "No reset";
VAL_ 278 CtrlFrPwrStbA1P 1 "Request power off" 0 "No request";
VAL_ 278 CtrlFrIRC1 1 "Request power off" 0 "No request";
VAL_ 278 CtrlFrBMSCCUCIR 1 "Request power off" 0 "No request";
VAL_ 278 CtrlFrEDUINVERTER 1 "Request power off" 0 "No request";
VAL_ 278 CtrlDrPwrStbA2 1 "Request power off" 0 "No request";
VAL_ 374 ReChargerStaFromEvcc 3 "Invalid" 2 "Untrusted" 1 "On" 0 "Off";
VAL_ 378 V2LSta 3 "Invalid" 2 "SW on" 1 "V2L Adapter Plug-in" 0 "No plug";
VAL_ 378 HVBChrgErr 4 "EVFault" 3 "EVStop" 2 "EvseFAULT" 1 "SocMeetTarget" 0 "OK";
VAL_ 378 DisChrgPlugErr 2 "(un)lock request invalid" 1 "plug-in incomplete" 0 "Normal";
VAL_ 378 ChrgInLockReq 2 "Unlock" 1 "Lock" 0 "No action";
VAL_ 378 HVBCellUnbalanErr 1 "fault" 0 "No fault";
VAL_ 378 HVBCellUndrVoltErr 1 "fault" 0 "No fault";
VAL_ 378 HVBCellOvrVoltErr 1 "fault" 0 "No fault";
VAL_ 378 HVBCellUdrVoltWarn 2 "Warn2" 1 "Warn1" 0 "No fault";
VAL_ 378 HVBCellOvrVoltWarn 2 "Warn2" 1 "Warn1" 0 "No fault";
VAL_ 378 CellUnconsistErr 1 "fault" 0 "No fault";
VAL_ 378 SystemUncomErr 1 "fault" 0 "No fault";
VAL_ 378 IsoDetSta 1 "Fault detected" 0 "No fault detected";
VAL_ 378 HVBPreheatPrecoolSta 2 "Precool" 1 "Preheat" 0 "Default";
VAL_ 378 ExtChrgSta 3 "Fault" 2 "Charging Completed" 1 "Charging" 0 "No action";
VAL_ 378 ChrgPlugSta 3 "Plug-in dectected" 2 "DC Plug in" 1 "AC Plug in" 0 "No plug";
VAL_ 378 HVBattReady4Pre 2 "Fault" 1 "Ready" 0 "Not Ready";
VAL_ 378 HVILSta 1 "Opened" 0 "Closed";
VAL_ 378 HVBTempDiffErr 1 "fault" 0 "No fault";
VAL_ 378 HVBPrechrgSta 3 "precharge fail" 2 "precharge finished" 1 "precharge" 0 "not precharge";
VAL_ 378 HVBContactorSta 1 "Closed" 0 "Open";
VAL_ 378 BMS_READY 1 "Ready" 0 "Not ready";
VAL_ 378 DCChrgSysShockErr 1 "fault" 0 "No fault";
VAL_ 378 HVBHVILErr 1 "fault" 0 "No fault";
VAL_ 378 HVBSOCJumpError 1 "fault" 0 "No fault";
VAL_ 378 HVBUndrSOCErr 1 "fault" 0 "No fault";
VAL_ 378 HVBOvrSOCErr 1 "fault" 0 "No fault";
VAL_ 378 HVBUndrTempErr 1 "fault" 0 "No fault";
VAL_ 378 HVBOvrTempErr 1 "fault" 0 "No fault";
VAL_ 378 HVBOvrDchrgCurErr 1 "fault" 0 "No fault";
VAL_ 378 HVBOvrChrgCurrErr 1 "fault" 0 "No fault";
VAL_ 378 HVBShrtDischrgCurrErr 1 "fault" 0 "No fault";
VAL_ 378 HVBShrtChrgCurrErr 1 "fault" 0 "No fault";
VAL_ 378 HVBUndrVoltErr 1 "fault" 0 "No fault";
VAL_ 378 HVBOvrVoltErr 1 "fault" 0 "No fault";
VAL_ 378 HVBUndrTempWarn 2 "Warn2" 1 "Warn1" 0 "No fault";
VAL_ 378 HVBOvrTempWarn 2 "Warn2" 1 "Warn1" 0 "No fault";
VAL_ 378 BMS_Warn_8 1 "fault" 0 "No fault";
VAL_ 378 BMS_Warn_7 1 "fault" 0 "No fault";
VAL_ 378 BMS_Warn_6 1 "fault" 0 "No fault";
VAL_ 378 BMS_Warn_5 1 "fault" 0 "No fault";
VAL_ 378 BMS_Warn_4 1 "fault" 0 "No fault";
VAL_ 378 BMS_Warn_3 1 "fault" 0 "No fault";
VAL_ 378 BMS_Warn_2 1 "fault" 0 "No fault";
VAL_ 378 BMS_Warn_1 1 "fault" 0 "No fault";
VAL_ 380 ADAS_ShftPosnReq_A 1 "Applicable" 0 "Not Applicable";
VAL_ 380 ADAS_ShftPosnReq 7 "Reverse" 4 "Ds" 3 "D" 2 "Neutral" 1 "Park" 0 "No Request";
VAL_ 380 ADAS_ForceIdle 1 "Force Idle" 0 "No Force Idle";
VAL_ 386 CCU_HEATMaxLampSts 1 "Lamp ON" 0 "Lamp OFF";
VAL_ 386 CCU_ACLampSts 1 "Lamp ON" 0 "Lamp OFF";
VAL_ 386 CCU_EcoSts 1 "Lamp ON" 0 "Lamp OFF";
VAL_ 386 CCU_AutoMidLampSts 1 "Lamp ON" 0 "Lamp OFF";
VAL_ 386 CCU_AutoLampSts 1 "Lamp ON" 0 "Lamp OFF";
VAL_ 386 CCU_ACMaxLampSts 1 "Lamp ON" 0 "Lamp OFF";
VAL_ 386 CCU_RrOnOffLampSts 1 "Lamp ON" 0 "Lamp OFF";
VAL_ 386 sigWindDirZon1St 7 "NOT Set / Reserved" 6 "All open" 5 "Face + Screen" 4 "DEFOG" 3 "Foot + Screen" 2 "Foot" 1 "Bilevel" 0 "FACE";
VAL_ 386 CCU_FrtOnOffLampSts 1 "Lamp ON" 0 "Lamp OFF";
VAL_ 386 sigWindDirZon3St 7 "NOT Set / Reserved" 6 "All open" 5 "Face + Screen" 4 "DEFOG" 3 "Foot + Screen" 2 "Foot" 1 "Bilevel" 0 "FACE";
VAL_ 386 sigAirIntenZon1St 15 "Invalid" 14 "Reserved" 11 "Reserved" 10 "NOT set" 9 "Level 8" 8 "Level 7" 7 "Level 6" 6 "Level 5" 5 "Level 4" 4 "Level 3" 3 "Level 2" 2 "Level 1" 1 "OFF" 0 "NO display / No request";
VAL_ 386 sigAirIntenZon3St 15 "Invalid" 14 "Reserved" 11 "Reserved" 10 "NOT set" 9 "Level 8" 8 "Level 7" 7 "Level 6" 6 "Level 5" 5 "Level 4" 4 "Level 3" 3 "Level 2" 2 "Level 1" 1 "OFF" 0 "NO display / No request";
VAL_ 386 CCU_SyncLampSts 1 "Lamp ON" 0 "Lamp OFF";
VAL_ 386 sigDfrstSt 1 "ON" 0 "OFF";
VAL_ 386 sigRecircSt 1 "ON" 0 "OFF";
VAL_ 386 sigHvacSt 1 "ON" 0 "OFF";
VAL_ 386 HPThermalRecoveryReq 1 "Request" 0 "Not Request";
VAL_ 386 EDriveMode 2 "Waste Heat Recovery" 1 "Cooling" 0 "OFF";
VAL_ 386 FD_RecyAuto_Cmd 6 "reserved" 5 "reserved" 4 "100% out recycle" 3 "70% out recycle" 2 "50% out recycle" 1 "30% out recycle" 0 "0% out recycle";
VAL_ 386 BatteryMode 5 "Active Heating" 4 "Passive Heating" 3 "Isothermal Cycle" 2 "Passive Cooling" 1 "Active Cooling" 0 "OFF";
VAL_ 386 CabinMode 9 "Cabin Heating Mode 2" 8 "Cabin Heating Mode 1" 7 "Cabin Dehumidity Mode 4" 6 "Cabin Dehumidity Mode 3" 5 "Cabin Dehumidity Mode 2" 4 "Cabin Dehumidity Mode 1" 3 "Mode 1" 2 "Comp On" 1 "Comp Off" 0 "OFF";
VAL_ 386 FD_AGS_Cmd 208 "78^Deg" 240 "90^Deg" 176 "66^Deg" 144 "54^Deg" 112 "42^Deg" 80 "30^Deg" 48 "18^Deg" 16 "6^Deg" 224 "84^Deg" 192 "72^Deg" 160 "60^Deg" 128 "48^Deg" 96 "36^Deg" 64 "24^Deg" 32 "12^Deg" 0 "0^Deg";
VAL_ 390 FD_SOV3_Cmd 1 "Close" 0 "Open";
VAL_ 390 FD_SOV2_Cmd 1 "Close" 0 "Open";
VAL_ 390 FD_SOV1_Cmd 1 "Close" 0 "Open";
VAL_ 390 FD_SOTXV_Cmd 1 "Close" 0 "Open";
VAL_ 390 ACSubMode 7 "mode 7" 6 "mode 6" 5 "Mode 5" 4 "Mode 4" 3 "Mode 3" 2 "Mode 2" 1 "Mode 1" 0 "OFF";
VAL_ 390 FD_FWV_Cmd 1 "Open Port 1 to Port 4, Port 2 to port 3" 0 "Open Port 1 to Port 2, Port 3 to port 4";
VAL_ 390 CCU_HiVoltageReq 1 "High Voltage Request" 0 "High Voltage not Request";
VAL_ 390 CCU_CbnPreSts 3 "Reserved" 2 "Calculate Estimated Time Status" 1 "ON" 0 "OFF";
VAL_ 390 DeiceModReq 1 "Request" 0 "Not Request";
VAL_ 390 CCU_CbnPreACWkSts 3 "Fail" 2 "Success" 1 "Init" 0 "No Request";
VAL_ 390 CCU_CbnPreEstimdTi 63 "Invalid" 62 "Reserved" 61 "Reserved" 60 "Normal" 0 "Normal";
VAL_ 390 FD_FrRiAPTCHeatPwr_Cmd 255 "Invalid" 201 "~0xFE Reserved" 0 "~ 0xC8 actual value";
VAL_ 390 FD_FrLeAPTCHeatPwr_Cmd 255 "Invalid" 201 "~0xFE Reserved" 0 "~ 0xC8 actual value";
VAL_ 390 FD_RrAPTCHeatPwr_Cmd 255 "Invalid" 201 "~ 0xFE Reserved" 0 "~0xC8 actual value";
VAL_ 390 FD_EWP3_Cmd 255 "Invalid" 250 "Maxmum Speed" 50 "Minmum Speed" 0 "Stop";
VAL_ 390 FD_EWP2_Cmd 255 "Invalid" 250 "Maxmum Speed" 50 "Minmum Speed" 0 "Stop";
VAL_ 390 FD_EWP1_Cmd 255 "Invalid" 250 "Maxmum Speed" 50 "Minmum Speed" 0 "Stop";
VAL_ 497 DrPMMSysErrLmp 1 "Error" 0 "Normal";
VAL_ 497 DrPMMLVOutPErrLmp 1 "Error" 0 "Normal";
VAL_ 497 DrPMMLimpHomeActReq 1 "Error" 0 "Normal";
VAL_ 497 DrIVIFault 2 "Check fail" 1 "Check OK" 0 "No check";
VAL_ 497 DrEOBDFault 2 "Check fail" 1 "Check OK" 0 "No check";
VAL_ 497 DrInfoFault 2 "Check fail" 1 "Check OK" 0 "No check";
VAL_ 497 DrPwrWindowECUFault 2 "Check fail" 1 "Check OK" 0 "No check";
VAL_ 497 DrTHCMFault 2 "Check fail" 1 "Check OK" 0 "No check";
VAL_ 497 DrColumnSWFault 2 "Check fail" 1 "Check OK" 0 "No check";
VAL_ 497 DrPwrSta 5 "READY" 4 "ON" 3 "STANDBY" 2 "OFF-After-Run" 1 "OFF-Charging" 0 "OFF";
VAL_ 497 DrPwrInformationSta 1 "ON" 0 "OFF";
VAL_ 497 DrAPWStaErr 1 "Error" 0 "Normal";
VAL_ 497 DrAPWLINErr 1 "Error" 0 "Normal";
VAL_ 497 DrONA1ErrSta 1 "Error" 0 "Normal";
VAL_ 497 DrStdAErrSta 1 "Error" 0 "Normal";
VAL_ 497 DrPwrWinErrSta 1 "Error" 0 "Normal";
VAL_ 497 DrInfoErrSta 1 "Error" 0 "Normal";
VAL_ 497 ZoneDrMalfunLevel 5 "Invalid" 4 "4th grade malfunction" 3 "3rd grade malfunction" 2 "2nd grade malfunction" 1 "1st grade malfunction" 0 "Normal";
VAL_ 497 ZDR_SYS_BSWSleepReq_Sta 1 "Request" 0 "No Request";
VAL_ 497 ZDR_VCU_HWReset_Sta 25 "EBM power off" 24 "ECompressor power off" 23 "WPTC power off" 22 "HMI power off" 21 "TBox power off" 20 "IVI power off" 19 "AirPTC power off" 18 "PSEAT power off" 17 "DSEAT power off" 16 "ABM power off" 15 "EPS power off" 14 "BMS power off" 13 "EOP_F power off" 12 "EOP_R power off" 11 "CCU power off" 10 "DKC power off" 9 "MRR power off" 8 "SRR_M power off" 7 "FCM power off" 6 "MCU_F power off" 5 "MCU_R power off" 4 "Shifter power off" 3 "Telltale power off" 2 "EBST power off" 1 "ESC power off" 0 "No request";
VAL_ 497 ZDR_VCU_PwrSupply_Sta 1 "Power supply off" 0 "No action";
VAL_ 498 FrPwrStdbyA1PlusFault 7 "Reserved" 6 "Reserved" 5 "Reserved" 4 "Reserved" 3 "Reserved" 2 "Reserved" 1 "Fault" 0 "Normal";
VAL_ 498 FrPwrStdbyA2PlusFault 7 "Reserved" 6 "Reserved" 5 "Reserved" 4 "Reserved" 3 "Reserved" 2 "Reserved" 1 "Fault" 0 "Normal";
VAL_ 498 FrPwrONA1Fault 2 "Check fail" 1 "Check OK" 0 "No check";
VAL_ 498 FrBMS_CCU_CIRFault 7 "Reserved" 6 "Reserved" 5 "Reserved" 4 "Reserved" 3 "Reserved" 2 "Reserved" 1 "Fault" 0 "Normal";
VAL_ 498 FrEDU_INVERTERFault 7 "Reserved" 6 "Reserved" 5 "Reserved" 4 "Reserved" 3 "Reserved" 2 "Reserved" 1 "Fault" 0 "Normal";
VAL_ 498 FrPwrStdbyA1Fault 2 "Check fail" 1 "Check OK" 0 "No check";
VAL_ 498 FrPMMSysErrLmp 1 "Error" 0 "Normal";
VAL_ 498 FrPMMLVOutPErrLmp 1 "Error" 0 "Normal";
VAL_ 498 FrPMMLimpHomeActReq 1 "Error" 0 "Normal";
VAL_ 498 ZoneFrMalfunLevel 5 "Invalid" 4 "4th grade malfunction" 3 "3rd grade malfunction" 2 "2nd grade malfunction" 1 "1st grade malfunction" 0 "Normal";
VAL_ 498 ZFR_SYS_BSWSleepReq_Sta 1 "Request" 0 "No Request";
VAL_ 498 FrStdA1PCErr 1 "Error" 0 "Normal";
VAL_ 498 FrStdA2PCErr 1 "Error" 0 "Normal";
VAL_ 498 FrStdA2PErr 1 "Error" 0 "Normal";
VAL_ 498 FrBMSCCUCErr 1 "Error" 0 "Normal";
VAL_ 498 FrEDUErr 1 "Error" 0 "Normal";
VAL_ 498 FrPwrSta 5 "READY" 4 "ON" 3 "STANDBY" 2 "OFF-After-Run" 1 "OFF-Charging" 0 "OFF";
VAL_ 498 ZFR_VCU_HWReset_Sta 25 "EBM power off" 24 "ECompressor power off" 23 "WPTC power off" 22 "HMI power off" 21 "TBox power off" 20 "IVI power off" 19 "AirPTC power off" 18 "PSEAT power off" 17 "DSEAT power off" 16 "ABM power off" 15 "EPS power off" 14 "BMS power off" 13 "EOP_F power off" 12 "EOP_R power off" 11 "CCU power off" 10 "DKC power off" 9 "MRR power off" 8 "SRR_M power off" 7 "FCM power off" 6 "MCU_F power off" 5 "MCU_R power off" 4 "Shifter power off" 3 "Telltale power off" 2 "EBST power off" 1 "ESC power off" 0 "No request";
VAL_ 498 ZFR_VCU_PwrSupply_Sta 1 "Power supply off" 0 "No action";
VAL_ 547 FrntPTCSts 1 "ON" 0 "OFF";
VAL_ 547 FrntPTCFltSt 3 "Degraded Failure" 2 "Permanent Failure" 1 "Temporary Failure" 0 "Normal";
VAL_ 547 FrntPTCLVUnderUFlt 1 "Failure" 0 "Normal";
VAL_ 547 FrntPTCLVOverUFlt 1 "Failure" 0 "Normal";
VAL_ 547 FrntPTCHVUnderUFlt 1 "Failure" 0 "Normal";
VAL_ 547 FrntPTCHVOverUFlt 1 "Failure" 0 "Normal";
VAL_ 547 FrntPTCLeOverAFlt 1 "Failure" 0 "Normal";
VAL_ 547 FrntPTCRiOverAFlt 1 "Failure" 0 "Normal";
VAL_ 547 FrntPTCLeCoreTSnsrFlt 1 "Failure" 0 "Normal";
VAL_ 547 FrntPTCRiCoreTSnsrFlt 1 "Failure" 0 "Normal";
VAL_ 547 FrntPTCLeCoreOverTFlt 1 "Failure" 0 "Normal";
VAL_ 547 FrntPTCRiCoreOverTFlt 1 "Failure" 0 "Normal";
VAL_ 547 FrntPTCLeIGBTShoCircFlt 1 "Failure" 0 "Normal";
VAL_ 547 FrntPTCRiIGBTShoCircFlt 1 "Failure" 0 "Normal";
VAL_ 547 FrntPTCLeOpentCircFlt 1 "Failure" 0 "Normal";
VAL_ 547 FrntPTCRiOpentCircFlt 1 "Failure" 0 "Normal";
VAL_ 547 FrntPTCPCBTSnsrFlt 1 "Failure" 0 "Normal";
VAL_ 547 FrntPTCPCBOverTFlt 1 "Failure" 0 "Normal";
VAL_ 547 FrntPTCComFlt 1 "Failure" 0 "Normal";
VAL_ 547 FrntPTCLeIGBTTSnsrFlt 1 "Failure" 0 "Normal";
VAL_ 547 FrntPTCRiIGBTTSnsrFlt 1 "Failure" 0 "Normal";
VAL_ 547 FrntPTCLeIGBTOverTFlt 1 "Failure" 0 "Normal";
VAL_ 547 FrntPTCRiIGBTOverTFlt 1 "Failure" 0 "Normal";
VAL_ 547 FrntPTCRearLeOverAFlt 1 "Failure" 0 "Normal";
VAL_ 547 FrntPTCRearLeOpentCircFlt 1 "Failure" 0 "Normal";
VAL_ 547 FrntPTCRearRiCoreOverTFlt 1 "Failure" 0 "Normal";
VAL_ 547 FrntPTCRearLeCoreOverTFlt 1 "Failure" 0 "Normal";
VAL_ 547 FrntPTCRearRiCoreTSnsrFlt 1 "Failure" 0 "Normal";
VAL_ 547 FrntPTCRearLeCoreTSnsrFlt 1 "Failure" 0 "Normal";
VAL_ 547 FrntPTCRearRiOverAFlt 1 "Failure" 0 "Normal";
VAL_ 547 FrntPTCRearRiOpentCircFlt 1 "Failure" 0 "Normal";
VAL_ 547 FrntPTCRearRiIGBTShoCFlt 1 "Failure" 0 "Normal";
VAL_ 547 FrntPTCRearLeIGBTShoCFlt 1 "Failure" 0 "Normal";
VAL_ 547 FrntPTCLeCoreT 255 "Invalid";
VAL_ 547 FrntPTCRiCoreT 255 "Invalid";
VAL_ 547 FrntPTCLeActHeatPwr 255 "Invalid" 201 "~ 0xFE Invalid";
VAL_ 547 FrntPTCRiActHeatPwr 255 "Invalid" 201 "~ 0xFE Invalid";
VAL_ 547 FrntPTCLeIGBTT 255 "Invalid";
VAL_ 547 FrntPTCRiIGBTT 255 "Invalid";
VAL_ 547 FrntPTCPCBT 255 "Invalid";
VAL_ 547 FrntPTCLeBusLineC 255 "Invalid";
VAL_ 547 FrntPTCRiBusLineC 255 "Invalid";
VAL_ 547 FrntPTCBusLineHiV 1001 "~0x3FF   Invalid";
VAL_ 549 APTC_Err 2 "reserved" 1 "fault" 0 "normal";
VAL_ 549 Blower_Err 2 "reserved" 1 "fault" 0 "normal";
VAL_ 549 T_Foot_Rr_Err 2 "reserved" 1 "fault" 0 "normal";
VAL_ 549 T_Face_Rr_Err 2 "reserved" 1 "fault" 0 "normal";
VAL_ 549 T_Foot_R_Err 2 "reserved" 1 "fault" 0 "normal";
VAL_ 549 T_Face_R_Err 2 "reserved" 1 "fault" 0 "normal";
VAL_ 549 T_Foot_L_Err 2 "reserved" 1 "fault" 0 "normal";
VAL_ 549 T_Face_L_Err 2 "reserved" 1 "fault" 0 "normal";
VAL_ 549 Tincar_Err 2 "reserved" 1 "fault" 0 "normal";
VAL_ 549 Tevap_Err 2 "reserved" 1 "fault" 0 "normal";
VAL_ 549 SolarR_Err 2 "reserved" 1 "fault" 0 "normal";
VAL_ 549 SolarL_Err 2 "reserved" 1 "fault" 0 "normal";
VAL_ 549 ZDR_THCM_IntakeFail_Sta 2 "NG" 1 "OK" 0 "Checking";
VAL_ 549 ZDR_THCM_ModeFail_Sta 2 "NG" 1 "OK" 0 "Checking";
VAL_ 549 ZDR_THCM_LINACT1_Sta 2 "NG" 1 "OK" 0 "Checking";
VAL_ 549 ZDR_THCM_LINACT2_Sta 2 "NG" 1 "OK" 0 "Checking";
VAL_ 549 ZDR_THCM_LINACT3_Sta 2 "NG" 1 "OK" 0 "Checking";
VAL_ 549 ZDR_THCM_LINACT4_Sta 2 "NG" 1 "OK" 0 "Checking";
VAL_ 549 ZDR_THCM_LINACT5_Sta 2 "NG" 1 "OK" 0 "Checking";
VAL_ 550 RLS_LIN_Resp_Err 1 "Error" 0 "Normal";
VAL_ 550 RLS_LightSnrErr 1 "LS error" 0 "LS no error";
VAL_ 550 RLS_RainSnrErr 1 "RS error" 0 "RS no error";
VAL_ 550 WiperZeroPosSW 1 "Wiper is not in zero position" 0 "Wiper is in zero position";
VAL_ 550 AutoLightSW 1 "EnableAutolamps" 0 "DisableAutolamps";
VAL_ 550 CSW_resp_error 1 "Error" 0 "Normal";
VAL_ 550 WiperSWPos 8 "wash mode" 4 "wiper in HS mode(manual)" 2 "wiper in LS mode(manual)" 1 "wiper in Auto mode" 16 "mist mode" 0 "wiper off";
VAL_ 550 RLS_Lamp_Sta 1 "Lamps ON" 0 "Lamps OFF";
VAL_ 550 RLS_RainSnrWiperCmd 7 "Failure" 3 "High Speed" 2 "Low Speed" 0 "Off";
VAL_ 550 CSW_FWipSw_Sta 7 "invalid" 3 "High" 2 "Low" 1 "Auto" 0 "OFF";
VAL_ 550 HornSW 1 "Press" 0 "Release";
VAL_ 550 CSW_TurnSw_Sta 3 "invalid" 2 "Right" 1 "Left" 0 "OFF";
VAL_ 550 CSW_RWasSW_Sta 3 "invalid" 1 "Press" 0 "Release";
VAL_ 550 CSW_FWasSw_Sta 3 "invalid" 2 "Mist" 1 "ON" 0 "OFF";
VAL_ 550 RLS_Exist 1 "Exist" 0 "Not Exist";
VAL_ 550 CSW_PassSW_Sta 1 "Press" 0 "Release";
VAL_ 550 BrakeLampFail 1 "Fail" 0 "Normal";
VAL_ 550 CSW_DimSw 1 "On" 0 "Off";
VAL_ 550 CSW_RWipIntSw_Sta 3 "Invalid" 2 "Low" 1 "int" 0 "off";
VAL_ 550 Wip_Speed 3 "High speed" 2 "Low speed" 1 "Intermittent" 0 "OFF";
VAL_ 550 RWiperProtection 1 "In protection" 0 "Not in Protectio";
VAL_ 550 RWiperAS 1 "Not at Stop Position" 0 "Stop Position";
VAL_ 550 MIRROR_FOLD_SW 1 "Press" 0 "Release";
VAL_ 550 AllLockSta 1 "Lock" 0 "Unlcok";
VAL_ 550 RRLockSta 1 "Lock" 0 "Unlcok";
VAL_ 550 RLLockSta 1 "Lock" 0 "Unlcok";
VAL_ 550 PsLockSta 1 "Lock" 0 "Unlcok";
VAL_ 550 DrLockSta 1 "Lock" 0 "Unlcok";
VAL_ 552 AGS_Actual_Position 240 "90^Deg" 208 "78^Deg" 176 "66^Deg" 144 "54^Deg" 112 "42^Deg" 80 "30^Deg" 48 "18^Deg" 16 "6^Deg" 224 "84^Deg" 192 "72^Deg" 160 "60^Deg" 128 "48^Deg" 96 "36^Deg" 64 "24^Deg" 32 "12^Deg" 0 "0^Deg";
VAL_ 552 AGS_Low_Voltage_Error 1 "ERROR" 0 "NO_Voltage_ERROR";
VAL_ 552 AGS_Temperature_Error 1 "ERROR" 0 "NO_ERROR";
VAL_ 552 AGS_Sensor_Error 1 "ERROR" 0 "NO_ERROR";
VAL_ 552 AGS_Electrical_Error 1 "ERROR" 0 "NO_ERROR";
VAL_ 552 AGS_Calibration_Indicated 1 "CALIBRATION_REQ" 0 "NO_CALIBRATION";
VAL_ 552 AGS_Calibration_Active 1 "Caliberation_Process_active" 0 "Caliberation_process_inactive";
VAL_ 552 AGS_Actuator_Fault 1 "ERROR" 0 "NO_ERROR";
VAL_ 552 AGS_Actuator_Blocked 1 "ERROR" 0 "NO_ERROR";
VAL_ 552 AGS_LINResponse_Error 1 "ERROR" 0 "NO_ERROR";
VAL_ 552 AGS_Calibration_Enabled 1 "CALIB_ENABLE" 0 "NO_CALIB";
VAL_ 552 AGS_Position_Request 208 "78¢X" 240 "90¢X" 176 "66¢X" 144 "54¢X" 112 "42¢X" 80 "30¢X" 48 "18¢X" 16 "6¢X" 224 "84¢X" 192 "72¢X" 160 "60¢X" 128 "48¢X" 96 "36¢X" 64 "24¢X" 32 "12¢X" 0 "0¢X";
VAL_ 552 ChargeInletLockSta 1 "Lock" 0 "Unlock";
VAL_ 552 FWiperProtection 1 "In protection" 0 "Not in Protectio";
VAL_ 552 FWiperAS 1 "Not at Stop Position" 0 "Stop Position";
VAL_ 552 EWP2_RPM_Target_EWP_Rq 255 "Invalid" 254 "max speed rpm" 253 "max speed rpm" 252 "max speed rpm" 251 "max speed rpm" 250 "linearly changed from min speed to max speed" 249 "linearly changed from min speed to max speed" 248 "linearly changed from min speed to max speed" 247 "linearly changed from min speed to max speed" 246 "linearly changed from min speed to max speed" 245 "linearly changed from min speed to max speed" 244 "linearly changed from min speed to max speed" 243 "linearly changed from min speed to max speed" 242 "linearly changed from min speed to max speed" 241 "linearly changed from min speed to max speed" 240 "linearly changed from min speed to max speed" 239 "linearly changed from min speed to max speed" 238 "linearly changed from min speed to max speed" 237 "linearly changed from min speed to max speed" 236 "linearly changed from min speed to max speed" 235 "linearly changed from min speed to max speed" 234 "linearly changed from min speed to max speed" 233 "linearly changed from min speed to max speed" 232 "linearly changed from min speed to max speed" 231 "linearly changed from min speed to max speed" 230 "linearly changed from min speed to max speed" 229 "linearly changed from min speed to max speed" 228 "linearly changed from min speed to max speed" 227 "linearly changed from min speed to max speed" 226 "linearly changed from min speed to max speed" 225 "linearly changed from min speed to max speed" 224 "linearly changed from min speed to max speed" 223 "linearly changed from min speed to max speed" 222 "linearly changed from min speed to max speed" 221 "linearly changed from min speed to max speed" 220 "linearly changed from min speed to max speed" 219 "linearly changed from min speed to max speed" 218 "linearly changed from min speed to max speed" 217 "linearly changed from min speed to max speed" 216 "linearly changed from min speed to max speed" 215 "linearly changed from min speed to max speed" 214 "linearly changed from min speed to max speed" 213 "linearly changed from min speed to max speed" 212 "linearly changed from min speed to max speed" 211 "linearly changed from min speed to max speed" 210 "linearly changed from min speed to max speed" 209 "linearly changed from min speed to max speed" 208 "linearly changed from min speed to max speed" 207 "linearly changed from min speed to max speed" 206 "linearly changed from min speed to max speed" 205 "linearly changed from min speed to max speed" 204 "linearly changed from min speed to max speed" 203 "linearly changed from min speed to max speed" 202 "linearly changed from min speed to max speed" 201 "linearly changed from min speed to max speed" 200 "linearly changed from min speed to max speed" 199 "linearly changed from min speed to max speed" 198 "linearly changed from min speed to max speed" 197 "linearly changed from min speed to max speed" 196 "linearly changed from min speed to max speed" 195 "linearly changed from min speed to max speed" 194 "linearly changed from min speed to max speed" 193 "linearly changed from min speed to max speed" 192 "linearly changed from min speed to max speed" 191 "linearly changed from min speed to max speed" 190 "linearly changed from min speed to max speed" 189 "linearly changed from min speed to max speed" 188 "linearly changed from min speed to max speed" 187 "linearly changed from min speed to max speed" 186 "linearly changed from min speed to max speed" 185 "linearly changed from min speed to max speed" 184 "linearly changed from min speed to max speed" 183 "linearly changed from min speed to max speed" 182 "linearly changed from min speed to max speed" 181 "linearly changed from min speed to max speed" 180 "linearly changed from min speed to max speed" 179 "linearly changed from min speed to max speed" 178 "linearly changed from min speed to max speed" 177 "linearly changed from min speed to max speed" 176 "linearly changed from min speed to max speed" 175 "linearly changed from min speed to max speed" 174 "linearly changed from min speed to max speed" 173 "linearly changed from min speed to max speed" 172 "linearly changed from min speed to max speed" 171 "linearly changed from min speed to max speed" 170 "linearly changed from min speed to max speed" 169 "linearly changed from min speed to max speed" 168 "linearly changed from min speed to max speed" 167 "linearly changed from min speed to max speed" 166 "linearly changed from min speed to max speed" 165 "linearly changed from min speed to max speed" 164 "linearly changed from min speed to max speed" 163 "linearly changed from min speed to max speed" 162 "linearly changed from min speed to max speed" 161 "linearly changed from min speed to max speed" 160 "linearly changed from min speed to max speed" 159 "linearly changed from min speed to max speed" 158 "linearly changed from min speed to max speed" 157 "linearly changed from min speed to max speed" 156 "linearly changed from min speed to max speed" 155 "linearly changed from min speed to max speed" 154 "linearly changed from min speed to max speed" 153 "linearly changed from min speed to max speed" 152 "linearly changed from min speed to max speed" 151 "linearly changed from min speed to max speed" 150 "linearly changed from min speed to max speed" 149 "linearly changed from min speed to max speed" 148 "linearly changed from min speed to max speed" 147 "linearly changed from min speed to max speed" 146 "linearly changed from min speed to max speed" 145 "linearly changed from min speed to max speed" 144 "linearly changed from min speed to max speed" 143 "linearly changed from min speed to max speed" 142 "linearly changed from min speed to max speed" 141 "linearly changed from min speed to max speed" 140 "linearly changed from min speed to max speed" 139 "linearly changed from min speed to max speed" 138 "linearly changed from min speed to max speed" 137 "linearly changed from min speed to max speed" 136 "linearly changed from min speed to max speed" 135 "linearly changed from min speed to max speed" 134 "linearly changed from min speed to max speed" 133 "linearly changed from min speed to max speed" 132 "linearly changed from min speed to max speed" 131 "linearly changed from min speed to max speed" 130 "linearly changed from min speed to max speed" 129 "linearly changed from min speed to max speed" 128 "linearly changed from min speed to max speed" 127 "linearly changed from min speed to max speed" 126 "linearly changed from min speed to max speed" 125 "linearly changed from min speed to max speed" 124 "linearly changed from min speed to max speed" 123 "linearly changed from min speed to max speed" 122 "linearly changed from min speed to max speed" 121 "linearly changed from min speed to max speed" 120 "linearly changed from min speed to max speed" 119 "linearly changed from min speed to max speed" 118 "linearly changed from min speed to max speed" 117 "linearly changed from min speed to max speed" 116 "linearly changed from min speed to max speed" 115 "linearly changed from min speed to max speed" 114 "linearly changed from min speed to max speed" 113 "linearly changed from min speed to max speed" 112 "linearly changed from min speed to max speed" 111 "linearly changed from min speed to max speed" 110 "linearly changed from min speed to max speed" 109 "linearly changed from min speed to max speed" 108 "linearly changed from min speed to max speed" 107 "linearly changed from min speed to max speed" 106 "linearly changed from min speed to max speed" 105 "linearly changed from min speed to max speed" 104 "linearly changed from min speed to max speed" 103 "linearly changed from min speed to max speed" 102 "linearly changed from min speed to max speed" 101 "linearly changed from min speed to max speed" 100 "linearly changed from min speed to max speed" 99 "linearly changed from min speed to max speed" 98 "linearly changed from min speed to max speed" 97 "linearly changed from min speed to max speed" 96 "linearly changed from min speed to max speed" 95 "linearly changed from min speed to max speed" 94 "linearly changed from min speed to max speed" 93 "linearly changed from min speed to max speed" 92 "linearly changed from min speed to max speed" 91 "linearly changed from min speed to max speed" 90 "linearly changed from min speed to max speed" 89 "linearly changed from min speed to max speed" 88 "linearly changed from min speed to max speed" 87 "linearly changed from min speed to max speed" 86 "linearly changed from min speed to max speed" 85 "linearly changed from min speed to max speed" 84 "linearly changed from min speed to max speed" 83 "linearly changed from min speed to max speed" 82 "linearly changed from min speed to max speed" 81 "linearly changed from min speed to max speed" 80 "linearly changed from min speed to max speed" 79 "linearly changed from min speed to max speed" 78 "linearly changed from min speed to max speed" 77 "linearly changed from min speed to max speed" 76 "linearly changed from min speed to max speed" 75 "linearly changed from min speed to max speed" 74 "linearly changed from min speed to max speed" 73 "linearly changed from min speed to max speed" 72 "linearly changed from min speed to max speed" 71 "linearly changed from min speed to max speed" 70 "linearly changed from min speed to max speed" 69 "linearly changed from min speed to max speed" 68 "linearly changed from min speed to max speed" 67 "linearly changed from min speed to max speed" 66 "linearly changed from min speed to max speed" 65 "linearly changed from min speed to max speed" 64 "linearly changed from min speed to max speed" 63 "linearly changed from min speed to max speed" 62 "linearly changed from min speed to max speed" 61 "linearly changed from min speed to max speed" 60 "linearly changed from min speed to max speed" 59 "linearly changed from min speed to max speed" 58 "linearly changed from min speed to max speed" 57 "linearly changed from min speed to max speed" 56 "linearly changed from min speed to max speed" 55 "linearly changed from min speed to max speed" 54 "linearly changed from min speed to max speed" 53 "linearly changed from min speed to max speed" 52 "linearly changed from min speed to max speed" 51 "linearly changed from min speed to max speed" 50 "linearly changed from min speed to max speed" 49 "min speed rpm" 48 "min speed rpm" 47 "min speed rpm" 46 "min speed rpm" 45 "min speed rpm" 44 "min speed rpm" 43 "min speed rpm" 42 "min speed rpm" 41 "min speed rpm" 40 "min speed rpm" 39 "min speed rpm" 38 "min speed rpm" 37 "min speed rpm" 36 "min speed rpm" 35 "min speed rpm" 34 "min speed rpm" 33 "min speed rpm" 32 "min speed rpm" 31 "min speed rpm" 30 "min speed rpm" 29 "min speed rpm" 28 "min speed rpm" 27 "min speed rpm" 26 "min speed rpm" 25 "min speed rpm" 24 "min speed rpm" 23 "min speed rpm" 22 "min speed rpm" 21 "min speed rpm" 20 "min speed rpm" 19 "min speed rpm" 18 "min speed rpm" 17 "min speed rpm" 16 "min speed rpm" 15 "min speed rpm" 14 "min speed rpm" 13 "min speed rpm" 12 "min speed rpm" 11 "min speed rpm" 10 "min speed rpm" 9 "min speed rpm" 8 "min speed rpm" 7 "min speed rpm" 6 "min speed rpm" 5 "min speed rpm" 4 "min speed rpm" 3 "0 rpm" 2 "0 rpm" 1 "0 rpm" 0 "0 rpm";
VAL_ 552 EWP3_RPM_Target_EWP_Rq 255 "Invalid" 254 "max speed rpm" 253 "max speed rpm" 252 "max speed rpm" 251 "max speed rpm" 250 "linearly changed from min speed to max speed" 249 "linearly changed from min speed to max speed" 248 "linearly changed from min speed to max speed" 247 "linearly changed from min speed to max speed" 246 "linearly changed from min speed to max speed" 245 "linearly changed from min speed to max speed" 244 "linearly changed from min speed to max speed" 243 "linearly changed from min speed to max speed" 242 "linearly changed from min speed to max speed" 241 "linearly changed from min speed to max speed" 240 "linearly changed from min speed to max speed" 239 "linearly changed from min speed to max speed" 238 "linearly changed from min speed to max speed" 237 "linearly changed from min speed to max speed" 236 "linearly changed from min speed to max speed" 235 "linearly changed from min speed to max speed" 234 "linearly changed from min speed to max speed" 233 "linearly changed from min speed to max speed" 232 "linearly changed from min speed to max speed" 231 "linearly changed from min speed to max speed" 230 "linearly changed from min speed to max speed" 229 "linearly changed from min speed to max speed" 228 "linearly changed from min speed to max speed" 227 "linearly changed from min speed to max speed" 226 "linearly changed from min speed to max speed" 225 "linearly changed from min speed to max speed" 224 "linearly changed from min speed to max speed" 223 "linearly changed from min speed to max speed" 222 "linearly changed from min speed to max speed" 221 "linearly changed from min speed to max speed" 220 "linearly changed from min speed to max speed" 219 "linearly changed from min speed to max speed" 218 "linearly changed from min speed to max speed" 217 "linearly changed from min speed to max speed" 216 "linearly changed from min speed to max speed" 215 "linearly changed from min speed to max speed" 214 "linearly changed from min speed to max speed" 213 "linearly changed from min speed to max speed" 212 "linearly changed from min speed to max speed" 211 "linearly changed from min speed to max speed" 210 "linearly changed from min speed to max speed" 209 "linearly changed from min speed to max speed" 208 "linearly changed from min speed to max speed" 207 "linearly changed from min speed to max speed" 206 "linearly changed from min speed to max speed" 205 "linearly changed from min speed to max speed" 204 "linearly changed from min speed to max speed" 203 "linearly changed from min speed to max speed" 202 "linearly changed from min speed to max speed" 201 "linearly changed from min speed to max speed" 200 "linearly changed from min speed to max speed" 199 "linearly changed from min speed to max speed" 198 "linearly changed from min speed to max speed" 197 "linearly changed from min speed to max speed" 196 "linearly changed from min speed to max speed" 195 "linearly changed from min speed to max speed" 194 "linearly changed from min speed to max speed" 193 "linearly changed from min speed to max speed" 192 "linearly changed from min speed to max speed" 191 "linearly changed from min speed to max speed" 190 "linearly changed from min speed to max speed" 189 "linearly changed from min speed to max speed" 188 "linearly changed from min speed to max speed" 187 "linearly changed from min speed to max speed" 186 "linearly changed from min speed to max speed" 185 "linearly changed from min speed to max speed" 184 "linearly changed from min speed to max speed" 183 "linearly changed from min speed to max speed" 182 "linearly changed from min speed to max speed" 181 "linearly changed from min speed to max speed" 180 "linearly changed from min speed to max speed" 179 "linearly changed from min speed to max speed" 178 "linearly changed from min speed to max speed" 177 "linearly changed from min speed to max speed" 176 "linearly changed from min speed to max speed" 175 "linearly changed from min speed to max speed" 174 "linearly changed from min speed to max speed" 173 "linearly changed from min speed to max speed" 172 "linearly changed from min speed to max speed" 171 "linearly changed from min speed to max speed" 170 "linearly changed from min speed to max speed" 169 "linearly changed from min speed to max speed" 168 "linearly changed from min speed to max speed" 167 "linearly changed from min speed to max speed" 166 "linearly changed from min speed to max speed" 165 "linearly changed from min speed to max speed" 164 "linearly changed from min speed to max speed" 163 "linearly changed from min speed to max speed" 162 "linearly changed from min speed to max speed" 161 "linearly changed from min speed to max speed" 160 "linearly changed from min speed to max speed" 159 "linearly changed from min speed to max speed" 158 "linearly changed from min speed to max speed" 157 "linearly changed from min speed to max speed" 156 "linearly changed from min speed to max speed" 155 "linearly changed from min speed to max speed" 154 "linearly changed from min speed to max speed" 153 "linearly changed from min speed to max speed" 152 "linearly changed from min speed to max speed" 151 "linearly changed from min speed to max speed" 150 "linearly changed from min speed to max speed" 149 "linearly changed from min speed to max speed" 148 "linearly changed from min speed to max speed" 147 "linearly changed from min speed to max speed" 146 "linearly changed from min speed to max speed" 145 "linearly changed from min speed to max speed" 144 "linearly changed from min speed to max speed" 143 "linearly changed from min speed to max speed" 142 "linearly changed from min speed to max speed" 141 "linearly changed from min speed to max speed" 140 "linearly changed from min speed to max speed" 139 "linearly changed from min speed to max speed" 138 "linearly changed from min speed to max speed" 137 "linearly changed from min speed to max speed" 136 "linearly changed from min speed to max speed" 135 "linearly changed from min speed to max speed" 134 "linearly changed from min speed to max speed" 133 "linearly changed from min speed to max speed" 132 "linearly changed from min speed to max speed" 131 "linearly changed from min speed to max speed" 130 "linearly changed from min speed to max speed" 129 "linearly changed from min speed to max speed" 128 "linearly changed from min speed to max speed" 127 "linearly changed from min speed to max speed" 126 "linearly changed from min speed to max speed" 125 "linearly changed from min speed to max speed" 124 "linearly changed from min speed to max speed" 123 "linearly changed from min speed to max speed" 122 "linearly changed from min speed to max speed" 121 "linearly changed from min speed to max speed" 120 "linearly changed from min speed to max speed" 119 "linearly changed from min speed to max speed" 118 "linearly changed from min speed to max speed" 117 "linearly changed from min speed to max speed" 116 "linearly changed from min speed to max speed" 115 "linearly changed from min speed to max speed" 114 "linearly changed from min speed to max speed" 113 "linearly changed from min speed to max speed" 112 "linearly changed from min speed to max speed" 111 "linearly changed from min speed to max speed" 110 "linearly changed from min speed to max speed" 109 "linearly changed from min speed to max speed" 108 "linearly changed from min speed to max speed" 107 "linearly changed from min speed to max speed" 106 "linearly changed from min speed to max speed" 105 "linearly changed from min speed to max speed" 104 "linearly changed from min speed to max speed" 103 "linearly changed from min speed to max speed" 102 "linearly changed from min speed to max speed" 101 "linearly changed from min speed to max speed" 100 "linearly changed from min speed to max speed" 99 "linearly changed from min speed to max speed" 98 "linearly changed from min speed to max speed" 97 "linearly changed from min speed to max speed" 96 "linearly changed from min speed to max speed" 95 "linearly changed from min speed to max speed" 94 "linearly changed from min speed to max speed" 93 "linearly changed from min speed to max speed" 92 "linearly changed from min speed to max speed" 91 "linearly changed from min speed to max speed" 90 "linearly changed from min speed to max speed" 89 "linearly changed from min speed to max speed" 88 "linearly changed from min speed to max speed" 87 "linearly changed from min speed to max speed" 86 "linearly changed from min speed to max speed" 85 "linearly changed from min speed to max speed" 84 "linearly changed from min speed to max speed" 83 "linearly changed from min speed to max speed" 82 "linearly changed from min speed to max speed" 81 "linearly changed from min speed to max speed" 80 "linearly changed from min speed to max speed" 79 "linearly changed from min speed to max speed" 78 "linearly changed from min speed to max speed" 77 "linearly changed from min speed to max speed" 76 "linearly changed from min speed to max speed" 75 "linearly changed from min speed to max speed" 74 "linearly changed from min speed to max speed" 73 "linearly changed from min speed to max speed" 72 "linearly changed from min speed to max speed" 71 "linearly changed from min speed to max speed" 70 "linearly changed from min speed to max speed" 69 "linearly changed from min speed to max speed" 68 "linearly changed from min speed to max speed" 67 "linearly changed from min speed to max speed" 66 "linearly changed from min speed to max speed" 65 "linearly changed from min speed to max speed" 64 "linearly changed from min speed to max speed" 63 "linearly changed from min speed to max speed" 62 "linearly changed from min speed to max speed" 61 "linearly changed from min speed to max speed" 60 "linearly changed from min speed to max speed" 59 "linearly changed from min speed to max speed" 58 "linearly changed from min speed to max speed" 57 "linearly changed from min speed to max speed" 56 "linearly changed from min speed to max speed" 55 "linearly changed from min speed to max speed" 54 "linearly changed from min speed to max speed" 53 "linearly changed from min speed to max speed" 52 "linearly changed from min speed to max speed" 51 "linearly changed from min speed to max speed" 50 "linearly changed from min speed to max speed" 49 "min speed rpm" 48 "min speed rpm" 47 "min speed rpm" 46 "min speed rpm" 45 "min speed rpm" 44 "min speed rpm" 43 "min speed rpm" 42 "min speed rpm" 41 "min speed rpm" 40 "min speed rpm" 39 "min speed rpm" 38 "min speed rpm" 37 "min speed rpm" 36 "min speed rpm" 35 "min speed rpm" 34 "min speed rpm" 33 "min speed rpm" 32 "min speed rpm" 31 "min speed rpm" 30 "min speed rpm" 29 "min speed rpm" 28 "min speed rpm" 27 "min speed rpm" 26 "min speed rpm" 25 "min speed rpm" 24 "min speed rpm" 23 "min speed rpm" 22 "min speed rpm" 21 "min speed rpm" 20 "min speed rpm" 19 "min speed rpm" 18 "min speed rpm" 17 "min speed rpm" 16 "min speed rpm" 15 "min speed rpm" 14 "min speed rpm" 13 "min speed rpm" 12 "min speed rpm" 11 "min speed rpm" 10 "min speed rpm" 9 "min speed rpm" 8 "min speed rpm" 7 "min speed rpm" 6 "min speed rpm" 5 "min speed rpm" 4 "min speed rpm" 3 "0 rpm" 2 "0 rpm" 1 "0 rpm" 0 "0 rpm";
VAL_ 552 EWP1_RPM_Target_EWP_Rq 255 "Invalid" 254 "max speed rpm" 253 "max speed rpm" 252 "max speed rpm" 251 "max speed rpm" 250 "linearly changed from min speed to max speed" 249 "linearly changed from min speed to max speed" 248 "linearly changed from min speed to max speed" 247 "linearly changed from min speed to max speed" 246 "linearly changed from min speed to max speed" 245 "linearly changed from min speed to max speed" 244 "linearly changed from min speed to max speed" 243 "linearly changed from min speed to max speed" 242 "linearly changed from min speed to max speed" 241 "linearly changed from min speed to max speed" 240 "linearly changed from min speed to max speed" 239 "linearly changed from min speed to max speed" 238 "linearly changed from min speed to max speed" 237 "linearly changed from min speed to max speed" 236 "linearly changed from min speed to max speed" 235 "linearly changed from min speed to max speed" 234 "linearly changed from min speed to max speed" 233 "linearly changed from min speed to max speed" 232 "linearly changed from min speed to max speed" 231 "linearly changed from min speed to max speed" 230 "linearly changed from min speed to max speed" 229 "linearly changed from min speed to max speed" 228 "linearly changed from min speed to max speed" 227 "linearly changed from min speed to max speed" 226 "linearly changed from min speed to max speed" 225 "linearly changed from min speed to max speed" 224 "linearly changed from min speed to max speed" 223 "linearly changed from min speed to max speed" 222 "linearly changed from min speed to max speed" 221 "linearly changed from min speed to max speed" 220 "linearly changed from min speed to max speed" 219 "linearly changed from min speed to max speed" 218 "linearly changed from min speed to max speed" 217 "linearly changed from min speed to max speed" 216 "linearly changed from min speed to max speed" 215 "linearly changed from min speed to max speed" 214 "linearly changed from min speed to max speed" 213 "linearly changed from min speed to max speed" 212 "linearly changed from min speed to max speed" 211 "linearly changed from min speed to max speed" 210 "linearly changed from min speed to max speed" 209 "linearly changed from min speed to max speed" 208 "linearly changed from min speed to max speed" 207 "linearly changed from min speed to max speed" 206 "linearly changed from min speed to max speed" 205 "linearly changed from min speed to max speed" 204 "linearly changed from min speed to max speed" 203 "linearly changed from min speed to max speed" 202 "linearly changed from min speed to max speed" 201 "linearly changed from min speed to max speed" 200 "linearly changed from min speed to max speed" 199 "linearly changed from min speed to max speed" 198 "linearly changed from min speed to max speed" 197 "linearly changed from min speed to max speed" 196 "linearly changed from min speed to max speed" 195 "linearly changed from min speed to max speed" 194 "linearly changed from min speed to max speed" 193 "linearly changed from min speed to max speed" 192 "linearly changed from min speed to max speed" 191 "linearly changed from min speed to max speed" 190 "linearly changed from min speed to max speed" 189 "linearly changed from min speed to max speed" 188 "linearly changed from min speed to max speed" 187 "linearly changed from min speed to max speed" 186 "linearly changed from min speed to max speed" 185 "linearly changed from min speed to max speed" 184 "linearly changed from min speed to max speed" 183 "linearly changed from min speed to max speed" 182 "linearly changed from min speed to max speed" 181 "linearly changed from min speed to max speed" 180 "linearly changed from min speed to max speed" 179 "linearly changed from min speed to max speed" 178 "linearly changed from min speed to max speed" 177 "linearly changed from min speed to max speed" 176 "linearly changed from min speed to max speed" 175 "linearly changed from min speed to max speed" 174 "linearly changed from min speed to max speed" 173 "linearly changed from min speed to max speed" 172 "linearly changed from min speed to max speed" 171 "linearly changed from min speed to max speed" 170 "linearly changed from min speed to max speed" 169 "linearly changed from min speed to max speed" 168 "linearly changed from min speed to max speed" 167 "linearly changed from min speed to max speed" 166 "linearly changed from min speed to max speed" 165 "linearly changed from min speed to max speed" 164 "linearly changed from min speed to max speed" 163 "linearly changed from min speed to max speed" 162 "linearly changed from min speed to max speed" 161 "linearly changed from min speed to max speed" 160 "linearly changed from min speed to max speed" 159 "linearly changed from min speed to max speed" 158 "linearly changed from min speed to max speed" 157 "linearly changed from min speed to max speed" 156 "linearly changed from min speed to max speed" 155 "linearly changed from min speed to max speed" 154 "linearly changed from min speed to max speed" 153 "linearly changed from min speed to max speed" 152 "linearly changed from min speed to max speed" 151 "linearly changed from min speed to max speed" 150 "linearly changed from min speed to max speed" 149 "linearly changed from min speed to max speed" 148 "linearly changed from min speed to max speed" 147 "linearly changed from min speed to max speed" 146 "linearly changed from min speed to max speed" 145 "linearly changed from min speed to max speed" 144 "linearly changed from min speed to max speed" 143 "linearly changed from min speed to max speed" 142 "linearly changed from min speed to max speed" 141 "linearly changed from min speed to max speed" 140 "linearly changed from min speed to max speed" 139 "linearly changed from min speed to max speed" 138 "linearly changed from min speed to max speed" 137 "linearly changed from min speed to max speed" 136 "linearly changed from min speed to max speed" 135 "linearly changed from min speed to max speed" 134 "linearly changed from min speed to max speed" 133 "linearly changed from min speed to max speed" 132 "linearly changed from min speed to max speed" 131 "linearly changed from min speed to max speed" 130 "linearly changed from min speed to max speed" 129 "linearly changed from min speed to max speed" 128 "linearly changed from min speed to max speed" 127 "linearly changed from min speed to max speed" 126 "linearly changed from min speed to max speed" 125 "linearly changed from min speed to max speed" 124 "linearly changed from min speed to max speed" 123 "linearly changed from min speed to max speed" 122 "linearly changed from min speed to max speed" 121 "linearly changed from min speed to max speed" 120 "linearly changed from min speed to max speed" 119 "linearly changed from min speed to max speed" 118 "linearly changed from min speed to max speed" 117 "linearly changed from min speed to max speed" 116 "linearly changed from min speed to max speed" 115 "linearly changed from min speed to max speed" 114 "linearly changed from min speed to max speed" 113 "linearly changed from min speed to max speed" 112 "linearly changed from min speed to max speed" 111 "linearly changed from min speed to max speed" 110 "linearly changed from min speed to max speed" 109 "linearly changed from min speed to max speed" 108 "linearly changed from min speed to max speed" 107 "linearly changed from min speed to max speed" 106 "linearly changed from min speed to max speed" 105 "linearly changed from min speed to max speed" 104 "linearly changed from min speed to max speed" 103 "linearly changed from min speed to max speed" 102 "linearly changed from min speed to max speed" 101 "linearly changed from min speed to max speed" 100 "linearly changed from min speed to max speed" 99 "linearly changed from min speed to max speed" 98 "linearly changed from min speed to max speed" 97 "linearly changed from min speed to max speed" 96 "linearly changed from min speed to max speed" 95 "linearly changed from min speed to max speed" 94 "linearly changed from min speed to max speed" 93 "linearly changed from min speed to max speed" 92 "linearly changed from min speed to max speed" 91 "linearly changed from min speed to max speed" 90 "linearly changed from min speed to max speed" 89 "linearly changed from min speed to max speed" 88 "linearly changed from min speed to max speed" 87 "linearly changed from min speed to max speed" 86 "linearly changed from min speed to max speed" 85 "linearly changed from min speed to max speed" 84 "linearly changed from min speed to max speed" 83 "linearly changed from min speed to max speed" 82 "linearly changed from min speed to max speed" 81 "linearly changed from min speed to max speed" 80 "linearly changed from min speed to max speed" 79 "linearly changed from min speed to max speed" 78 "linearly changed from min speed to max speed" 77 "linearly changed from min speed to max speed" 76 "linearly changed from min speed to max speed" 75 "linearly changed from min speed to max speed" 74 "linearly changed from min speed to max speed" 73 "linearly changed from min speed to max speed" 72 "linearly changed from min speed to max speed" 71 "linearly changed from min speed to max speed" 70 "linearly changed from min speed to max speed" 69 "linearly changed from min speed to max speed" 68 "linearly changed from min speed to max speed" 67 "linearly changed from min speed to max speed" 66 "linearly changed from min speed to max speed" 65 "linearly changed from min speed to max speed" 64 "linearly changed from min speed to max speed" 63 "linearly changed from min speed to max speed" 62 "linearly changed from min speed to max speed" 61 "linearly changed from min speed to max speed" 60 "linearly changed from min speed to max speed" 59 "linearly changed from min speed to max speed" 58 "linearly changed from min speed to max speed" 57 "linearly changed from min speed to max speed" 56 "linearly changed from min speed to max speed" 55 "linearly changed from min speed to max speed" 54 "linearly changed from min speed to max speed" 53 "linearly changed from min speed to max speed" 52 "linearly changed from min speed to max speed" 51 "linearly changed from min speed to max speed" 50 "linearly changed from min speed to max speed" 49 "min speed rpm" 48 "min speed rpm" 47 "min speed rpm" 46 "min speed rpm" 45 "min speed rpm" 44 "min speed rpm" 43 "min speed rpm" 42 "min speed rpm" 41 "min speed rpm" 40 "min speed rpm" 39 "min speed rpm" 38 "min speed rpm" 37 "min speed rpm" 36 "min speed rpm" 35 "min speed rpm" 34 "min speed rpm" 33 "min speed rpm" 32 "min speed rpm" 31 "min speed rpm" 30 "min speed rpm" 29 "min speed rpm" 28 "min speed rpm" 27 "min speed rpm" 26 "min speed rpm" 25 "min speed rpm" 24 "min speed rpm" 23 "min speed rpm" 22 "min speed rpm" 21 "min speed rpm" 20 "min speed rpm" 19 "min speed rpm" 18 "min speed rpm" 17 "min speed rpm" 16 "min speed rpm" 15 "min speed rpm" 14 "min speed rpm" 13 "min speed rpm" 12 "min speed rpm" 11 "min speed rpm" 10 "min speed rpm" 9 "min speed rpm" 8 "min speed rpm" 7 "min speed rpm" 6 "min speed rpm" 5 "min speed rpm" 4 "min speed rpm" 3 "0 rpm" 2 "0 rpm" 1 "0 rpm" 0 "0 rpm";
VAL_ 552 EXV_Cmd_Init_Rq 7 "not defined" 6 "not defined" 5 "not defined" 4 "not defined" 3 "not defined" 2 "waiting for Sequence to finish" 1 "start Init-Sequence" 0 "No Request";
VAL_ 552 EXV2_Cmd_Init_Rq 7 "not defined" 6 "not defined" 5 "not defined" 4 "not defined" 3 "not defined" 2 "waiting for Sequence to finish" 1 "start Init-Sequence" 0 "No Request";
VAL_ 552 EXV2_Cmd_Move_Enbl 1 "Move to Commanded Position" 0 "Ignore Commanded Position";
VAL_ 552 EXV_Cmd_Move_Enbl 1 "Move to Commanded Position" 0 "Ignore Commanded Position";
VAL_ 552 EWP2_Default_Operation_EWP_Rq 1 "Default Operation" 0 "Default Sleep";
VAL_ 552 BDC_1_MoveEnable 1 "ReqMotorMove" 0 "NoReq";
VAL_ 552 EWP3_Default_Operation_EWP_Rq 1 "Default Operation" 0 "Default Sleep";
VAL_ 552 EWP1_Default_Operation_EWP_Rq 1 "Default Operation" 0 "Default Sleep";
VAL_ 552 CCV4_ReqMovePos 1 "Open Port 1 to Port 4, Port 2 to port 3" 0 "Open Port 1 to Port 2, Port 3 to port 4";
VAL_ 552 CCV4_MoveEnable 1 "ReqMotorMove" 0 "NoReq";
VAL_ 554 EACProtectEnable 2 "level2" 1 "level1" 0 "off";
VAL_ 554 FWV_Err 2 "reserved" 1 "fault" 0 "normal";
VAL_ 554 TWV_Err 2 "reserved" 1 "fault" 0 "normal";
VAL_ 554 EWP3_Err 2 "reserved" 1 "fault" 0 "normal";
VAL_ 554 EWP2_Err 2 "reserved" 1 "fault" 0 "normal";
VAL_ 554 EWP1_Err 2 "reserved" 1 "fault" 0 "normal";
VAL_ 554 WPTC_Err 2 "reserved" 1 "fault" 0 "normal";
VAL_ 554 AGS_Err 2 "reserved" 1 "fault" 0 "normal";
VAL_ 554 Fan_Err 2 "reserved" 1 "fault" 0 "normal";
VAL_ 554 EXV2_Err 2 "reserved" 1 "fault" 0 "normal";
VAL_ 554 EXV1_Err 2 "reserved" 1 "fault" 0 "normal";
VAL_ 554 SOTXV_Err 2 "reserved" 1 "fault" 0 "normal";
VAL_ 554 COMP_Err 2 "reserved" 1 "fault" 0 "normal";
VAL_ 554 SOV3_Err 2 "reserved" 1 "fault" 0 "normal";
VAL_ 554 SOV2_Err 2 "reserved" 1 "fault" 0 "normal";
VAL_ 554 SOV1_Err 2 "reserved" 1 "fault" 0 "normal";
VAL_ 554 PT_High_Tact_Err 2 "reserved" 1 "fault" 0 "normal";
VAL_ 554 PT_High_P_Err 2 "level2" 1 "level1" 0 "off";
VAL_ 554 PT_Low_T2_Err 2 "reserved" 1 "fault" 0 "normal";
VAL_ 554 PT_Low_P2_Err 2 "reserved" 1 "fault" 0 "normal";
VAL_ 554 PT_Low_T1_Err 2 "reserved" 1 "fault" 0 "normal";
VAL_ 554 PT_Low_P1_Err 2 "reserved" 1 "fault" 0 "normal";
VAL_ 554 Motor_Out_Temp_Err 2 "reserved" 1 "fault" 0 "normal";
VAL_ 554 Bat_Out_Temp_Err 2 "reserved" 1 "fault" 0 "normal";
VAL_ 554 Motor_In_Temp_Err 2 "reserved" 1 "fault" 0 "normal";
VAL_ 554 Bat_In_Temp_Err 2 "reserved" 1 "fault" 0 "normal";
VAL_ 554 Tamb_Err 2 "reserved" 1 "fault" 0 "normal";
VAL_ 570 HazardWarningReq 1 "Request" 0 "No Request";
VAL_ 570 ADAS_AEB_Sta 4 "Disable" 3 "Error" 2 "Active" 1 "Standby" 0 "Off";
VAL_ 570 RightTurnLightReq 1 "Request" 0 "No Request";
VAL_ 570 ADAS_FCW_Sta 4 "Disable" 3 "Error" 2 "Active" 1 "Standby" 0 "Off";
VAL_ 570 LeftTurnLightReq 1 "Request" 0 "No Request";
VAL_ 570 ADAS_LDW_Sta 6 "Disable" 5 "Error" 4 "Right warning" 3 "Left warning" 2 "Active" 1 "Standby" 0 "Off";
VAL_ 570 ADAS_FltWrnReq 1 "Warning Request" 0 "No Warning";
VAL_ 570 ADAS_ACC_Sta 6 "Disable" 5 "Error" 4 "Shut-off" 3 "Override" 2 "Active" 1 "Standby" 0 "Off";
VAL_ 570 ACC_ObjDstLvl 4 "Level 4" 3 "Level 3" 2 "Level 2" 1 "Level 1" 0 "None";
VAL_ 570 ForceLowBeam 2 "Invalid" 1 "Force Low Beam" 0 "No Request";
VAL_ 570 TimeGapLevel 4 "Level 4" 3 "Level 3" 2 "Level 2" 1 "Level 1" 0 "Off";
VAL_ 570 ACCSetSpeed_Disp 3 "Green" 2 "Grey" 1 "Dash Line" 0 "None";
VAL_ 570 ACC_TakeoverReq 1 "request" 0 "no request";
VAL_ 570 ADAS_WarningMsg 15 "reserve" 14 "reserve" 13 "reserve" 12 "reserve" 11 "reserve" 10 "reserve" 9 "reserve" 8 "reserve" 7 "Takeover Request" 6 "Disable to Engage FSRA" 5 "FSRA Disengaged" 4 "Available to resume Acceleration Control" 3 "Object Disappeared" 2 "reserve" 1 "reserve" 0 "None";
VAL_ 570 ADAS_CAM_SpdLim 31 "80mph" 30 "75mph" 29 "70mph" 28 "65mph" 27 "60mph" 26 "55mph" 25 "50mph" 24 "45mph" 23 "40mph" 22 "35mph" 21 "30mph" 20 "25mph" 19 "20mph" 18 "15mph" 17 "10mph" 16 "160 km/h" 15 "150 km/h" 14 "140 km/h" 13 "130 km/h" 12 "120 km/h" 11 "110 km/h" 10 "100 km/h" 9 "90 km/h" 8 "80 km/h" 7 "70 km/h" 6 "60 km/h" 5 "50 km/h" 4 "40 km/h" 3 "30 km/h" 2 "20 km/h" 1 "10 km/h" 0 "No request";
VAL_ 570 Target_Type 4 "Truck" 3 "Two Wheel" 2 "Vehicle" 1 "Pedestrian" 0 "None";
VAL_ 570 ADAS_SLIF_SpdLim 31 "80mph" 30 "75mph" 29 "70mph" 28 "65mph" 27 "60mph" 26 "55mph" 25 "50mph" 24 "45mph" 23 "40mph" 22 "35mph" 21 "30mph" 20 "25mph" 19 "20mph" 18 "15mph" 17 "10mph" 16 "160 km/h" 15 "150 km/h" 14 "140 km/h" 13 "130 km/h" 12 "120 km/h" 11 "110 km/h" 10 "100 km/h" 9 "90 km/h" 8 "80 km/h" 7 "70 km/h" 6 "60 km/h" 5 "50 km/h" 4 "40 km/h" 3 "30 km/h" 2 "20 km/h" 1 "10 km/h" 0 "No request";
VAL_ 572 LKA_HOD_Display_Warning 1 "Hands-off Warning" 0 "No Warning";
VAL_ 572 ADAS_LKA_Sta 6 "Disable" 5 "Error" 4 "Right Assist" 3 "Left Assist" 2 "Active" 1 "Standby" 0 "Off";
VAL_ 572 LKA_HOD_Sound_Warning 1 "Hands-off Warning" 0 "No Warning";
VAL_ 572 ADAS_LFC_Sta 5 "Disable" 4 "Error" 3 "Green Blinking" 2 "Green" 1 "White" 0 "OFF";
VAL_ 572 ADAS_LaneModeL 1 "Detected" 0 "Not detected";
VAL_ 572 ADAS_LaneModeR 1 "Detected" 0 "Not detected";
VAL_ 572 ADAS_SLIF_Sta 5 "Disable" 4 "Invalid" 3 "Temporary Unavailable" 2 "System Fail" 1 "Normal (Default)" 0 "OFF";
VAL_ 572 ADAS_ISA_Sta 3 "Disable" 2 "Error" 1 "Active" 0 "Off";
VAL_ 572 ADAS_LDW_Mute 1 "Mute" 0 "No Mute";
VAL_ 572 ADAS_FCW_Mute 1 "Mute" 0 "No Mute";
VAL_ 572 ADAS_LFC_Hands_Off_Warning 3 "Automatic release warning" 2 "2nd Warning" 1 "1st Warning" 0 "OFF";
VAL_ 572 LVDA_Disabled 1 "Disabled" 0 "Enabled";
VAL_ 572 LVDA_Mute_Sta 3 "Invalid" 2 "Mute" 1 "No Mute" 0 "Default";
VAL_ 572 LVDA_Failinfo 1 "Fail" 0 "No fail";
VAL_ 572 LVDA_Warning 1 "Warning" 0 "No warning";
VAL_ 572 LVDA_ACCStatusInformation 1 "ACC is in stop-hold mode" 0 "Default";
VAL_ 572 ADAS_LFC_Warn_Sound 1 "Warning Sound" 0 "OFF";
VAL_ 593 P_CommandToBCM 8 "Invalid" 7 "Forced to lift anti-theft" 6 "HandleTailgate Open/Close" 5 "Failed to Lock Tailgate" 4 "Car Search" 3 "Remote Tailgate Open/Close" 2 "Unlock" 1 "Lock" 0 "Default";
VAL_ 593 P_DKey_Welcome 3 "UnsedandReserved" 2 "Out the welcome zone" 1 "In the welcom zone" 0 "Unavaliable";
VAL_ 593 P_DKey_Area_LockUnlock 3 "UnusedandReserved" 2 "In to Unlock Zone" 1 "In to Lock Zone" 0 "Unavailable";
VAL_ 593 P_DKey_Area_PS 3 "UnsedandReserved" 2 "Out of PS Zone" 1 "In to PS Zone" 0 "Unavaliable";
VAL_ 593 P_UID_LowPower 1 "On" 0 "Off";
VAL_ 593 P_CommandToPTG 5 "invalid" 4 "PTG-legal Key in Indoor and Outdoor(ID identical)" 3 "PTG-legal Key in Indoor and Outdoor(ID different)" 2 "PTG-legal Key in Indoor" 1 "PTG-legal Key in Outdoor" 0 "Default";
VAL_ 593 P_Dkey_Show_IVI 7 "invalid" 6 "IVI PHONE Green" 5 "IVI PHONE Red" 4 "IVI UID Green" 3 "IVI UID Red" 2 "IVI NFC Card Green" 1 "IVI NFC Card Red" 0 "Default";
VAL_ 593 P_KeyMode 6 "Invalid" 5 "NFC" 4 "PHONE (BLE)" 3 "PHONE (UWB)" 2 "UID (BLE)" 1 "UID (UWB)" 0 "Default";
VAL_ 593 P_DKey_Area_PTG 3 "UnsedandReserved" 2 "Out of SPTG Zone" 1 "In to SPTG Zone" 0 "Unavaliable";
VAL_ 593 P_KeyMiss 1 "Key Miss" 0 "Default";
VAL_ 593 DKC_Remote_PW 16 "App 4Door AutoDown" 15 "App 4Door AutoUP" 14 "Stop" 13 "App RR ManualDown" 12 "App RL ManualDown" 11 "App FR ManualDown" 10 "App FL ManualDown" 9 "App 4Door ManualD" 8 "App RRAutoDown" 7 "App RRAutoUP" 6 "App RLAutoDown" 5 "App RLAutoUP" 4 "App FRAutoDown" 3 "App FRAutoUP" 2 "App FLAutoDown" 1 "App FLAutoUP" 0 "release";
VAL_ 593 DKC_Re_VehData 1 "Request" 0 "No Request";
VAL_ 595 IVI_Located_STA 3 "Not Used" 2 "3D fix" 1 "2D fix" 0 "No fix";
VAL_ 595 IVI_PTG_USSta_SW 1 "Off" 0 "On";
VAL_ 595 IVI_PTG_Open_Height 7 "Invalid" 6 "Invalid" 5 "Invalid" 4 "Set by User" 3 "Lv3(80%)" 2 "Lv2(60%)" 1 "Lv1(40%)" 0 "Full Open";
VAL_ 595 Approach_Unlock_SW 1 "ON" 0 "OFF";
VAL_ 595 Walkaway_Lock_SW 1 "ON" 0 "OFF";
VAL_ 595 BrkSw_Sta 1 "Active" 0 "Inactive";
VAL_ 595 DSEAT_anti_set 1 "ON" 0 "OFF";
VAL_ 595 DSEAT_entryfun_set 1 "ON" 0 "OFF";
VAL_ 595 IVI_PTG_Mode_SW 2 "Invalid" 1 "Press" 0 "No Request";
VAL_ 595 PSEAT_vent_req 4 "OFF" 3 "Vent3" 2 "Vent2" 1 "Vent1" 0 "No request";
VAL_ 595 IVI_PTG_Sta_SW 2 "Invalid" 1 "Press" 0 "Release";
VAL_ 595 IVI_ISA_OffsetSpd 15 "Invalid" 14 "reserve" 13 "reserve" 12 "reserve" 11 "5 mph" 10 "0 mph" 9 "-5 mph" 8 "reserve" 7 "reserve" 6 "reserve" 5 "+10 km/h" 4 "+5 km/h" 3 "0 km/h" 2 "-5 km/h" 1 "-10 km/h" 0 "Off";
VAL_ 595 SenstivityPosition 15 "not used" 14 "not used" 13 "not used" 12 "not used" 11 "not used" 10 "not used" 9 "not used" 8 "not used" 7 "not used" 6 "not used" 5 "not used" 4 "senstivity level-4" 3 "senstivity level-3" 2 "senstivity level-2" 1 "senstivity level-1" 0 "not used";
VAL_ 595 Hood_Latch_SW 2 "invalid" 1 "Press" 0 "No Request";
VAL_ 595 TurnSwTimeSet 3 "Undefiend" 2 "7 times" 1 "5 times" 0 "3 times";
VAL_ 595 DSEAT_vent_req 7 "Not used" 6 "Not used" 5 "Not used" 4 "OFF" 3 "High" 2 "Middle" 1 "Low" 0 "No request";
VAL_ 595 HeadLampSW 3 "OFF" 2 "Low beam" 1 "Postion lamp" 0 "AUTO";
VAL_ 595 IVI_Time_Month 15 "Not Used" 14 "Not Used" 13 "Not Used" 0 "invalid";
VAL_ 595 PTG_Inner_SW2 3 "Stuck" 2 "Press&Hold" 1 "Push" 0 "Off";
VAL_ 595 L_Drv_CtrlCmd 127 "No Request" 100 "Max" 0 "Min";
VAL_ 595 L_Pas_CtrlCmd 127 "No Request" 100 "Max" 0 "Min";
VAL_ 595 L_RLD_CtrlCmd 127 "No Request" 100 "Max" 0 "Min";
VAL_ 595 L_RRD_CtrlCmd 127 "No Request" 100 "Max" 0 "Min";
VAL_ 595 OFF_AC_MODE 7 "Invalid" 3 "CAMP" 2 "Pet" 1 "ON" 0 "OFF";
VAL_ 595 BrkSw_V 1 "Invalid" 0 "Valid";
VAL_ 595 MCPressure_V 1 "Invalid" 0 "Valid";
VAL_ 595 BrkPedalPos_Sta 1 "Valid" 0 "Invalid";
VAL_ 595 FDC_BCM_LockAlarm_Cmd 2 "Lock Fail" 1 "Lock" 0 "No Request";
VAL_ 595 FDC_THCM_ACTInitial_Cmd 1 "Initial Request" 0 "No Request";
VAL_ 595 FDC_BCM_ATCtrl_Cmd 2 "Unlock" 1 "Lock" 0 "Stand By";
VAL_ 595 FDC_BCM_OutMode_Cmd 9 "PTG Flash Twice" 8 "SPTG Detecting" 7 "ESS_Active" 6 "Antitheft Alarm" 5 "Unlock or PTG Flash 3 times" 4 "Lock" 3 "Hazard" 2 "Right Turn Lamp" 1 "Left Turn Lamp" 0 "Stand By";
